VERSION "dbc-export 1 2026.26.6.5"

NS_ :

BS_:

BU_: ADSP APB APP APS APSB BB BMS CC CMP CMPD CP DAS DI DIF DIR DPB EPAS3P EPAS3S EPASTP EPASTS EPBL EPBR ESP EVSE FC GTW HCML HCMR HVP IBST ICR IDB LS OCS1P PARK PCS PCS2 PM PMF PMR PNCD PTC RADC RCM RCM2 RCM3 RCU SCCM SCM SCS SDCR TAS TCU TCU2 TPMS TRCM UI UIS UMC USM V2G VC VCBATT VCBATT0 VCBATT1 VCBATT2 VCCC VCFRONT VCFRONT1 VCFRONT2 VCLEFT VCRIGHT VCSEAT2L VCSEAT2R VCSEC VEH

BO_ 981 ESP_alertMatrix: 8 ESP
 SG_ ESP_matrixIndex M : 0|4@1+ (1,0) [0|15] "" Vector__XXX
 SG_ ESP_a001_ecuGenericFault m0 : 4|1@1+ (1,0) [0|1] "" Vector__XXX
 SG_ ESP_a002_valvesGenericFault m0 : 5|1@1+ (1,0) [0|1] "" Vector__XXX
 SG_ ESP_a003_outletValvesFault m0 : 6|1@1+ (1,0) [0|1] "" Vector__XXX
 SG_ ESP_a004_inletValvesFault m0 : 7|1@1+ (1,0) [0|1] "" Vector__XXX
 SG_ ESP_a005_HSVValvesFault m0 : 8|1@1+ (1,0) [0|1] "" Vector__XXX
 SG_ ESP_a006_USVValvesFault m0 : 9|1@1+ (1,0) [0|1] "" Vector__XXX
 SG_ ESP_a007_pumpMotorFault m0 : 10|1@1+ (1,0) [0|1] "" Vector__XXX
 SG_ ESP_a008_pumpMotor12VsupplyLow m0 : 11|1@1+ (1,0) [0|1] "" Vector__XXX
 SG_ ESP_a009_12VHardUndervoltage m0 : 12|1@1+ (1,0) [0|1] "" Vector__XXX
 SG_ ESP_a010_12VUndervoltage m0 : 13|1@1+ (1,0) [0|1] "" Vector__XXX
 SG_ ESP_a011_12VSystemUndervoltage m0 : 14|1@1+ (1,0) [0|1] "" Vector__XXX
 SG_ ESP_a012_netUndervoltage m0 : 15|1@1+ (1,0) [0|1] "" Vector__XXX
 SG_ ESP_a013_valveRelayUndervoltage m0 : 16|1@1+ (1,0) [0|1] "" Vector__XXX
 SG_ ESP_a014_WSSSupplyUndervoltage m0 : 17|1@1+ (1,0) [0|1] "" Vector__XXX
 SG_ ESP_a015_12VSupplyOvervoltage m0 : 18|1@1+ (1,0) [0|1] "" Vector__XXX
 SG_ ESP_a016_12VSystemOvervoltage m0 : 19|1@1+ (1,0) [0|1] "" Vector__XXX
 SG_ ESP_a017_netOvervoltage m0 : 20|1@1+ (1,0) [0|1] "" Vector__XXX
 SG_ ESP_a018_WSSSignFrontAxle m0 : 21|1@1+ (1,0) [0|1] "" Vector__XXX
 SG_ ESP_a019_WSSSignRearAxle m0 : 22|1@1+ (1,0) [0|1] "" Vector__XXX
 SG_ ESP_a020_WSSGenericTempFault m0 : 23|1@1+ (1,0) [0|1] "" Vector__XXX
 SG_ ESP_a021_WSSGeneralVDiffFault m0 : 24|1@1+ (1,0) [0|1] "" Vector__XXX
 SG_ ESP_a022_WSSDirectionFault m0 : 25|1@1+ (1,0) [0|1] "" Vector__XXX
 SG_ ESP_a023_WSSSeveralSuspected m0 : 26|1@1+ (1,0) [0|1] "" Vector__XXX
 SG_ ESP_a024_WSSReverseCurrent m0 : 27|1@1+ (1,0) [0|1] "" Vector__XXX
 SG_ ESP_a025_FrLWSSOpenOrShortToGnd m0 : 28|1@1+ (1,0) [0|1] "" Vector__XXX
 SG_ ESP_a026_FrLWSSShortTo12V m0 : 29|1@1+ (1,0) [0|1] "" Vector__XXX
 SG_ ESP_a027_FrLWSSLineInterruption m0 : 30|1@1+ (1,0) [0|1] "" Vector__XXX
 SG_ ESP_a028_FrLWSSMaxSpeedExceeded m0 : 31|1@1+ (1,0) [0|1] "" Vector__XXX
 SG_ ESP_a029_FrLWSSTooManyPulses m0 : 32|1@1+ (1,0) [0|1] "" Vector__XXX
 SG_ ESP_a030_FrLWSSLostSignal m0 : 33|1@1+ (1,0) [0|1] "" Vector__XXX
 SG_ ESP_a031_FrLWSSNoPulsesDetected m0 : 34|1@1+ (1,0) [0|1] "" Vector__XXX
 SG_ ESP_a032_FrLWSSWrongSensorType m0 : 35|1@1+ (1,0) [0|1] "" Vector__XXX
 SG_ ESP_a033_FrLWSSSignalNoise m0 : 36|1@1+ (1,0) [0|1] "" Vector__XXX
 SG_ ESP_a034_FrLWSSVDiffFault m0 : 37|1@1+ (1,0) [0|1] "" Vector__XXX
 SG_ ESP_a035_FrLWSSDirectionFault m0 : 38|1@1+ (1,0) [0|1] "" Vector__XXX
 SG_ ESP_a036_FrLWSSLargeAirGap m0 : 39|1@1+ (1,0) [0|1] "" Vector__XXX
 SG_ ESP_a037_FrLWSSSupplyShortToGnd m0 : 40|1@1+ (1,0) [0|1] "" Vector__XXX
 SG_ ESP_a038_FrLWSSGeneralFault m0 : 41|1@1+ (1,0) [0|1] "" Vector__XXX
 SG_ ESP_a039_FrRWSSOpenOrShortToGnd m0 : 42|1@1+ (1,0) [0|1] "" Vector__XXX
 SG_ ESP_a040_FrRWSSShortTo12V m0 : 43|1@1+ (1,0) [0|1] "" Vector__XXX
 SG_ ESP_a041_FrRWSSLineInterruption m0 : 44|1@1+ (1,0) [0|1] "" Vector__XXX
 SG_ ESP_a042_FrRWSSMaxSpeedExceeded m0 : 45|1@1+ (1,0) [0|1] "" Vector__XXX
 SG_ ESP_a043_FrRWSSTooManyPulses m0 : 46|1@1+ (1,0) [0|1] "" Vector__XXX
 SG_ ESP_a044_FrRWSSLostSignal m0 : 47|1@1+ (1,0) [0|1] "" Vector__XXX
 SG_ ESP_a045_FrRWSSNoPulsesDetected m0 : 48|1@1+ (1,0) [0|1] "" Vector__XXX
 SG_ ESP_a046_FrRWSSWrongSensorType m0 : 49|1@1+ (1,0) [0|1] "" Vector__XXX
 SG_ ESP_a047_FrRWSSSignalNoise m0 : 50|1@1+ (1,0) [0|1] "" Vector__XXX
 SG_ ESP_a048_FrRWSSVDiffFault m0 : 51|1@1+ (1,0) [0|1] "" Vector__XXX
 SG_ ESP_a049_FrRWSSDirectionFault m0 : 52|1@1+ (1,0) [0|1] "" Vector__XXX
 SG_ ESP_a050_FrRWSSLargeAirGap m0 : 53|1@1+ (1,0) [0|1] "" Vector__XXX
 SG_ ESP_a051_FrRWSSSupplyShortToGnd m0 : 54|1@1+ (1,0) [0|1] "" Vector__XXX
 SG_ ESP_a052_FrRWSSGeneralFault m0 : 55|1@1+ (1,0) [0|1] "" Vector__XXX
 SG_ ESP_a053_ReLWSSOpenOrShortToGnd m0 : 56|1@1+ (1,0) [0|1] "" Vector__XXX
 SG_ ESP_a054_ReLWSSShortTo12V m0 : 57|1@1+ (1,0) [0|1] "" Vector__XXX
 SG_ ESP_a055_ReLWSSLineInterruption m0 : 58|1@1+ (1,0) [0|1] "" Vector__XXX
 SG_ ESP_a056_ReLWSSMaxSpeedExceeded m0 : 59|1@1+ (1,0) [0|1] "" Vector__XXX
 SG_ ESP_a057_ReLWSSTooManyPulses m0 : 60|1@1+ (1,0) [0|1] "" Vector__XXX
 SG_ ESP_a058_ReLWSSLostSignal m0 : 61|1@1+ (1,0) [0|1] "" Vector__XXX
 SG_ ESP_a059_ReLWSSNoPulsesDetected m0 : 62|1@1+ (1,0) [0|1] "" Vector__XXX
 SG_ ESP_a060_ReLWSSWrongSensorType m0 : 63|1@1+ (1,0) [0|1] "" Vector__XXX
 SG_ ESP_a061_ReLWSSSignalNoise m1 : 4|1@1+ (1,0) [0|1] "" Vector__XXX
 SG_ ESP_a062_ReLWSSVDiffFault m1 : 5|1@1+ (1,0) [0|1] "" Vector__XXX
 SG_ ESP_a063_ReLWSSDirectionFault m1 : 6|1@1+ (1,0) [0|1] "" Vector__XXX
 SG_ ESP_a064_ReLWSSLargeAirGap m1 : 7|1@1+ (1,0) [0|1] "" Vector__XXX
 SG_ ESP_a065_ReLWSSSupplyShortToGnd m1 : 8|1@1+ (1,0) [0|1] "" Vector__XXX
 SG_ ESP_a066_ReLWSSGeneralFault m1 : 9|1@1+ (1,0) [0|1] "" Vector__XXX
 SG_ ESP_a067_ReRWSSOpenOrShortToGnd m1 : 10|1@1+ (1,0) [0|1] "" Vector__XXX
 SG_ ESP_a068_ReRWSSShortTo12V m1 : 11|1@1+ (1,0) [0|1] "" Vector__XXX
 SG_ ESP_a069_ReRWSSLineInterruption m1 : 12|1@1+ (1,0) [0|1] "" Vector__XXX
 SG_ ESP_a070_ReRWSSMaxSpeedExceeded m1 : 13|1@1+ (1,0) [0|1] "" Vector__XXX
 SG_ ESP_a071_ReRWSSTooManyPulses m1 : 14|1@1+ (1,0) [0|1] "" Vector__XXX
 SG_ ESP_a072_ReRWSSLostSignal m1 : 15|1@1+ (1,0) [0|1] "" Vector__XXX
 SG_ ESP_a073_ReRWSSNoPulsesDetected m1 : 16|1@1+ (1,0) [0|1] "" Vector__XXX
 SG_ ESP_a074_ReRWSSWrongSensorType m1 : 17|1@1+ (1,0) [0|1] "" Vector__XXX
 SG_ ESP_a075_ReRWSSSignalNoise m1 : 18|1@1+ (1,0) [0|1] "" Vector__XXX
 SG_ ESP_a076_ReRWSSVDiffFault m1 : 19|1@1+ (1,0) [0|1] "" Vector__XXX
 SG_ ESP_a077_ReRWSSDirectionFault m1 : 20|1@1+ (1,0) [0|1] "" Vector__XXX
 SG_ ESP_a078_ReRWSSLargeAirGap m1 : 21|1@1+ (1,0) [0|1] "" Vector__XXX
 SG_ ESP_a079_ReRWSSSupplyShortToGnd m1 : 22|1@1+ (1,0) [0|1] "" Vector__XXX
 SG_ ESP_a080_ReRWSSGeneralFault m1 : 23|1@1+ (1,0) [0|1] "" Vector__XXX
 SG_ ESP_a081_PressureSensorShort m1 : 24|1@1+ (1,0) [0|1] "" Vector__XXX
 SG_ ESP_a082_PMCSensorOffsetHigh m1 : 25|1@1+ (1,0) [0|1] "" Vector__XXX
 SG_ ESP_a083_PMCSensorFault m1 : 26|1@1+ (1,0) [0|1] "" Vector__XXX
 SG_ ESP_a084_BrakeFluidReservoirLow m1 : 27|1@1+ (1,0) [0|1] "" Vector__XXX
 SG_ ESP_a085_BrakeSwitchStuckHigh m1 : 28|1@1+ (1,0) [0|1] "" Vector__XXX
 SG_ ESP_a086_BrakeSwitchImplausible1 m1 : 29|1@1+ (1,0) [0|1] "" Vector__XXX
 SG_ ESP_a087_BrakeSwitchImplausible3 m1 : 30|1@1+ (1,0) [0|1] "" Vector__XXX
 SG_ ESP_a088_absContinuousControl m1 : 31|1@1+ (1,0) [0|1] "" Vector__XXX
 SG_ ESP_a089_absNoPressureIncrease m1 : 32|1@1+ (1,0) [0|1] "" Vector__XXX
 SG_ ESP_a090_vdcContinuousControl m1 : 33|1@1+ (1,0) [0|1] "" Vector__XXX
 SG_ ESP_a091_CANUndervoltage m1 : 34|1@1+ (1,0) [0|1] "" Vector__XXX
 SG_ ESP_a092_CANOvervoltage m1 : 35|1@1+ (1,0) [0|1] "" Vector__XXX
 SG_ ESP_a093_partyBusOff m1 : 36|1@1+ (1,0) [0|1] "" Vector__XXX
 SG_ ESP_a094_partyBusPassive m1 : 37|1@1+ (1,0) [0|1] "" Vector__XXX
 SG_ ESP_a095_chassisBusOff m1 : 38|1@1+ (1,0) [0|1] "" Vector__XXX
 SG_ ESP_a096_chassisBusPassive m1 : 39|1@1+ (1,0) [0|1] "" Vector__XXX
 SG_ ESP_a097_tcsRefSpeedNotInit m1 : 40|1@1+ (1,0) [0|1] "" Vector__XXX
 SG_ ESP_a098_vdcRefSpeedNotInit m1 : 41|1@1+ (1,0) [0|1] "" Vector__XXX
 SG_ ESP_a099_brakeTempModelOverheat m1 : 42|1@1+ (1,0) [0|1] "" Vector__XXX
 SG_ ESP_a100_brakeTempModelDisabled m1 : 43|1@1+ (1,0) [0|1] "" Vector__XXX
 SG_ ESP_a101_ebdFault m1 : 44|1@1+ (1,0) [0|1] "" Vector__XXX
 SG_ ESP_a102_absFault m1 : 45|1@1+ (1,0) [0|1] "" Vector__XXX
 SG_ ESP_a103_stabilityControlFault m1 : 46|1@1+ (1,0) [0|1] "" Vector__XXX
 SG_ ESP_a104_hbcEnabled m1 : 47|1@1+ (1,0) [0|1] "" Vector__XXX
 SG_ ESP_a105_ebrFault m1 : 48|1@1+ (1,0) [0|1] "" Vector__XXX
 SG_ ESP_a106_vdcActuatorFault m1 : 49|1@1+ (1,0) [0|1] "" Vector__XXX
 SG_ ESP_a107_reserved107 m1 : 50|1@1+ (1,0) [0|1] "" Vector__XXX
 SG_ ESP_a108_reserved108 m1 : 51|1@1+ (1,0) [0|1] "" Vector__XXX
 SG_ ESP_a109_reserved109 m1 : 52|1@1+ (1,0) [0|1] "" Vector__XXX
 SG_ ESP_a110_rollerBenchActive m1 : 53|1@1+ (1,0) [0|1] "" Vector__XXX
 SG_ ESP_a111_absActive m1 : 54|1@1+ (1,0) [0|1] "" Vector__XXX
 SG_ ESP_a112_espActive m1 : 55|1@1+ (1,0) [0|1] "" Vector__XXX
 SG_ ESP_a113_btcActive m1 : 56|1@1+ (1,0) [0|1] "" Vector__XXX
 SG_ ESP_a114_tvdcActive m1 : 57|1@1+ (1,0) [0|1] "" Vector__XXX
 SG_ ESP_a115_ebdActive m1 : 58|1@1+ (1,0) [0|1] "" Vector__XXX
 SG_ ESP_a116_tsmActive m1 : 59|1@1+ (1,0) [0|1] "" Vector__XXX
 SG_ ESP_a117_hbaActive m1 : 60|1@1+ (1,0) [0|1] "" Vector__XXX
 SG_ ESP_a118_hfcActive m1 : 61|1@1+ (1,0) [0|1] "" Vector__XXX
 SG_ ESP_a119_hbbActive m1 : 62|1@1+ (1,0) [0|1] "" Vector__XXX
 SG_ ESP_a120_rmiActive m1 : 63|1@1+ (1,0) [0|1] "" Vector__XXX
 SG_ ESP_a121_regenTcActive m2 : 4|1@1+ (1,0) [0|1] "" Vector__XXX
 SG_ ESP_a122_bdwActive m2 : 5|1@1+ (1,0) [0|1] "" Vector__XXX
 SG_ ESP_a123_ebrActive m2 : 6|1@1+ (1,0) [0|1] "" Vector__XXX
 SG_ ESP_a124_ebrSkidActive m2 : 7|1@1+ (1,0) [0|1] "" Vector__XXX
 SG_ ESP_a125_reserved125 m2 : 8|1@1+ (1,0) [0|1] "" Vector__XXX
 SG_ ESP_a126_reserved126 m2 : 9|1@1+ (1,0) [0|1] "" Vector__XXX
 SG_ ESP_a127_reserved127 m2 : 10|1@1+ (1,0) [0|1] "" Vector__XXX
 SG_ ESP_a128_reserved128 m2 : 11|1@1+ (1,0) [0|1] "" Vector__XXX
 SG_ ESP_a129_reserved129 m2 : 12|1@1+ (1,0) [0|1] "" Vector__XXX
 SG_ ESP_a130_EPAS3PsysStatusTimeout m2 : 13|1@1+ (1,0) [0|1] "" Vector__XXX
 SG_ ESP_a131_EPAS3PsysStatusDLC m2 : 14|1@1+ (1,0) [0|1] "" Vector__XXX
 SG_ ESP_a132_EPAS3PsysStatusChecksum m2 : 15|1@1+ (1,0) [0|1] "" Vector__XXX
 SG_ ESP_a133_EPAS3PsysStatusCounter m2 : 16|1@1+ (1,0) [0|1] "" Vector__XXX
 SG_ ESP_a134_steeringAngleInvalid m2 : 17|1@1+ (1,0) [0|1] "" Vector__XXX
 SG_ ESP_a135_steeringAngleNoCenter m2 : 18|1@1+ (1,0) [0|1] "" Vector__XXX
 SG_ ESP_a136_steeringAngleFrozen m2 : 19|1@1+ (1,0) [0|1] "" Vector__XXX
 SG_ ESP_a137_steeringOffsetTooLarge m2 : 20|1@1+ (1,0) [0|1] "" Vector__XXX
 SG_ ESP_a138_steeringAngleImplaus m2 : 21|1@1+ (1,0) [0|1] "" Vector__XXX
 SG_ ESP_a139_steeringAngleWrongSign m2 : 22|1@1+ (1,0) [0|1] "" Vector__XXX
 SG_ ESP_a140_RCMInertial1Timeout m2 : 23|1@1+ (1,0) [0|1] "" Vector__XXX
 SG_ ESP_a141_RCMInertial1DLC m2 : 24|1@1+ (1,0) [0|1] "" Vector__XXX
 SG_ ESP_a142_RCMInertial1Checksum m2 : 25|1@1+ (1,0) [0|1] "" Vector__XXX
 SG_ ESP_a143_RCMInertial1Counter m2 : 26|1@1+ (1,0) [0|1] "" Vector__XXX
 SG_ ESP_a144_yawMaxLatency m2 : 27|1@1+ (1,0) [0|1] "" Vector__XXX
 SG_ ESP_a145_yawInitFault m2 : 28|1@1+ (1,0) [0|1] "" Vector__XXX
 SG_ ESP_a146_yawInvalidValue m2 : 29|1@1+ (1,0) [0|1] "" Vector__XXX
 SG_ ESP_a147_yawSensorNotAvailable m2 : 30|1@1+ (1,0) [0|1] "" Vector__XXX
 SG_ ESP_a148_yawSignalFault m2 : 31|1@1+ (1,0) [0|1] "" Vector__XXX
 SG_ ESP_a149_yawInvalidSign m2 : 32|1@1+ (1,0) [0|1] "" Vector__XXX
 SG_ ESP_a150_yawImplausible m2 : 33|1@1+ (1,0) [0|1] "" Vector__XXX
 SG_ ESP_a151_RCMInertial2Timeout m2 : 34|1@1+ (1,0) [0|1] "" Vector__XXX
 SG_ ESP_a152_RCMInertial2DLC m2 : 35|1@1+ (1,0) [0|1] "" Vector__XXX
 SG_ ESP_a153_RCMInertial2Checksum m2 : 36|1@1+ (1,0) [0|1] "" Vector__XXX
 SG_ ESP_a154_RCMInertial2Counter m2 : 37|1@1+ (1,0) [0|1] "" Vector__XXX
 SG_ ESP_a155_ayMaxLatency m2 : 38|1@1+ (1,0) [0|1] "" Vector__XXX
 SG_ ESP_a156_ayInitFault m2 : 39|1@1+ (1,0) [0|1] "" Vector__XXX
 SG_ ESP_a157_ayInvalidValue m2 : 40|1@1+ (1,0) [0|1] "" Vector__XXX
 SG_ ESP_a158_aySensorNotAvailable m2 : 41|1@1+ (1,0) [0|1] "" Vector__XXX
 SG_ ESP_a159_aySignalFault m2 : 42|1@1+ (1,0) [0|1] "" Vector__XXX
 SG_ ESP_a160_ayRangeExceeded m2 : 43|1@1+ (1,0) [0|1] "" Vector__XXX
 SG_ ESP_a161_ayOffsetExceeded m2 : 44|1@1+ (1,0) [0|1] "" Vector__XXX
 SG_ ESP_a162_ayImplausible m2 : 45|1@1+ (1,0) [0|1] "" Vector__XXX
 SG_ ESP_a163_axMaxLatency m2 : 46|1@1+ (1,0) [0|1] "" Vector__XXX
 SG_ ESP_a164_axInitFault m2 : 47|1@1+ (1,0) [0|1] "" Vector__XXX
 SG_ ESP_a165_axInvalidValue m2 : 48|1@1+ (1,0) [0|1] "" Vector__XXX
 SG_ ESP_a166_axSensorNotAvailable m2 : 49|1@1+ (1,0) [0|1] "" Vector__XXX
 SG_ ESP_a167_axSignalFault m2 : 50|1@1+ (1,0) [0|1] "" Vector__XXX
 SG_ ESP_a168_axRangeExceeded m2 : 51|1@1+ (1,0) [0|1] "" Vector__XXX
 SG_ ESP_a169_axOffsetExceeded m2 : 52|1@1+ (1,0) [0|1] "" Vector__XXX
 SG_ ESP_a170_axSignalFrozen m2 : 53|1@1+ (1,0) [0|1] "" Vector__XXX
 SG_ ESP_a171_axImplausible m2 : 54|1@1+ (1,0) [0|1] "" Vector__XXX
 SG_ ESP_a172_IBSTparty1Timeout m2 : 55|1@1+ (1,0) [0|1] "" Vector__XXX
 SG_ ESP_a173_IBSTparty1DLC m2 : 56|1@1+ (1,0) [0|1] "" Vector__XXX
 SG_ ESP_a174_IBSTparty1Checksum m2 : 57|1@1+ (1,0) [0|1] "" Vector__XXX
 SG_ ESP_a175_IBSTparty1Counter m2 : 58|1@1+ (1,0) [0|1] "" Vector__XXX
 SG_ ESP_a176_IBSTEBRNotAvailable m2 : 59|1@1+ (1,0) [0|1] "" Vector__XXX
 SG_ ESP_a177_IBSTOutputRodDrvInvalid m2 : 60|1@1+ (1,0) [0|1] "" Vector__XXX
 SG_ ESP_a178_IBSTOutputRodActInvalid m2 : 61|1@1+ (1,0) [0|1] "" Vector__XXX
 SG_ ESP_a179_IBSTparty2Timeout m2 : 62|1@1+ (1,0) [0|1] "" Vector__XXX
 SG_ ESP_a180_IBSTparty2Checksum m2 : 63|1@1+ (1,0) [0|1] "" Vector__XXX
 SG_ ESP_a181_IBSTparty2DLC m3 : 4|1@1+ (1,0) [0|1] "" Vector__XXX
 SG_ ESP_a182_IBSTparty2Counter m3 : 5|1@1+ (1,0) [0|1] "" Vector__XXX
 SG_ ESP_a183_IBSTStatusOff m3 : 6|1@1+ (1,0) [0|1] "" Vector__XXX
 SG_ ESP_a184_IBSTpRunoutInvalid m3 : 7|1@1+ (1,0) [0|1] "" Vector__XXX
 SG_ ESP_a185_IBSTFeedforwardBackup m3 : 8|1@1+ (1,0) [0|1] "" Vector__XXX
 SG_ ESP_a186_IBSTBrakeAppliedInvalid m3 : 9|1@1+ (1,0) [0|1] "" Vector__XXX
 SG_ ESP_a187_DIbtcRequestTimeout m3 : 10|1@1+ (1,0) [0|1] "" Vector__XXX
 SG_ ESP_a188_DIbtcRequestDLC m3 : 11|1@1+ (1,0) [0|1] "" Vector__XXX
 SG_ ESP_a189_DIbtcRequestChecksum m3 : 12|1@1+ (1,0) [0|1] "" Vector__XXX
 SG_ ESP_a190_DIbtcRequestCounter m3 : 13|1@1+ (1,0) [0|1] "" Vector__XXX
 SG_ ESP_a191_DIchassisControlTimeout m3 : 14|1@1+ (1,0) [0|1] "" Vector__XXX
 SG_ ESP_a192_DIchassisControlDLC m3 : 15|1@1+ (1,0) [0|1] "" Vector__XXX
 SG_ ESP_a193_DIchassisControlChecksu m3 : 16|1@1+ (1,0) [0|1] "" Vector__XXX
 SG_ ESP_a194_DIchassisControlCounter m3 : 17|1@1+ (1,0) [0|1] "" Vector__XXX
 SG_ ESP_a195_ptcStateInvalid m3 : 18|1@1+ (1,0) [0|1] "" Vector__XXX
 SG_ ESP_a196_DIsystemStatusTimeout m3 : 19|1@1+ (1,0) [0|1] "" Vector__XXX
 SG_ ESP_a197_DIsystemStatusDLC m3 : 20|1@1+ (1,0) [0|1] "" Vector__XXX
 SG_ ESP_a198_DIsystemStatusChecksum m3 : 21|1@1+ (1,0) [0|1] "" Vector__XXX
 SG_ ESP_a199_DIsystemStatusCounter m3 : 22|1@1+ (1,0) [0|1] "" Vector__XXX
 SG_ ESP_a200_reverseGearStuckHigh m3 : 23|1@1+ (1,0) [0|1] "" Vector__XXX
 SG_ ESP_a201_reverseGearStuckLow m3 : 24|1@1+ (1,0) [0|1] "" Vector__XXX
 SG_ ESP_a202_accelPedalInvalid m3 : 25|1@1+ (1,0) [0|1] "" Vector__XXX
 SG_ ESP_a203_DItorqueTimeout m3 : 26|1@1+ (1,0) [0|1] "" Vector__XXX
 SG_ ESP_a204_DItorqueDLC m3 : 27|1@1+ (1,0) [0|1] "" Vector__XXX
 SG_ ESP_a205_DItorqueChecksum m3 : 28|1@1+ (1,0) [0|1] "" Vector__XXX
 SG_ ESP_a206_DItorqueCounter m3 : 29|1@1+ (1,0) [0|1] "" Vector__XXX
 SG_ ESP_a207_DITorqueCommandInvalid m3 : 30|1@1+ (1,0) [0|1] "" Vector__XXX
 SG_ ESP_a208_DIRPMInvalid m3 : 31|1@1+ (1,0) [0|1] "" Vector__XXX
 SG_ ESP_a209_DITorqueActualInvalid m3 : 32|1@1+ (1,0) [0|1] "" Vector__XXX
 SG_ ESP_a210_DIStorqueTimeout m3 : 33|1@1+ (1,0) [0|1] "" Vector__XXX
 SG_ ESP_a211_DIStorqueDLC m3 : 34|1@1+ (1,0) [0|1] "" Vector__XXX
 SG_ ESP_a212_DIStorqueChecksum m3 : 35|1@1+ (1,0) [0|1] "" Vector__XXX
 SG_ ESP_a213_DIStorqueCounter m3 : 36|1@1+ (1,0) [0|1] "" Vector__XXX
 SG_ ESP_a214_DISTorqueCommandInvalid m3 : 37|1@1+ (1,0) [0|1] "" Vector__XXX
 SG_ ESP_a215_DISRPMInvalid m3 : 38|1@1+ (1,0) [0|1] "" Vector__XXX
 SG_ ESP_a216_DISTorqueActualInvalid m3 : 39|1@1+ (1,0) [0|1] "" Vector__XXX
 SG_ ESP_a217_DIvdcLeftTimeout m3 : 40|1@1+ (1,0) [0|1] "" Vector__XXX
 SG_ ESP_a218_DIvdcLeftDLC m3 : 41|1@1+ (1,0) [0|1] "" Vector__XXX
 SG_ ESP_a219_DIvdcLeftChecksum m3 : 42|1@1+ (1,0) [0|1] "" Vector__XXX
 SG_ ESP_a220_DIvdcLeftCounter m3 : 43|1@1+ (1,0) [0|1] "" Vector__XXX
 SG_ ESP_a221_DIvdcRightTimeout m3 : 44|1@1+ (1,0) [0|1] "" Vector__XXX
 SG_ ESP_a222_DIvdcRightDLC m3 : 45|1@1+ (1,0) [0|1] "" Vector__XXX
 SG_ ESP_a223_DIvdcRightChecksum m3 : 46|1@1+ (1,0) [0|1] "" Vector__XXX
 SG_ ESP_a224_DIvdcRightCounter m3 : 47|1@1+ (1,0) [0|1] "" Vector__XXX
 SG_ ESP_a225_configMismatch m3 : 48|1@1+ (1,0) [0|1] "" Vector__XXX
 SG_ ESP_a226_bdwRequestInvalid m3 : 49|1@1+ (1,0) [0|1] "" Vector__XXX
 SG_ ESP_a227_bdwRequestActiveInvalid m3 : 50|1@1+ (1,0) [0|1] "" Vector__XXX
 SG_ ESP_a228_GTWvinTimeout m3 : 51|1@1+ (1,0) [0|1] "" Vector__XXX
 SG_ ESP_a229_GTWvinDLC m3 : 52|1@1+ (1,0) [0|1] "" Vector__XXX
 SG_ ESP_a230_vinNotLearned m3 : 53|1@1+ (1,0) [0|1] "" Vector__XXX
 SG_ ESP_a231_storedVINMismatch m3 : 54|1@1+ (1,0) [0|1] "" Vector__XXX
 SG_ ESP_a232_PMstate2Timeout m3 : 55|1@1+ (1,0) [0|1] "" Vector__XXX
 SG_ ESP_a233_PMstate2Checksum m3 : 56|1@1+ (1,0) [0|1] "" Vector__XXX
 SG_ ESP_a234_PMstate2DLC m3 : 57|1@1+ (1,0) [0|1] "" Vector__XXX
 SG_ ESP_a235_PMstate2Counter m3 : 58|1@1+ (1,0) [0|1] "" Vector__XXX
 SG_ ESP_a236_ebrCommandStateInvalid m3 : 59|1@1+ (1,0) [0|1] "" Vector__XXX
 SG_ ESP_a237_vdcCommandStateInvalid m3 : 60|1@1+ (1,0) [0|1] "" Vector__XXX
 SG_ ESP_a238_UIodoTimeout m3 : 61|1@1+ (1,0) [0|1] "" Vector__XXX
 SG_ ESP_a239_UIodoDLC m3 : 62|1@1+ (1,0) [0|1] "" Vector__XXX
 SG_ ESP_a240_LVPowerStateTimeout m3 : 63|1@1+ (1,0) [0|1] "" Vector__XXX
 SG_ ESP_a241_LVPowerStateChecksum m4 : 4|1@1+ (1,0) [0|1] "" Vector__XXX
 SG_ ESP_a242_LVPowerStateDLC m4 : 5|1@1+ (1,0) [0|1] "" Vector__XXX
 SG_ ESP_a243_LVPowerStateCounter m4 : 6|1@1+ (1,0) [0|1] "" Vector__XXX
 SG_ ESP_a244_LVOffStateInvalid m4 : 7|1@1+ (1,0) [0|1] "" Vector__XXX
 SG_ ESP_a245_LVGoingDownStateInvalid m4 : 8|1@1+ (1,0) [0|1] "" Vector__XXX
 SG_ ESP_a246_VCFRONTsensorTimeout m4 : 9|1@1+ (1,0) [0|1] "" Vector__XXX
 SG_ ESP_a247_VCFRONTsensorDLC m4 : 10|1@1+ (1,0) [0|1] "" Vector__XXX
 SG_ ESP_a248_vdcBrkeTrqTarFrLInvalid m4 : 11|1@1+ (1,0) [0|1] "" Vector__XXX
 SG_ ESP_a249_vdcBrkeTrqTarFrRInvalid m4 : 12|1@1+ (1,0) [0|1] "" Vector__XXX
 SG_ ESP_a250_vdcBrkeTrqTarReLInvalid m4 : 13|1@1+ (1,0) [0|1] "" Vector__XXX
 SG_ ESP_a251_vdcBrkeTrqTarReRInvalid m4 : 14|1@1+ (1,0) [0|1] "" Vector__XXX
 SG_ ESP_a252_vdcWhlSlipLimFrLInvalid m4 : 15|1@1+ (1,0) [0|1] "" Vector__XXX
 SG_ ESP_a253_vdcWhlSlipLimFrRInvalid m4 : 16|1@1+ (1,0) [0|1] "" Vector__XXX
 SG_ ESP_a254_vdcWhlSlipLimReLInvalid m4 : 17|1@1+ (1,0) [0|1] "" Vector__XXX
 SG_ ESP_a255_vdcWhlSlipLimReRInvalid m4 : 18|1@1+ (1,0) [0|1] "" Vector__XXX
 SG_ ESP_a256_epbmStatusTimeout m4 : 19|1@1+ (1,0) [0|1] "" Vector__XXX
 SG_ ESP_a257_epbmStatusChecksum m4 : 20|1@1+ (1,0) [0|1] "" Vector__XXX
 SG_ ESP_a258_epbmStatusDLC m4 : 21|1@1+ (1,0) [0|1] "" Vector__XXX
 SG_ ESP_a259_epbmStatusCounter m4 : 22|1@1+ (1,0) [0|1] "" Vector__XXX
 SG_ ESP_a260_epblStatusTimeout m4 : 23|1@1+ (1,0) [0|1] "" Vector__XXX
 SG_ ESP_a261_epblStatusChecksum m4 : 24|1@1+ (1,0) [0|1] "" Vector__XXX
 SG_ ESP_a262_epblStatusDLC m4 : 25|1@1+ (1,0) [0|1] "" Vector__XXX
 SG_ ESP_a263_epblStatusCounter m4 : 26|1@1+ (1,0) [0|1] "" Vector__XXX
 SG_ ESP_a264_pumpSpeedLimitInvalid m4 : 27|1@1+ (1,0) [0|1] "" Vector__XXX
 SG_ ESP_a265_DIRELtorqueTimeout m4 : 28|1@1+ (1,0) [0|1] "" Vector__XXX
 SG_ ESP_a266_DIRELtorqueDLC m4 : 29|1@1+ (1,0) [0|1] "" Vector__XXX
 SG_ ESP_a267_DIRELtorqueChecksum m4 : 30|1@1+ (1,0) [0|1] "" Vector__XXX
 SG_ ESP_a268_DIRELtorqueCounter m4 : 31|1@1+ (1,0) [0|1] "" Vector__XXX
 SG_ ESP_a269_DIRELTorqueCommandInval m4 : 32|1@1+ (1,0) [0|1] "" Vector__XXX
 SG_ ESP_a270_DIRELRPMInvalid m4 : 33|1@1+ (1,0) [0|1] "" Vector__XXX
 SG_ ESP_a271_DIRELTorqueActualInvali m4 : 34|1@1+ (1,0) [0|1] "" Vector__XXX
 SG_ ESP_a272_DIRERtorqueTimeout m4 : 35|1@1+ (1,0) [0|1] "" Vector__XXX
 SG_ ESP_a273_DIRERtorqueDLC m4 : 36|1@1+ (1,0) [0|1] "" Vector__XXX
 SG_ ESP_a274_DIRERtorqueChecksum m4 : 37|1@1+ (1,0) [0|1] "" Vector__XXX
 SG_ ESP_a275_DIRERtorqueCounter m4 : 38|1@1+ (1,0) [0|1] "" Vector__XXX
 SG_ ESP_a276_DIRERTorqueCommandInval m4 : 39|1@1+ (1,0) [0|1] "" Vector__XXX
 SG_ ESP_a277_DIRERRPMInvalid m4 : 40|1@1+ (1,0) [0|1] "" Vector__XXX
 SG_ ESP_a278_DIRERTorqueActualInvali m4 : 41|1@1+ (1,0) [0|1] "" Vector__XXX
 SG_ ESP_a279_lifetimeManagementOverr m4 : 42|1@1+ (1,0) [0|1] "" Vector__XXX
 SG_ ESP_a280_trackModeABSEnabled m4 : 43|1@1+ (1,0) [0|1] "" Vector__XXX
 SG_ ESP_a281_trackModeABSdisabled m4 : 44|1@1+ (1,0) [0|1] "" Vector__XXX
 SG_ ESP_a282_trackModeABSRequestInva m4 : 45|1@1+ (1,0) [0|1] "" Vector__XXX
 SG_ ESP_a283_secondaryCollisionMitig m4 : 46|1@1+ (1,0) [0|1] "" Vector__XXX
 SG_ ESP_a284_scmRequestInvalidChecks m4 : 47|1@1+ (1,0) [0|1] "" Vector__XXX
 SG_ ESP_a285_scmRequestDLC m4 : 48|1@1+ (1,0) [0|1] "" Vector__XXX
 SG_ ESP_a286_hydroplaneDetected m4 : 49|1@1+ (1,0) [0|1] "" Vector__XXX
 SG_ ESP_a287_failedBrakeCircuitDetec m4 : 50|1@1+ (1,0) [0|1] "" Vector__XXX
 SG_ ESP_a288_leftBusOff m4 : 51|1@1+ (1,0) [0|1] "" Vector__XXX
 SG_ ESP_a289_leftBusPassive m4 : 52|1@1+ (1,0) [0|1] "" Vector__XXX
 SG_ ESP_a290_brakeBusOff m4 : 53|1@1+ (1,0) [0|1] "" Vector__XXX
 SG_ ESP_a291_brakeBusPassive m4 : 54|1@1+ (1,0) [0|1] "" Vector__XXX
 SG_ ESP_a292_PEPSstatusTimeout m4 : 55|1@1+ (1,0) [0|1] "" Vector__XXX
 SG_ ESP_a293_PEPSstatusDLC m4 : 56|1@1+ (1,0) [0|1] "" Vector__XXX
 SG_ ESP_a294_PEPSstatusChecksum m4 : 57|1@1+ (1,0) [0|1] "" Vector__XXX
 SG_ ESP_a295_PEPSstatusCounter m4 : 58|1@1+ (1,0) [0|1] "" Vector__XXX
 SG_ ESP_a296_roadWheelAngleHealthDeg m4 : 59|1@1+ (1,0) [0|1] "" Vector__XXX
 SG_ ESP_a297_roadWheelAngleHealthFau m4 : 60|1@1+ (1,0) [0|1] "" Vector__XXX
 SG_ ESP_a298_RSArearSteerStatusTimeo m4 : 61|1@1+ (1,0) [0|1] "" Vector__XXX
 SG_ ESP_a299_RSArearSteerStatusDLC m4 : 62|1@1+ (1,0) [0|1] "" Vector__XXX
 SG_ ESP_a300_RSArearSteerStatusCheck m4 : 63|1@1+ (1,0) [0|1] "" Vector__XXX
 SG_ ESP_a301_PEPSstatusCounter m5 : 4|1@1+ (1,0) [0|1] "" Vector__XXX
 SG_ ESP_a302_rearRoadWheelAngleHealt m5 : 5|1@1+ (1,0) [0|1] "" Vector__XXX
 SG_ ESP_a303_rearRoadWheelAngleHealt m5 : 6|1@1+ (1,0) [0|1] "" Vector__XXX
 SG_ ESP_a304_rearVCLVPowerStateTimeo m5 : 7|1@1+ (1,0) [0|1] "" Vector__XXX
 SG_ ESP_a305_rearVCLVPowerStateDLC m5 : 8|1@1+ (1,0) [0|1] "" Vector__XXX
 SG_ ESP_a306_rearVCLVPowerStateCheck m5 : 9|1@1+ (1,0) [0|1] "" Vector__XXX
 SG_ ESP_a307_rearVCLVPowerStateCount m5 : 10|1@1+ (1,0) [0|1] "" Vector__XXX
 SG_ ESP_a308_evacFillNotComplete m5 : 11|1@1+ (1,0) [0|1] "" Vector__XXX
 SG_ ESP_a309_factoryModeActive m5 : 12|1@1+ (1,0) [0|1] "" Vector__XXX
 SG_ ESP_a310_brakeLatencyReductionAc m5 : 13|1@1+ (1,0) [0|1] "" Vector__XXX
 SG_ ESP_a311_aesActive m5 : 14|1@1+ (1,0) [0|1] "" Vector__XXX
 SG_ ESP_a312_undefinedAlertDetected m5 : 15|1@1+ (1,0) [0|1] "" Vector__XXX
 SG_ ESP_a313_cdpRequestStateInvalid m5 : 16|1@1+ (1,0) [0|1] "" Vector__XXX
 SG_ ESP_a314_aesFault m5 : 17|1@1+ (1,0) [0|1] "" Vector__XXX
 SG_ ESP_a315_EMCBackup11Timeout m5 : 18|1@1+ (1,0) [0|1] "" Vector__XXX
 SG_ ESP_a316_EMCBackup11DLC m5 : 19|1@1+ (1,0) [0|1] "" Vector__XXX
 SG_ ESP_a317_EMCBackup11Checksum m5 : 20|1@1+ (1,0) [0|1] "" Vector__XXX
 SG_ ESP_a318_EMCBackup11Counter m5 : 21|1@1+ (1,0) [0|1] "" Vector__XXX
 SG_ ESP_a319_AES_BackupActuatorActiv m5 : 22|1@1+ (1,0) [0|1] "" Vector__XXX
 SG_ ESP_a320_DPB_actuator1Counter m5 : 23|1@1+ (1,0) [0|1] "" Vector__XXX
 SG_ ESP_a321_DPB_actuator1Checksum m5 : 24|1@1+ (1,0) [0|1] "" Vector__XXX
 SG_ ESP_a322_DPB_actuator1DLC m5 : 25|1@1+ (1,0) [0|1] "" Vector__XXX
 SG_ ESP_a323_DPB_actuator1Timeout m5 : 26|1@1+ (1,0) [0|1] "" Vector__XXX
 SG_ ESP_a324_DPB_actuator2Counter m5 : 27|1@1+ (1,0) [0|1] "" Vector__XXX
 SG_ ESP_a325_DPB_actuator2Checksum m5 : 28|1@1+ (1,0) [0|1] "" Vector__XXX
 SG_ ESP_a326_DPB_actuator2DLC m5 : 29|1@1+ (1,0) [0|1] "" Vector__XXX
 SG_ ESP_a327_DPB_actuator2Timeout m5 : 30|1@1+ (1,0) [0|1] "" Vector__XXX
 SG_ ESP_a328_DPB_actuator3Counter m5 : 31|1@1+ (1,0) [0|1] "" Vector__XXX
 SG_ ESP_a329_DPB_actuator3Checksum m5 : 32|1@1+ (1,0) [0|1] "" Vector__XXX
 SG_ ESP_a330_DPB_actuator3DLC m5 : 33|1@1+ (1,0) [0|1] "" Vector__XXX
 SG_ ESP_a331_DPB_actuator3Timeout m5 : 34|1@1+ (1,0) [0|1] "" Vector__XXX
 SG_ ESP_a332_PressureSensorValHigh m5 : 35|1@1+ (1,0) [0|1] "" Vector__XXX
 SG_ ESP_a333_ActCircuitNoPressure m5 : 36|1@1+ (1,0) [0|1] "" Vector__XXX
 SG_ ESP_a334_BrakePedalAppliedInvali m5 : 37|1@1+ (1,0) [0|1] "" Vector__XXX
 SG_ ESP_a335_LdmFxTarBrakeActInvalid m5 : 38|1@1+ (1,0) [0|1] "" Vector__XXX
 SG_ ESP_a336_FxTargetDriverInvalid m5 : 39|1@1+ (1,0) [0|1] "" Vector__XXX
 SG_ ESP_a337_pReductionPotentialInva m5 : 40|1@1+ (1,0) [0|1] "" Vector__XXX
 SG_ ESP_a338_pRunoutInvalid m5 : 41|1@1+ (1,0) [0|1] "" Vector__XXX
 SG_ ESP_a339_sInputRodInvalid m5 : 42|1@1+ (1,0) [0|1] "" Vector__XXX
 SG_ ESP_a340_RollerBenchMisuse m5 : 43|1@1+ (1,0) [0|1] "" Vector__XXX
 SG_ ESP_a341_EnhancedPressureBuildAc m5 : 44|1@1+ (1,0) [0|1] "" Vector__XXX
 SG_ ESP_a342_EnhancedPressureBuildNo m5 : 45|1@1+ (1,0) [0|1] "" Vector__XXX
 SG_ ESP_a343_EnhancedPressureBuildLt m5 : 46|1@1+ (1,0) [0|1] "" Vector__XXX
 SG_ ESP_a344_DIbrakeCommandCounter m5 : 47|1@1+ (1,0) [0|1] "" Vector__XXX
 SG_ ESP_a345_DIbrakeCommandChecksum m5 : 48|1@1+ (1,0) [0|1] "" Vector__XXX
 SG_ ESP_a346_DIbrakeCommandDLC m5 : 49|1@1+ (1,0) [0|1] "" Vector__XXX
 SG_ ESP_a347_DIbrakeCommandTimeout m5 : 50|1@1+ (1,0) [0|1] "" Vector__XXX
 SG_ ESP_a348_brakeCmdStateInvalid m5 : 51|1@1+ (1,0) [0|1] "" Vector__XXX
 SG_ ESP_a349_ForceLampToRed m5 : 52|1@1+ (1,0) [0|1] "" Vector__XXX
 SG_ ESP_a350_ActuatorOff m5 : 53|1@1+ (1,0) [0|1] "" Vector__XXX
 SG_ ESP_a351_ActuatorYellowLampReque m5 : 54|1@1+ (1,0) [0|1] "" Vector__XXX
 SG_ ESP_a352_ActuatorLDMFailure m5 : 55|1@1+ (1,0) [0|1] "" Vector__XXX
 SG_ ESP_a353_PressureSensorImplausHi m5 : 56|1@1+ (1,0) [0|1] "" Vector__XXX
 SG_ ESP_a354_HBCRequestInvalid m5 : 57|1@1+ (1,0) [0|1] "" Vector__XXX
 SG_ ESP_a355_RecuStatusActInvalid m5 : 58|1@1+ (1,0) [0|1] "" Vector__XXX
 SG_ ESP_a356_DIFAxleTorqueInvalid m5 : 59|1@1+ (1,0) [0|1] "" Vector__XXX
 SG_ ESP_a357_DIRAxleTorqueInvalid m5 : 60|1@1+ (1,0) [0|1] "" Vector__XXX
 SG_ ESP_a358_externalActuatorFallbac m5 : 61|1@1+ (1,0) [0|1] "" Vector__XXX
 SG_ ESP_a359_externalActuatorNoExtRe m5 : 62|1@1+ (1,0) [0|1] "" Vector__XXX
 SG_ ESP_a360_BBbrakeActuationTimeout m5 : 63|1@1+ (1,0) [0|1] "" Vector__XXX
 SG_ ESP_a361_BBbrakeActuationDLC m6 : 4|1@1+ (1,0) [0|1] "" Vector__XXX
 SG_ ESP_a362_BBbrakeActuationChecksu m6 : 5|1@1+ (1,0) [0|1] "" Vector__XXX
 SG_ ESP_a363_BBbrakeActuationCounter m6 : 6|1@1+ (1,0) [0|1] "" Vector__XXX
 SG_ ESP_a364_DIgearInvalid m6 : 7|1@1+ (1,0) [0|1] "" Vector__XXX
 SG_ ESP_a365_TCSInputQualityTooLow m6 : 8|1@1+ (1,0) [0|1] "" Vector__XXX
 SG_ ESP_a366_ActuatorBlendingModeReq m6 : 9|1@1+ (1,0) [0|1] "" Vector__XXX
 SG_ ESP_a367_CBDS_fillBufferThreshol m6 : 10|1@1+ (1,0) [0|1] "" Vector__XXX
 SG_ ESP_a368_CBDS_fmeInternalEvent m6 : 11|1@1+ (1,0) [0|1] "" Vector__XXX
 SG_ ESP_a369_LargeLeakageDetectedByD m6 : 12|1@1+ (1,0) [0|1] "" Vector__XXX
 SG_ ESP_a370_DPB_actuator4Timeout m6 : 13|1@1+ (1,0) [0|1] "" Vector__XXX
 SG_ ESP_a371_DPB_actuator4DLC m6 : 14|1@1+ (1,0) [0|1] "" Vector__XXX
 SG_ ESP_a372_DPB_actuator4Checksum m6 : 15|1@1+ (1,0) [0|1] "" Vector__XXX
 SG_ ESP_a373_DPB_actuator4Counter m6 : 16|1@1+ (1,0) [0|1] "" Vector__XXX
 SG_ ESP_a374_StatInvalid_DI_FullSNA m6 : 17|1@1+ (1,0) [0|1] "" Vector__XXX
 SG_ ESP_a375_PM_locStateCounter m6 : 18|1@1+ (1,0) [0|1] "" Vector__XXX
 SG_ ESP_a376_PM_locStateChecksum m6 : 19|1@1+ (1,0) [0|1] "" Vector__XXX
 SG_ ESP_a377_PM_locStateDLC m6 : 20|1@1+ (1,0) [0|1] "" Vector__XXX
 SG_ ESP_a378_PM_locStateTimeout m6 : 21|1@1+ (1,0) [0|1] "" Vector__XXX
 SG_ ESP_a379_DASredundantBrakingCont m6 : 22|1@1+ (1,0) [0|1] "" Vector__XXX
 SG_ ESP_a380_DASredundantBrakingCont m6 : 23|1@1+ (1,0) [0|1] "" Vector__XXX
 SG_ ESP_a381_DASredundantBrakingCont m6 : 24|1@1+ (1,0) [0|1] "" Vector__XXX
 SG_ ESP_a382_DASredundantBrakingCont m6 : 25|1@1+ (1,0) [0|1] "" Vector__XXX
 SG_ ESP_a383_DASredundantBrakingCont m6 : 26|1@1+ (1,0) [0|1] "" Vector__XXX
 SG_ ESP_a384_DASredundantBrakingCont m6 : 27|1@1+ (1,0) [0|1] "" Vector__XXX
 SG_ ESP_a385_DASredundantBrakingCont m6 : 28|1@1+ (1,0) [0|1] "" Vector__XXX
 SG_ ESP_a386_DASredundantBrakingCont m6 : 29|1@1+ (1,0) [0|1] "" Vector__XXX
 SG_ ESP_a387_DIlocStatus2Checksum m6 : 30|1@1+ (1,0) [0|1] "" Vector__XXX
 SG_ ESP_a388_DIlocStatus2Counter m6 : 31|1@1+ (1,0) [0|1] "" Vector__XXX
 SG_ ESP_a389_DIlocStatus2DLC m6 : 32|1@1+ (1,0) [0|1] "" Vector__XXX
 SG_ ESP_a390_DIlocStatus2Timeout m6 : 33|1@1+ (1,0) [0|1] "" Vector__XXX
 SG_ ESP_a391_standaloneEBRActive m6 : 34|1@1+ (1,0) [0|1] "" Vector__XXX
 SG_ ESP_a392_driverlessArmingUnavail m6 : 35|1@1+ (1,0) [0|1] "" Vector__XXX
 SG_ ESP_a393_EMCBackup21Checksum m6 : 36|1@1+ (1,0) [0|1] "" Vector__XXX
 SG_ ESP_a394_EMCBackup21Counter m6 : 37|1@1+ (1,0) [0|1] "" Vector__XXX
 SG_ ESP_a395_EMCBackup21DLC m6 : 38|1@1+ (1,0) [0|1] "" Vector__XXX
 SG_ ESP_a396_EMCBackup21Timeout m6 : 39|1@1+ (1,0) [0|1] "" Vector__XXX
 SG_ ESP_a397_epbrStatusTimeout m6 : 40|1@1+ (1,0) [0|1] "" Vector__XXX
 SG_ ESP_a398_epbrStatusChecksum m6 : 41|1@1+ (1,0) [0|1] "" Vector__XXX
 SG_ ESP_a399_epbrStatusDLC m6 : 42|1@1+ (1,0) [0|1] "" Vector__XXX
 SG_ ESP_a400_epbrStatusCounter m6 : 43|1@1+ (1,0) [0|1] "" Vector__XXX
 SG_ ESP_a401_bsmCircuitFailure m6 : 44|1@1+ (1,0) [0|1] "" Vector__XXX
 SG_ ESP_a402_bsmPtsPlausToPsTooHigh m6 : 45|1@1+ (1,0) [0|1] "" Vector__XXX
 SG_ ESP_a403_batMotorVoltage m6 : 46|1@1+ (1,0) [0|1] "" Vector__XXX
 SG_ ESP_a404_batPressureCircuit1 m6 : 47|1@1+ (1,0) [0|1] "" Vector__XXX
 SG_ ESP_a405_batPressureCircuit2 m6 : 48|1@1+ (1,0) [0|1] "" Vector__XXX
 SG_ ESP_a406_DIespActuatorTestTimeou m6 : 49|1@1+ (1,0) [0|1] "" Vector__XXX
 SG_ ESP_a407_DIespActuatorTestChecks m6 : 50|1@1+ (1,0) [0|1] "" Vector__XXX
 SG_ ESP_a408_DIespActuatorTestDLC m6 : 51|1@1+ (1,0) [0|1] "" Vector__XXX
 SG_ ESP_a409_DIespActuatorTestCounte m6 : 52|1@1+ (1,0) [0|1] "" Vector__XXX

BO_ 808 ESP_info: 8 ESP
 SG_ ESP_infoIndex M : 0|8@1+ (1,0) [0|255] "" Vector__XXX
 SG_ ESP_infoBuildType m10 : 8|8@1+ (1,0) [0|255] "" Vector__XXX
 SG_ ESP_vehFlashMode m10 : 24|1@1+ (1,0) [0|1] "" Vector__XXX
 SG_ ESP_infoComponentID m10 : 48|16@1+ (1,0) [0|65535] "" Vector__XXX
 SG_ ESP_infoPcbaID m11 : 16|8@1+ (1,0) [0|255] "" Vector__XXX
 SG_ ESP_infoAssemblyID m11 : 24|8@1+ (1,0) [0|255] "" Vector__XXX
 SG_ ESP_infoUsageID m11 : 32|16@1+ (1,0) [0|65535] "" Vector__XXX
 SG_ ESP_infoSubUsageID m11 : 48|16@1+ (1,0) [0|65535] "" Vector__XXX
 SG_ ESP_infoApplicationCRC m13 : 39|32@0+ (1,0) [0|4294967295] "" Vector__XXX
 SG_ ESP_infoVehicleVariant m16 : 16|8@1+ (1,0) [0|255] "" Vector__XXX
 SG_ ESP_infoSubcomponent1 m16 : 32|32@1+ (1,0) [0|4294967295] "" Vector__XXX
 SG_ ESP_infoBootUdsProtoVersion m20 : 8|8@1+ (1,0) [0|255] "" Vector__XXX
 SG_ ESP_infoBootloaderCRC m20 : 32|32@1+ (1,0) [0|4294967295] "" Vector__XXX
 SG_ ESP_infoVariantCRC m22 : 39|32@0+ (1,0) [0|4294967295] "" Vector__XXX

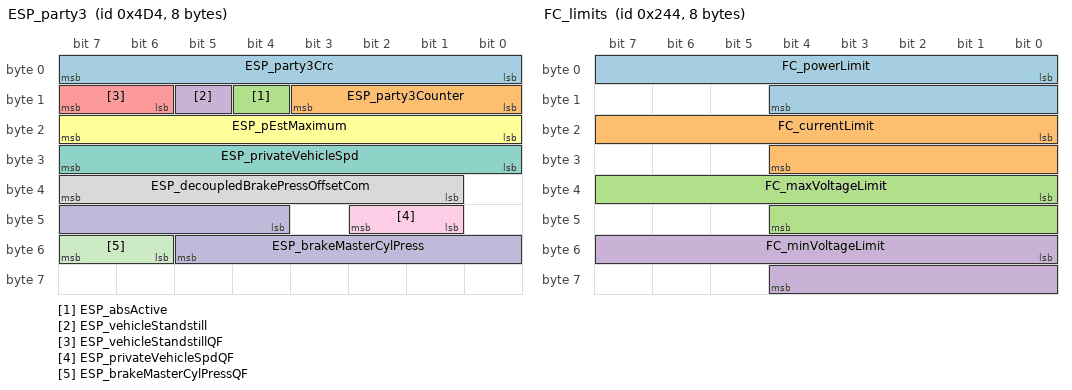
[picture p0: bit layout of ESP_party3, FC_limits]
BO_ 1236 ESP_party3: 8 ESP
 SG_ ESP_party3Crc : 0|8@1+ (1,0) [0|255] "" Vector__XXX
 SG_ ESP_party3Counter : 8|4@1+ (1,0) [0|15] "" Vector__XXX
 SG_ ESP_absActive : 12|1@1+ (1,0) [0|1] "" Vector__XXX
 SG_ ESP_vehicleStandstill : 13|1@1+ (1,0) [0|1] "" Vector__XXX
 SG_ ESP_vehicleStandstillQF : 14|2@1+ (1,0) [0|3] "" Vector__XXX
 SG_ ESP_pEstMaximum : 16|8@1+ (1,0) [0|255] "bar" Vector__XXX
 SG_ ESP_privateVehicleSpd : 24|8@1+ (0.4,0) [0|102] "m/s" Vector__XXX
 SG_ ESP_decoupledBrakePressOffsetCom : 33|7@1+ (0.25,-16) [-16|15.5] "bar" Vector__XXX
 SG_ ESP_privateVehicleSpdQF : 41|2@1+ (1,0) [0|3] "" Vector__XXX
 SG_ ESP_brakeMasterCylPress : 44|10@1+ (0.3,-30) [-30|276.6] "bar" Vector__XXX
 SG_ ESP_brakeMasterCylPressQF : 54|2@1+ (1,0) [0|3] "" Vector__XXX

BO_ 325 ESP_status: 8 ESP
 SG_ ESP_statusChecksum : 0|8@1+ (1,0) [0|255] "" Vector__XXX
 SG_ ESP_statusCounter : 8|4@1+ (1,0) [0|15] "" Vector__XXX
 SG_ ESP_espModeActive : 12|2@1+ (1,0) [0|3] "" Vector__XXX
 SG_ ESP_stabilityControlSts2 : 14|2@1+ (1,0) [0|3] "" Vector__XXX
 SG_ ESP_ebdFaultLamp : 16|1@1+ (1,0) [0|1] "" Vector__XXX
 SG_ ESP_absFaultLamp : 17|1@1+ (1,0) [0|1] "" Vector__XXX
 SG_ ESP_espFaultLamp : 18|1@1+ (1,0) [0|1] "" Vector__XXX
 SG_ ESP_hydraulicBoostEnabled : 19|1@1+ (1,0) [0|1] "" Vector__XXX
 SG_ ESP_espLampFlash : 20|1@1+ (1,0) [0|1] "" Vector__XXX
 SG_ ESP_brakeLamp : 21|1@1+ (1,0) [0|1] "" Vector__XXX
 SG_ ESP_absBrakeEvent2 : 22|2@1+ (1,0) [0|3] "" Vector__XXX
 SG_ ESP_longitudinalAccelQF : 24|1@1+ (1,0) [0|1] "" Vector__XXX
 SG_ ESP_lateralAccelQF : 25|1@1+ (1,0) [0|1] "" Vector__XXX
 SG_ ESP_yawRateQF : 26|1@1+ (1,0) [0|1] "" Vector__XXX
 SG_ ESP_steeringAngleQF : 27|1@1+ (1,0) [0|1] "" Vector__XXX
 SG_ ESP_brakeDiscWipingActive : 28|1@1+ (1,0) [0|1] "" Vector__XXX
 SG_ ESP_driverBrakeApply : 29|2@1+ (1,0) [0|3] "" Vector__XXX
 SG_ ESP_brakeApply : 31|1@1+ (1,0) [0|1] "" Vector__XXX
 SG_ ESP_aesPrimaryActuatorStatus : 32|2@1+ (1,0) [0|3] "" Vector__XXX
 SG_ ESP_cdpStatus : 34|2@1+ (1,0) [0|3] "" Vector__XXX
 SG_ ESP_ptcTargetState : 36|2@1+ (1,0) [0|3] "" Vector__XXX
 SG_ ESP_btcTargetState : 38|2@1+ (1,0) [0|3] "" Vector__XXX
 SG_ ESP_decoupledBrakePressEst : 40|8@1+ (1,-30) [-30|225] "bar" Vector__XXX
 SG_ ESP_ebrStandstillSkid : 48|1@1+ (1,0) [0|1] "" Vector__XXX
 SG_ ESP_ebrStatus : 49|2@1+ (1,0) [0|3] "" Vector__XXX
 SG_ ESP_brakeTorqueTarget : 51|13@1+ (3,0) [0|24573] "Nm" Vector__XXX

BO_ 1662 EVSE_isoTpToVeh: 8 EVSE
 SG_ EVSE_isoTpToVehData : 0|64@1+ (1,0) [0|1.84467440737e+19] "" Vector__XXX

BO_ 1322 FC_alertLog: 8 FC
 SG_ FC_alertID M : 0|15@1+ (1,0) [0|32767] "" Vector__XXX
 SG_ FC_alertType : 15|1@1+ (1,0) [0|1] "" Vector__XXX
 SG_ FC_a130_CA_flybackSwOvType m130 : 16|1@1+ (1,0) [0|1] "" Vector__XXX
 SG_ FC_a146_CA_flybackOnTime m146 : 16|16@1+ (0.0007629511,0) [0|50.0000003385] "" Vector__XXX
 SG_ FC_a146_CA_flybackV m146 : 32|16@1+ (0.0128332730383,0) [0|841.028548565] "" Vector__XXX
 SG_ FC_a146_CA_flybackTargetV m146 : 48|16@1+ (0.0128332730383,0) [0|841.028548565] "" Vector__XXX
 SG_ FC_a159_CA_wdtTaskList1 m159 : 16|16@1+ (1,0) [0|65535] "" Vector__XXX
 SG_ FC_a159_CA_wdtTaskList2 m159 : 32|16@1+ (1,0) [0|65535] "" Vector__XXX

BO_ 895 FC_alertMatrix3: 8 FC
 SG_ FC_a129_CA_flyback_HW_OC : 0|1@1+ (1,0) [0|1] "" Vector__XXX
 SG_ FC_a130_CA_flyback_SW_OV : 1|1@1+ (1,0) [0|1] "" Vector__XXX
 SG_ FC_a131_CA_flyback_HW_OV : 2|1@1+ (1,0) [0|1] "" Vector__XXX
 SG_ FC_a132_CA_bmsMia : 3|1@1+ (1,0) [0|1] "" Vector__XXX
 SG_ FC_a133_CA_evseMia : 4|1@1+ (1,0) [0|1] "" Vector__XXX
 SG_ FC_a134_CA_vehTxBufOvf : 5|1@1+ (1,0) [0|1] "" Vector__XXX
 SG_ FC_a135_CA_vehRxBufOvf : 6|1@1+ (1,0) [0|1] "" Vector__XXX
 SG_ FC_a136_CA_evseTxBufOvf : 7|1@1+ (1,0) [0|1] "" Vector__XXX
 SG_ FC_a137_CA_evseRxBufOvf : 8|1@1+ (1,0) [0|1] "" Vector__XXX
 SG_ FC_a138_CA_hwProxTrip : 9|1@1+ (1,0) [0|1] "" Vector__XXX
 SG_ FC_a139_CA_ss2NotLow : 10|1@1+ (1,0) [0|1] "" Vector__XXX
 SG_ FC_a140_CA_bmsIncompatible : 11|1@1+ (1,0) [0|1] "" Vector__XXX
 SG_ FC_a141_CA_vehConn_OT : 12|1@1+ (1,0) [0|1] "" Vector__XXX
 SG_ FC_a142_CA_evseConn_OT : 13|1@1+ (1,0) [0|1] "" Vector__XXX
 SG_ FC_a143_CA_pcb_OT : 14|1@1+ (1,0) [0|1] "" Vector__XXX
 SG_ FC_a144_CA_flybackUnstable : 15|1@1+ (1,0) [0|1] "" Vector__XXX
 SG_ FC_a145_CA_flybackDataStale : 16|1@1+ (1,0) [0|1] "" Vector__XXX
 SG_ FC_a146_CA_flybackBusLoadHi : 17|1@1+ (1,0) [0|1] "" Vector__XXX
 SG_ FC_a147_CA_vehConn_UT : 18|1@1+ (1,0) [0|1] "" Vector__XXX
 SG_ FC_a148_CA_evseConn_UT : 19|1@1+ (1,0) [0|1] "" Vector__XXX
 SG_ FC_a149_CA_pcb_UT : 20|1@1+ (1,0) [0|1] "" Vector__XXX
 SG_ FC_a150_CA_vehToEvseDeltaHi : 21|1@1+ (1,0) [0|1] "" Vector__XXX
 SG_ FC_a151_CA_vehToEvseDeltaLo : 22|1@1+ (1,0) [0|1] "" Vector__XXX
 SG_ FC_a152_CA_vehToPcbDeltaHi : 23|1@1+ (1,0) [0|1] "" Vector__XXX
 SG_ FC_a153_CA_evseToPcbDeltaHi : 24|1@1+ (1,0) [0|1] "" Vector__XXX
 SG_ FC_a154_CA_vehToPcbDeltaLo : 25|1@1+ (1,0) [0|1] "" Vector__XXX
 SG_ FC_a155_CA_evseToPcbDeltaLo : 26|1@1+ (1,0) [0|1] "" Vector__XXX
 SG_ FC_a156_CA_flybackRunTimeout : 27|1@1+ (1,0) [0|1] "" Vector__XXX
 SG_ FC_a157_CA_unused : 28|1@1+ (1,0) [0|1] "" Vector__XXX
 SG_ FC_a158_CA_evseOverCurrent : 29|1@1+ (1,0) [0|1] "" Vector__XXX
 SG_ FC_a159_CA_wdtExpired : 30|1@1+ (1,0) [0|1] "" Vector__XXX
 SG_ FC_a160_CA_ss2Deasserted : 31|1@1+ (1,0) [0|1] "" Vector__XXX
 SG_ FC_a161_CA_vehTempHiFoldBk : 32|1@1+ (1,0) [0|1] "" Vector__XXX
 SG_ FC_a162_CA_evseTempHiFoldBk : 33|1@1+ (1,0) [0|1] "" Vector__XXX
 SG_ FC_a163_CA_pcbTempHiFoldBk : 34|1@1+ (1,0) [0|1] "" Vector__XXX
 SG_ FC_a164_CA_proxDisconnected : 35|1@1+ (1,0) [0|1] "" Vector__XXX
 SG_ FC_a165_CA_evseConnUnlocked : 36|1@1+ (1,0) [0|1] "" Vector__XXX
 SG_ FC_a166_CA_vehConnUnlocked : 37|1@1+ (1,0) [0|1] "" Vector__XXX
 SG_ FC_a167_CA_isoVoltageLow : 38|1@1+ (1,0) [0|1] "" Vector__XXX
 SG_ FC_a168_CA_proxTimeout : 39|1@1+ (1,0) [0|1] "" Vector__XXX
 SG_ FC_a169_CA_pilotAcceptTimeout : 40|1@1+ (1,0) [0|1] "" Vector__XXX
 SG_ FC_a170_CA_vehDataTimeout : 41|1@1+ (1,0) [0|1] "" Vector__XXX
 SG_ FC_a171_CA_vehConLockTimeout : 42|1@1+ (1,0) [0|1] "" Vector__XXX
 SG_ FC_a172_CA_ss2LowTimeout : 43|1@1+ (1,0) [0|1] "" Vector__XXX
 SG_ FC_a173_CA_evseDataTimeout : 44|1@1+ (1,0) [0|1] "" Vector__XXX
 SG_ FC_a174_CA_vehReadyTimeout : 45|1@1+ (1,0) [0|1] "" Vector__XXX
 SG_ FC_a175_CA_evseIsoTestTimeout : 46|1@1+ (1,0) [0|1] "" Vector__XXX
 SG_ FC_a176_CA_chargingBusTimeout : 47|1@1+ (1,0) [0|1] "" Vector__XXX
 SG_ FC_a177_CA_bmsCtrCloseTimeout : 48|1@1+ (1,0) [0|1] "" Vector__XXX
 SG_ FC_a178_CA_evseStartTimeout : 49|1@1+ (1,0) [0|1] "" Vector__XXX
 SG_ FC_a179_CA_startupProblem : 50|1@1+ (1,0) [0|1] "" Vector__XXX
 SG_ FC_a180_CA_chargingProblem : 51|1@1+ (1,0) [0|1] "" Vector__XXX
 SG_ FC_a181_CA_vRegBrownout : 52|1@1+ (1,0) [0|1] "" Vector__XXX
 SG_ FC_a182_CA_evseChrMalfunc : 53|1@1+ (1,0) [0|1] "" Vector__XXX
 SG_ FC_a183_CA_evseBatIncompat : 54|1@1+ (1,0) [0|1] "" Vector__XXX
 SG_ FC_a184_CA_evseBatMalfunc : 55|1@1+ (1,0) [0|1] "" Vector__XXX
 SG_ FC_a185_CA_vehReadyDeasserted : 56|1@1+ (1,0) [0|1] "" Vector__XXX
 SG_ FC_a186_CA_fcContOpenTimeout : 57|1@1+ (1,0) [0|1] "" Vector__XXX
 SG_ FC_a187_CA_evseConLockTimeout : 58|1@1+ (1,0) [0|1] "" Vector__XXX

BO_ 927 FC_alertMatrix4: 8 FC
 SG_ FC_a193_FCAlertPlaceholder : 0|1@1+ (1,0) [0|1] "" Vector__XXX

BO_ 958 FC_alertMatrix5: 8 FC
 SG_ FC_a257_GB_bmsMia : 0|1@1+ (1,0) [0|1] "" Vector__XXX
 SG_ FC_a258_GB_evseMia : 1|1@1+ (1,0) [0|1] "" Vector__XXX
 SG_ FC_a259_GB_vehTxBufOvf : 2|1@1+ (1,0) [0|1] "" Vector__XXX
 SG_ FC_a260_GB_vehRxBufOvf : 3|1@1+ (1,0) [0|1] "" Vector__XXX
 SG_ FC_a261_GB_evseTxBufOvf : 4|1@1+ (1,0) [0|1] "" Vector__XXX
 SG_ FC_a262_GB_evseRxBufOvf : 5|1@1+ (1,0) [0|1] "" Vector__XXX
 SG_ FC_a263_GB_hwProxTrip : 6|1@1+ (1,0) [0|1] "" Vector__XXX
 SG_ FC_a264_GB_timeoutCHM : 7|1@1+ (1,0) [0|1] "" Vector__XXX
 SG_ FC_a265_GB_bmsIncompatible : 8|1@1+ (1,0) [0|1] "" Vector__XXX
 SG_ FC_a266_GB_negPin_OT : 9|1@1+ (1,0) [0|1] "" Vector__XXX
 SG_ FC_a267_GB_posPin_OT : 10|1@1+ (1,0) [0|1] "" Vector__XXX
 SG_ FC_a268_GB_pcb_OT : 11|1@1+ (1,0) [0|1] "" Vector__XXX
 SG_ FC_a269_GB_timeoutCRM : 12|1@1+ (1,0) [0|1] "" Vector__XXX
 SG_ FC_a270_GB_timeoutCML : 13|1@1+ (1,0) [0|1] "" Vector__XXX
 SG_ FC_a271_GB_timeoutCRO : 14|1@1+ (1,0) [0|1] "" Vector__XXX
 SG_ FC_a272_GB_negToPosDeltaHi : 15|1@1+ (1,0) [0|1] "" Vector__XXX
 SG_ FC_a273_GB_negToPosDeltaLo : 16|1@1+ (1,0) [0|1] "" Vector__XXX
 SG_ FC_a274_GB_negToPcbDeltaHi : 17|1@1+ (1,0) [0|1] "" Vector__XXX
 SG_ FC_a275_GB_posToPcbDeltaHi : 18|1@1+ (1,0) [0|1] "" Vector__XXX
 SG_ FC_a276_GB_negToPcbDeltaLo : 19|1@1+ (1,0) [0|1] "" Vector__XXX
 SG_ FC_a277_GB_posToPcbDeltaLo : 20|1@1+ (1,0) [0|1] "" Vector__XXX
 SG_ FC_a278_GB_timeoutCCS : 21|1@1+ (1,0) [0|1] "" Vector__XXX
 SG_ FC_a279_GB_evseOverCurrent : 22|1@1+ (1,0) [0|1] "" Vector__XXX
 SG_ FC_a280_GB_retryLimitExceeded : 23|1@1+ (1,0) [0|1] "" Vector__XXX
 SG_ FC_a281_GB_evseOutOfService : 24|1@1+ (1,0) [0|1] "" Vector__XXX
 SG_ FC_a282_GB_negTempHiFoldBk : 25|1@1+ (1,0) [0|1] "" Vector__XXX
 SG_ FC_a283_GB_posTempHiFoldBk : 26|1@1+ (1,0) [0|1] "" Vector__XXX
 SG_ FC_a284_GB_pcbTempHiFoldBk : 27|1@1+ (1,0) [0|1] "" Vector__XXX
 SG_ FC_a285_GB_proxDisconnected : 28|1@1+ (1,0) [0|1] "" Vector__XXX
 SG_ FC_a286_GB_evseConnUnlocked : 29|1@1+ (1,0) [0|1] "" Vector__XXX
 SG_ FC_a287_GB_vehConnUnlocked : 30|1@1+ (1,0) [0|1] "" Vector__XXX
 SG_ FC_a288_GB_evseAbnormalStopReq : 31|1@1+ (1,0) [0|1] "" Vector__XXX
 SG_ FC_a289_GB_proxTimeout : 32|1@1+ (1,0) [0|1] "" Vector__XXX
 SG_ FC_a290_GB_pilotAcceptTimeout : 33|1@1+ (1,0) [0|1] "" Vector__XXX
 SG_ FC_a291_GB_vehDataTimeout : 34|1@1+ (1,0) [0|1] "" Vector__XXX
 SG_ FC_a292_GB_vehConLockTimeout : 35|1@1+ (1,0) [0|1] "" Vector__XXX
 SG_ FC_a293_GB_proxRationality : 36|1@1+ (1,0) [0|1] "" Vector__XXX
 SG_ FC_a294_GB_unused : 37|1@1+ (1,0) [0|1] "" Vector__XXX
 SG_ FC_a295_GB_pilotRationality : 38|1@1+ (1,0) [0|1] "" Vector__XXX
 SG_ FC_a296_GB_invalidPilotTransitio : 39|1@1+ (1,0) [0|1] "" Vector__XXX
 SG_ FC_a297_GB_unused : 40|1@1+ (1,0) [0|1] "" Vector__XXX
 SG_ FC_a298_GB_bmsCtrCloseTimeout : 41|1@1+ (1,0) [0|1] "" Vector__XXX
 SG_ FC_a299_GB_evseReadyTimeout : 42|1@1+ (1,0) [0|1] "" Vector__XXX
 SG_ FC_a300_GB_unused : 43|1@1+ (1,0) [0|1] "" Vector__XXX
 SG_ FC_a301_GB_unused : 44|1@1+ (1,0) [0|1] "" Vector__XXX
 SG_ FC_a302_GB_unused : 45|1@1+ (1,0) [0|1] "" Vector__XXX
 SG_ FC_a303_GB_negRecogTimeout : 46|1@1+ (1,0) [0|1] "" Vector__XXX
 SG_ FC_a304_GB_unused : 47|1@1+ (1,0) [0|1] "" Vector__XXX
 SG_ FC_a305_GB_posRecogTimeout : 48|1@1+ (1,0) [0|1] "" Vector__XXX
 SG_ FC_a306_GB_vehReadyDeasserted : 49|1@1+ (1,0) [0|1] "" Vector__XXX
 SG_ FC_a307_GB_fcContOpenTimeout : 50|1@1+ (1,0) [0|1] "" Vector__XXX
 SG_ FC_a308_GB_evseConLockTimeout : 51|1@1+ (1,0) [0|1] "" Vector__XXX
 SG_ FC_a309_GB_unused : 52|1@1+ (1,0) [0|1] "" Vector__XXX
 SG_ FC_a310_GB_unused : 53|1@1+ (1,0) [0|1] "" Vector__XXX
 SG_ FC_a311_GB_battParamsTimeout : 54|1@1+ (1,0) [0|1] "" Vector__XXX
 SG_ FC_a312_GB_evseLimitsTimeout : 55|1@1+ (1,0) [0|1] "" Vector__XXX
 SG_ FC_a313_GB_inputVoltageRailOv : 56|1@1+ (1,0) [0|1] "" Vector__XXX

BO_ 990 FC_alertMatrix6: 8 FC
 SG_ FC_a321_FCAlertPlaceholder : 0|1@1+ (1,0) [0|1] "" Vector__XXX

BO_ 1117 FC_evseBilling: 8 FC
 SG_ FC_evseBillingDataSelect M : 0|1@1+ (1,0) [0|1] "" Vector__XXX
 SG_ FC_evseBillingEnergy m0 : 4|20@1+ (0.001,0) [0|1048.575] "kWh" Vector__XXX
 SG_ FC_evseMeterPower m0 : 24|20@1+ (0.001,0) [0|1048.575] "kW" Vector__XXX
 SG_ FC_evseMeterCurrent m0 : 44|10@1+ (1,0) [0|1023] "A" Vector__XXX
 SG_ FC_evseMeterVoltage m0 : 54|10@1+ (1,0) [0|1023] "V" Vector__XXX
 SG_ FC_evseMeterFwGitHash m1 : 4|56@1+ (1,0) [0|7.20575940379e+16] "" Vector__XXX

BO_ 1334 FC_evseBilling2: 8 FC
 SG_ FC_evseBilling2DataSelect M : 0|4@1+ (1,0) [0|15] "" Vector__XXX
 SG_ FC_evsePpuEnabled m0 : 4|1@1+ (1,0) [0|1] "" Vector__XXX
 SG_ FC_evseBillingEnergyHighRes m0 : 8|24@1+ (0.0001,0) [0|1677.7214] "kWh" Vector__XXX

BO_ 1303 FC_identifier: 8 FC
 SG_ FC_id : 0|32@1+ (1,0) [0|4294967295] "" Vector__XXX
 SG_ FC_sessionId : 32|32@1+ (1,0) [0|4294967295] "" Vector__XXX

BO_ 1310 FC_info: 8 FC
 SG_ FC_infoIndex M : 0|8@1+ (1,0) [0|255] "" Vector__XXX
 SG_ FC_infoBuildType m10 : 8|8@1+ (1,0) [0|255] "" Vector__XXX
 SG_ FC_infoBuildConfigID m10 : 16|16@1+ (1,0) [0|65535] "" Vector__XXX
 SG_ FC_infoHardwareID m10 : 32|16@1+ (1,0) [0|65535] "" Vector__XXX
 SG_ FC_infoComponentID m10 : 48|16@1+ (1,0) [0|65535] "" Vector__XXX
 SG_ FC_infoPcbaID m11 : 16|8@1+ (1,0) [0|255] "" Vector__XXX
 SG_ FC_infoAssemblyID m11 : 24|8@1+ (1,0) [0|255] "" Vector__XXX
 SG_ FC_infoUsageID m11 : 32|16@1+ (1,0) [0|65535] "" Vector__XXX
 SG_ FC_infoSubUsageID m11 : 48|16@1+ (1,0) [0|65535] "" Vector__XXX
 SG_ FC_infoApplicationCRC m13 : 32|32@1+ (1,0) [0|4294967295] "" Vector__XXX
 SG_ FC_infoAppGitHashBytes m17 : 8|56@1+ (1,0) [0|7.20575940379e+16] "" Vector__XXX
 SG_ FC_infoBootGitHashBytes m18 : 8|56@1+ (1,0) [0|7.20575940379e+16] "" Vector__XXX
 SG_ FC_infoPlatformType m19 : 8|8@1+ (1,0) [0|255] "" Vector__XXX
 SG_ FC_infoMajorVersion m19 : 16|8@1+ (1,0) [0|255] "" Vector__XXX
 SG_ FC_infoBranchOrigin m19 : 24|8@1+ (1,0) [0|255] "" Vector__XXX
 SG_ FC_infoMaturity m19 : 32|8@1+ (1,0) [0|255] "" Vector__XXX
 SG_ FC_infoHardwareRevision m19 : 40|8@1+ (1,0) [0|255] "" Vector__XXX
 SG_ FC_partNumChar01 m25 : 8|8@1+ (1,0) [0|255] "" Vector__XXX
 SG_ FC_partNumChar02 m25 : 16|8@1+ (1,0) [0|255] "" Vector__XXX
 SG_ FC_partNumChar03 m25 : 24|8@1+ (1,0) [0|255] "" Vector__XXX
 SG_ FC_partNumChar04 m25 : 32|8@1+ (1,0) [0|255] "" Vector__XXX
 SG_ FC_partNumChar05 m25 : 40|8@1+ (1,0) [0|255] "" Vector__XXX
 SG_ FC_partNumChar06 m25 : 48|8@1+ (1,0) [0|255] "" Vector__XXX
 SG_ FC_partNumChar07 m25 : 56|8@1+ (1,0) [0|255] "" Vector__XXX
 SG_ FC_partNumChar08 m26 : 8|8@1+ (1,0) [0|255] "" Vector__XXX
 SG_ FC_partNumChar09 m26 : 16|8@1+ (1,0) [0|255] "" Vector__XXX
 SG_ FC_partNumChar10 m26 : 24|8@1+ (1,0) [0|255] "" Vector__XXX
 SG_ FC_partNumChar11 m26 : 32|8@1+ (1,0) [0|255] "" Vector__XXX
 SG_ FC_partNumChar12 m26 : 40|8@1+ (1,0) [0|255] "" Vector__XXX
 SG_ FC_partNumChar13 m26 : 48|8@1+ (1,0) [0|255] "" Vector__XXX
 SG_ FC_partNumChar14 m26 : 56|8@1+ (1,0) [0|255] "" Vector__XXX
 SG_ FC_partNumChar15 m27 : 8|8@1+ (1,0) [0|255] "" Vector__XXX
 SG_ FC_partNumChar16 m27 : 16|8@1+ (1,0) [0|255] "" Vector__XXX
 SG_ FC_partNumChar17 m27 : 24|8@1+ (1,0) [0|255] "" Vector__XXX
 SG_ FC_partNumChar18 m27 : 32|8@1+ (1,0) [0|255] "" Vector__XXX
 SG_ FC_partNumChar19 m27 : 40|8@1+ (1,0) [0|255] "" Vector__XXX
 SG_ FC_partNumChar20 m27 : 48|8@1+ (1,0) [0|255] "" Vector__XXX

BO_ 580 FC_limits: 8 FC
 SG_ FC_powerLimit : 0|13@1+ (0.06225586,0) [0|509.93774414] "kW" Vector__XXX
 SG_ FC_currentLimit : 16|13@1+ (0.07324219,0) [0|599.92675781] "A" Vector__XXX
 SG_ FC_maxVoltageLimit : 32|13@1+ (0.07324219,0) [0|599.92675822] "V" Vector__XXX
 SG_ FC_minVoltageLimit : 48|13@1+ (0.07324219,0) [0|599.92675781] "V" Vector__XXX

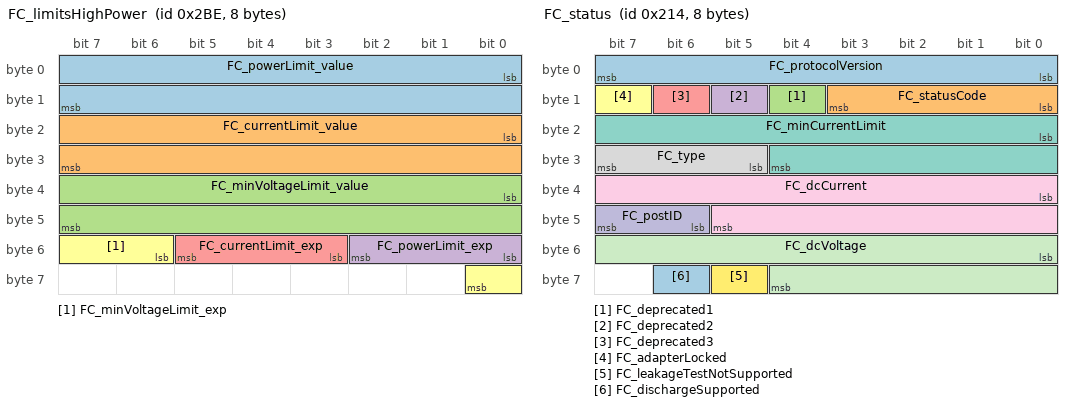
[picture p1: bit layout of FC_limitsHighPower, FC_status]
BO_ 702 FC_limitsHighPower: 8 FC
 SG_ FC_powerLimit_value : 0|16@1- (1,0) [-32767|32767] "*10^exp kW" Vector__XXX
 SG_ FC_currentLimit_value : 16|16@1- (1,0) [-32767|32767] "*10^exp A" Vector__XXX
 SG_ FC_minVoltageLimit_value : 32|16@1- (1,0) [-32767|32767] "*10^exp V" Vector__XXX
 SG_ FC_powerLimit_exp : 48|3@1- (1,0) [-4|3] "" Vector__XXX
 SG_ FC_currentLimit_exp : 51|3@1- (1,0) [-4|3] "" Vector__XXX
 SG_ FC_minVoltageLimit_exp : 54|3@1- (1,0) [-4|3] "" Vector__XXX

BO_ 1345 FC_maxLimits: 8 FC
 SG_ FC_maxPowerLimit : 0|13@1+ (0.06225586,0) [0|509.93774414] "kW" Vector__XXX
 SG_ FC_maxCurrentLimit : 16|13@1+ (0.07324219,0) [0|599.92675781] "A" Vector__XXX

BO_ 1300 FC_serial: 8 FC
 SG_ FC_serialDataSelect M : 0|7@1+ (1,0) [0|127] "" Vector__XXX
 SG_ FC_serialChar01 m0 : 8|8@1+ (1,0) [0|255] "" Vector__XXX
 SG_ FC_serialChar02 m0 : 16|8@1+ (1,0) [0|255] "" Vector__XXX
 SG_ FC_serialChar03 m0 : 24|8@1+ (1,0) [0|255] "" Vector__XXX
 SG_ FC_serialChar04 m0 : 32|8@1+ (1,0) [0|255] "" Vector__XXX
 SG_ FC_serialChar05 m0 : 40|8@1+ (1,0) [0|255] "" Vector__XXX
 SG_ FC_serialChar06 m0 : 48|8@1+ (1,0) [0|255] "" Vector__XXX
 SG_ FC_serialChar07 m0 : 56|8@1+ (1,0) [0|255] "" Vector__XXX
 SG_ FC_serialChar08 m1 : 8|8@1+ (1,0) [0|255] "" Vector__XXX
 SG_ FC_serialChar09 m1 : 16|8@1+ (1,0) [0|255] "" Vector__XXX
 SG_ FC_serialChar10 m1 : 24|8@1+ (1,0) [0|255] "" Vector__XXX
 SG_ FC_serialChar11 m1 : 32|8@1+ (1,0) [0|255] "" Vector__XXX
 SG_ FC_serialChar12 m1 : 40|8@1+ (1,0) [0|255] "" Vector__XXX
 SG_ FC_serialChar13 m1 : 48|8@1+ (1,0) [0|255] "" Vector__XXX
 SG_ FC_serialChar14 m1 : 56|8@1+ (1,0) [0|255] "" Vector__XXX
 SG_ FC_serialChar15 m2 : 8|8@1+ (1,0) [0|255] "" Vector__XXX
 SG_ FC_serialChar16 m2 : 16|8@1+ (1,0) [0|255] "" Vector__XXX
 SG_ FC_serialChar17 m2 : 24|8@1+ (1,0) [0|255] "" Vector__XXX

BO_ 532 FC_status: 8 FC
 SG_ FC_protocolVersion : 0|8@1+ (1,0) [0|255] "" Vector__XXX
 SG_ FC_statusCode : 8|4@1+ (1,0) [0|15] "" Vector__XXX
 SG_ FC_deprecated1 : 12|1@1+ (1,0) [0|1] "" Vector__XXX
 SG_ FC_deprecated2 : 13|1@1+ (1,0) [0|1] "" Vector__XXX
 SG_ FC_deprecated3 : 14|1@1+ (1,0) [0|1] "" Vector__XXX
 SG_ FC_adapterLocked : 15|1@1+ (1,0) [0|1] "" Vector__XXX
 SG_ FC_minCurrentLimit : 16|13@1+ (0.1,0) [0|600] "A" Vector__XXX
 SG_ FC_type : 29|3@1+ (1,0) [0|7] "" Vector__XXX
 SG_ FC_dcCurrent : 32|14@1- (0.07324219,0) [-600|599.92675781] "A" Vector__XXX
 SG_ FC_postID : 46|2@1+ (1,0) [0|3] "" Vector__XXX
 SG_ FC_dcVoltage : 48|13@1+ (0.07324219,0) [0|599.92675822] "V" Vector__XXX
 SG_ FC_leakageTestNotSupported : 61|1@1+ (1,0) [0|1] "" Vector__XXX
 SG_ FC_dischargeSupported : 62|1@1+ (1,0) [0|1] "" Vector__XXX

BO_ 533 FC_status2: 8 FC
 SG_ FC_externalIsolationResistance : 0|8@1+ (40,0) [0|10200] "kOhm" Vector__XXX

BO_ 535 FC_status3: 8 FC
 SG_ FC_status3DataSelect M : 0|7@1+ (1,0) [0|127] "" Vector__XXX
 SG_ FC_status3DummySig : 7|1@1+ (1,0) [0|1] "" Vector__XXX
 SG_ FC_class m0 : 8|8@1+ (1,0) [0|255] "" Vector__XXX
 SG_ FC_brand m0 : 16|4@1+ (1,0) [0|1] "" Vector__XXX
 SG_ FC_coolingType m0 : 20|4@1+ (1,0) [0|15] "" Vector__XXX
 SG_ FC_uiStopType m0 : 24|4@1+ (1,0) [0|15] "" Vector__XXX
 SG_ FC_emergencyShutdownSupported m0 : 28|1@1+ (1,0) [0|1] "" Vector__XXX
 SG_ FC_generation m0 : 32|8@1+ (1,0) [0|255] "" Vector__XXX

BO_ 888 GTW_ECall: 8 GTW
 SG_ GTW_GTW_SOS_ECALL_RQST : 0|1@1+ (1,0) [0|1] "" Vector__XXX
 SG_ GTW_LTE_ECALL_LOCK : 1|1@1+ (1,0) [0|1] "" Vector__XXX

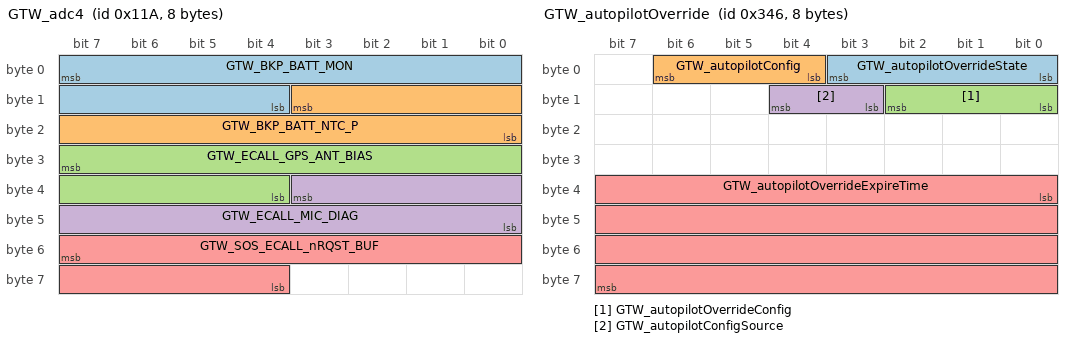
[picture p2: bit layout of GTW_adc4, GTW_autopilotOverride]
BO_ 282 GTW_adc4: 8 GTW
 SG_ GTW_BKP_BATT_MON : 7|12@0+ (1,0) [0|4094] "mV" Vector__XXX
 SG_ GTW_BKP_BATT_NTC_P : 11|12@0+ (1,0) [0|4094] "mV" Vector__XXX
 SG_ GTW_ECALL_GPS_ANT_BIAS : 31|12@0+ (1,0) [0|4094] "mV" Vector__XXX
 SG_ GTW_ECALL_MIC_DIAG : 35|12@0+ (1,0) [0|4094] "mV" Vector__XXX
 SG_ GTW_SOS_ECALL_nRQST_BUF : 55|12@0+ (1,0) [0|4094] "mV" Vector__XXX

BO_ 1384 GTW_alertLog: 8 GTW
 SG_ GTW_alertID M : 0|9@1+ (1,0) [0|511] "" Vector__XXX
 SG_ GTW_alertState : 15|1@1+ (1,0) [0|1] "" Vector__XXX
 SG_ GTW_a014_crcVersion m14 : 16|32@1+ (1,0) [0|4294967295] "" Vector__XXX
 SG_ GTW_a015_crcVersion m15 : 16|32@1+ (1,0) [0|4294967295] "" Vector__XXX
 SG_ GTW_a016_crcVersion m16 : 16|32@1+ (1,0) [0|4294967295] "" Vector__XXX
 SG_ GTW_a017_crcVersion m17 : 16|32@1+ (1,0) [0|4294967295] "" Vector__XXX
 SG_ GTW_a018_crcVersion m18 : 16|32@1+ (1,0) [0|4294967295] "" Vector__XXX
 SG_ GTW_a019_crcVersion m19 : 16|32@1+ (1,0) [0|4294967295] "" Vector__XXX
 SG_ GTW_a020_crcVersion m20 : 16|32@1+ (1,0) [0|4294967295] "" Vector__XXX
 SG_ GTW_a021_crcVersion m21 : 16|32@1+ (1,0) [0|4294967295] "" Vector__XXX
 SG_ GTW_a022_crcVersion m22 : 16|32@1+ (1,0) [0|4294967295] "" Vector__XXX
 SG_ GTW_a023_crcVersion m23 : 16|32@1+ (1,0) [0|4294967295] "" Vector__XXX
 SG_ GTW_a024_crcVersion m24 : 16|32@1+ (1,0) [0|4294967295] "" Vector__XXX
 SG_ GTW_a025_crcVersion m25 : 16|32@1+ (1,0) [0|4294967295] "" Vector__XXX
 SG_ GTW_a026_crcVersion m26 : 16|32@1+ (1,0) [0|4294967295] "" Vector__XXX
 SG_ GTW_a027_crcVersion m27 : 16|32@1+ (1,0) [0|4294967295] "" Vector__XXX
 SG_ GTW_a028_crcVersion m28 : 16|32@1+ (1,0) [0|4294967295] "" Vector__XXX
 SG_ GTW_a029_crcVersion m29 : 16|32@1+ (1,0) [0|4294967295] "" Vector__XXX
 SG_ GTW_a030_crcVersion m30 : 16|32@1+ (1,0) [0|4294967295] "" Vector__XXX
 SG_ GTW_a031_crcVersion m31 : 16|32@1+ (1,0) [0|4294967295] "" Vector__XXX
 SG_ GTW_a032_crcVersion m32 : 16|32@1+ (1,0) [0|4294967295] "" Vector__XXX
 SG_ GTW_a033_crcVersion m33 : 16|32@1+ (1,0) [0|4294967295] "" Vector__XXX
 SG_ GTW_a034_crcVersion m34 : 16|32@1+ (1,0) [0|4294967295] "" Vector__XXX
 SG_ GTW_a035_crcVersion m35 : 16|32@1+ (1,0) [0|4294967295] "" Vector__XXX
 SG_ GTW_a036_crcVersion m36 : 16|32@1+ (1,0) [0|4294967295] "" Vector__XXX
 SG_ GTW_a037_crcVersion m37 : 16|32@1+ (1,0) [0|4294967295] "" Vector__XXX
 SG_ GTW_a038_crcVersion m38 : 16|32@1+ (1,0) [0|4294967295] "" Vector__XXX
 SG_ GTW_a039_crcVersion m39 : 16|32@1+ (1,0) [0|4294967295] "" Vector__XXX
 SG_ GTW_a040_crcVersion m40 : 16|32@1+ (1,0) [0|4294967295] "" Vector__XXX
 SG_ GTW_a041_crcVersion m41 : 16|32@1+ (1,0) [0|4294967295] "" Vector__XXX
 SG_ GTW_a042_crcVersion m42 : 16|32@1+ (1,0) [0|4294967295] "" Vector__XXX
 SG_ GTW_a043_crcVersion m43 : 16|32@1+ (1,0) [0|4294967295] "" Vector__XXX
 SG_ GTW_a045_crcVersion m45 : 16|32@1+ (1,0) [0|4294967295] "" Vector__XXX
 SG_ GTW_a046_crcVersion m46 : 16|32@1+ (1,0) [0|4294967295] "" Vector__XXX
 SG_ GTW_a047_crcVersion m47 : 16|32@1+ (1,0) [0|4294967295] "" Vector__XXX
 SG_ GTW_a048_crcVersion m48 : 16|32@1+ (1,0) [0|4294967295] "" Vector__XXX
 SG_ GTW_a049_headerError m49 : 16|2@1+ (1,0) [0|3] "" Vector__XXX
 SG_ GTW_a054_crcVersion m54 : 16|32@1+ (1,0) [0|4294967295] "" Vector__XXX
 SG_ GTW_a055_crcVersion m55 : 16|32@1+ (1,0) [0|4294967295] "" Vector__XXX
 SG_ GTW_a062_bmpWatchdogReason m62 : 16|3@1+ (1,0) [0|7] "" Vector__XXX
 SG_ GTW_a063_VEH_faultConfinement m63 : 16|2@1+ (1,0) [0|3] "" Vector__XXX
 SG_ GTW_a064_CH_faultConfinement m64 : 16|2@1+ (1,0) [0|3] "" Vector__XXX
 SG_ GTW_a065_PARTY_faultConfinement m65 : 16|2@1+ (1,0) [0|3] "" Vector__XXX
 SG_ GTW_a066_type m66 : 16|5@1+ (1,0) [0|31] "" Vector__XXX
 SG_ GTW_a066_exceptionCfgId m66 : 21|8@1+ (1,0) [0|255] "" Vector__XXX
 SG_ GTW_a066_uptime m66 : 29|32@1+ (1,0) [0|4294967295] "" Vector__XXX
 SG_ GTW_a066_core m66 : 61|3@1+ (1,0) [0|7] "" Vector__XXX
 SG_ GTW_a068_codeKeyMissing m68 : 16|1@1+ (1,0) [0|1] "" Vector__XXX
 SG_ GTW_a068_cmdKeyMissing m68 : 17|1@1+ (1,0) [0|1] "" Vector__XXX
 SG_ GTW_a069_sdIntStatusErrs m69 : 16|1@1+ (1,0) [0|1] "" Vector__XXX
 SG_ GTW_a069_sdTimeout m69 : 17|1@1+ (1,0) [0|1] "" Vector__XXX
 SG_ GTW_a069_sdCmdErr m69 : 18|1@1+ (1,0) [0|1] "" Vector__XXX
 SG_ GTW_a069_sdWriteErr m69 : 19|1@1+ (1,0) [0|1] "" Vector__XXX
 SG_ GTW_a069_sdReadErr m69 : 20|1@1+ (1,0) [0|1] "" Vector__XXX
 SG_ GTW_a069_autoCmd12Err m69 : 21|1@1+ (1,0) [0|1] "" Vector__XXX
 SG_ GTW_a072_updtFailureMask m72 : 16|32@1+ (1,0) [0|4294967295] "" Vector__XXX
 SG_ GTW_a073_SOCResetRequestor m73 : 16|3@1+ (1,0) [0|7] "" Vector__XXX
 SG_ GTW_a077_bmpPmicErrorType m77 : 16|3@1+ (1,0) [0|7] "" Vector__XXX
 SG_ GTW_a097_crcVersion m97 : 16|32@1+ (1,0) [0|4294967295] "" Vector__XXX
 SG_ GTW_a098_crcVersion m98 : 16|32@1+ (1,0) [0|4294967295] "" Vector__XXX
 SG_ GTW_a099_crcVersion m99 : 16|32@1+ (1,0) [0|4294967295] "" Vector__XXX
 SG_ GTW_a100_crcVersion m100 : 16|32@1+ (1,0) [0|4294967295] "" Vector__XXX
 SG_ GTW_a101_switchStuck m101 : 16|1@1+ (1,0) [0|1] "" Vector__XXX
 SG_ GTW_a101_ETH_SW_nINT m101 : 17|1@1+ (1,0) [0|1] "" Vector__XXX
 SG_ GTW_a106_crcVersion m106 : 16|32@1+ (1,0) [0|4294967295] "" Vector__XXX
 SG_ GTW_a107_crcVersion m107 : 16|32@1+ (1,0) [0|4294967295] "" Vector__XXX
 SG_ GTW_a108_crcVersion m108 : 16|32@1+ (1,0) [0|4294967295] "" Vector__XXX
 SG_ GTW_a117_MC_RGM_DES m117 : 16|32@1+ (1,0) [0|4294967295] "" Vector__XXX
 SG_ GTW_a118_MC_RGM_FES m118 : 16|32@1+ (1,0) [0|4294967295] "" Vector__XXX
 SG_ GTW_a122_BDY_faultConfinement m122 : 16|2@1+ (1,0) [0|3] "" Vector__XXX
 SG_ GTW_a129_crcVersion m129 : 16|32@1+ (1,0) [0|4294967295] "" Vector__XXX
 SG_ GTW_a138_sdLifetimeUsed m138 : 16|8@1+ (1,0) [0|255] "" Vector__XXX
 SG_ GTW_a139_crcVersion m139 : 16|32@1+ (1,0) [0|4294967295] "" Vector__XXX
 SG_ GTW_a150_crcVersion m150 : 16|32@1+ (1,0) [0|4294967295] "" Vector__XXX
 SG_ GTW_a151_crcVersion m151 : 16|32@1+ (1,0) [0|4294967295] "" Vector__XXX
 SG_ GTW_a155_crcVersion m155 : 16|32@1+ (1,0) [0|4294967295] "" Vector__XXX
 SG_ GTW_a164_crcVersion m164 : 16|32@1+ (1,0) [0|4294967295] "" Vector__XXX
 SG_ GTW_a165_crcVersion m165 : 16|32@1+ (1,0) [0|4294967295] "" Vector__XXX
 SG_ GTW_a169_TPMS_pressureFL m169 : 16|8@1+ (1,0) [0|255] "" Vector__XXX
 SG_ GTW_a170_TPMS_pressureFR m170 : 16|8@1+ (1,0) [0|255] "" Vector__XXX
 SG_ GTW_a171_TPMS_pressureRL m171 : 16|8@1+ (1,0) [0|255] "" Vector__XXX
 SG_ GTW_a172_TPMS_pressureRR m172 : 16|8@1+ (1,0) [0|255] "" Vector__XXX
 SG_ GTW_a173_TPMS_pressureFL m173 : 16|8@1+ (1,0) [0|255] "" Vector__XXX
 SG_ GTW_a174_TPMS_pressureFR m174 : 16|8@1+ (1,0) [0|255] "" Vector__XXX
 SG_ GTW_a175_TPMS_pressureRL m175 : 16|8@1+ (1,0) [0|255] "" Vector__XXX
 SG_ GTW_a176_TPMS_pressureRR m176 : 16|8@1+ (1,0) [0|255] "" Vector__XXX
 SG_ GTW_a219_crcVersion m219 : 16|32@1+ (1,0) [0|4294967295] "" Vector__XXX
 SG_ GTW_a223_crcVersion m223 : 16|32@1+ (1,0) [0|4294967295] "" Vector__XXX
 SG_ GTW_a226_crcVersion m226 : 16|32@1+ (1,0) [0|4294967295] "" Vector__XXX
 SG_ GTW_a227_crcVersion m227 : 16|32@1+ (1,0) [0|4294967295] "" Vector__XXX
 SG_ GTW_a228_crcVersion m228 : 16|32@1+ (1,0) [0|4294967295] "" Vector__XXX
 SG_ GTW_a244_crcVersion m244 : 16|32@1+ (1,0) [0|4294967295] "" Vector__XXX
 SG_ GTW_a245_page0ControlValue m245 : 16|16@1+ (1,0) [0|65535] "" Vector__XXX
 SG_ GTW_a245_page1ControlValue m245 : 32|16@1+ (1,0) [0|65535] "" Vector__XXX
 SG_ GTW_a261_failureReason m261 : 16|3@1+ (1,0) [0|7] "" Vector__XXX
 SG_ GTW_a261_failureData1 m261 : 24|16@1+ (1,0) [0|65535] "" Vector__XXX
 SG_ GTW_a261_failureData2 m261 : 40|16@1+ (1,0) [0|65535] "" Vector__XXX
 SG_ GTW_a273_crcVersion m273 : 16|32@1+ (1,0) [0|4294967295] "" Vector__XXX
 SG_ GTW_a274_crcVersion m274 : 16|32@1+ (1,0) [0|4294967295] "" Vector__XXX
 SG_ GTW_a277_mitigationFailureReason m277 : 16|3@1+ (1,0) [0|7] "" Vector__XXX
 SG_ GTW_a279_repeatCount m279 : 16|8@1+ (1,0) [0|255] "" Vector__XXX
 SG_ GTW_a279_failureReason m279 : 24|3@1+ (1,0) [0|7] "" Vector__XXX
 SG_ GTW_a279_failureData1 m279 : 32|16@1+ (1,0) [0|65535] "" Vector__XXX
 SG_ GTW_a279_failureData2 m279 : 48|16@1+ (1,0) [0|65535] "" Vector__XXX
 SG_ GTW_a309_crcVersion m309 : 16|32@1+ (1,0) [0|4294967295] "" Vector__XXX
 SG_ GTW_a317_status m317 : 16|3@1+ (1,0) [0|7] "" Vector__XXX
 SG_ GTW_a317_errorCode m317 : 19|5@1+ (1,0) [0|31] "" Vector__XXX
 SG_ GTW_a329_crcVersion m329 : 16|32@1+ (1,0) [0|4294967295] "" Vector__XXX
 SG_ GTW_a330_crcVersion m330 : 16|32@1+ (1,0) [0|4294967295] "" Vector__XXX
 SG_ GTW_a331_crcVersion m331 : 16|32@1+ (1,0) [0|4294967295] "" Vector__XXX
 SG_ GTW_a342_crcVersion m342 : 16|32@1+ (1,0) [0|4294967295] "" Vector__XXX
 SG_ GTW_a348_crcVersion m348 : 16|32@1+ (1,0) [0|4294967295] "" Vector__XXX
 SG_ GTW_a349_crcVersion m349 : 16|32@1+ (1,0) [0|4294967295] "" Vector__XXX
 SG_ GTW_a354_crcVersion m354 : 16|32@1+ (1,0) [0|4294967295] "" Vector__XXX
 SG_ GTW_a355_crcVersion m355 : 16|32@1+ (1,0) [0|4294967295] "" Vector__XXX
 SG_ GTW_a358_crcVersion m358 : 16|32@1+ (1,0) [0|4294967295] "" Vector__XXX
 SG_ GTW_a359_crcVersion m359 : 16|32@1+ (1,0) [0|4294967295] "" Vector__XXX
 SG_ GTW_a360_crcVersion m360 : 16|32@1+ (1,0) [0|4294967295] "" Vector__XXX
 SG_ GTW_a361_crcVersion m361 : 16|32@1+ (1,0) [0|4294967295] "" Vector__XXX
 SG_ GTW_a362_crcVersion m362 : 16|32@1+ (1,0) [0|4294967295] "" Vector__XXX
 SG_ GTW_a363_crcVersion m363 : 16|32@1+ (1,0) [0|4294967295] "" Vector__XXX
 SG_ GTW_a364_crcVersion m364 : 16|32@1+ (1,0) [0|4294967295] "" Vector__XXX
 SG_ GTW_a380_crcVersion m380 : 16|32@1+ (1,0) [0|4294967295] "" Vector__XXX
 SG_ GTW_a381_crcVersion m381 : 16|32@1+ (1,0) [0|4294967295] "" Vector__XXX
 SG_ GTW_a382_crcVersion m382 : 16|32@1+ (1,0) [0|4294967295] "" Vector__XXX
 SG_ GTW_a383_crcVersion m383 : 16|32@1+ (1,0) [0|4294967295] "" Vector__XXX
 SG_ GTW_a384_crcVersion m384 : 16|32@1+ (1,0) [0|4294967295] "" Vector__XXX
 SG_ GTW_a385_crcVersion m385 : 16|32@1+ (1,0) [0|4294967295] "" Vector__XXX
 SG_ GTW_a386_crcVersion m386 : 16|32@1+ (1,0) [0|4294967295] "" Vector__XXX
 SG_ GTW_a394_crcVersion m394 : 16|32@1+ (1,0) [0|4294967295] "" Vector__XXX
 SG_ GTW_a401_crcVersion m401 : 16|32@1+ (1,0) [0|4294967295] "" Vector__XXX
 SG_ GTW_a402_crcVersion m402 : 16|32@1+ (1,0) [0|4294967295] "" Vector__XXX
 SG_ GTW_a409_RES_CAUSE m409 : 16|32@1+ (1,0) [0|4294967295] "" Vector__XXX
 SG_ GTW_a410_RES_CAUSE2 m410 : 16|32@1+ (1,0) [0|4294967295] "" Vector__XXX
 SG_ GTW_a418_crcVersion m418 : 16|32@1+ (1,0) [0|4294967295] "" Vector__XXX
 SG_ GTW_a427_crcVersion m427 : 16|32@1+ (1,0) [0|4294967295] "" Vector__XXX
 SG_ GTW_a428_crcVersion m428 : 16|32@1+ (1,0) [0|4294967295] "" Vector__XXX
 SG_ GTW_a429_crcVersion m429 : 16|32@1+ (1,0) [0|4294967295] "" Vector__XXX
 SG_ GTW_a439_crcVersion m439 : 16|32@1+ (1,0) [0|4294967295] "" Vector__XXX

BO_ 62 GTW_alertMatrix: 8 GTW
 SG_ GTW_matrixIndex M : 0|4@1+ (1,0) [0|15] "" Vector__XXX
 SG_ GTW_w001_canEthTxQueue m0 : 4|1@1+ (1,0) [0|1] "" Vector__XXX
 SG_ GTW_w002_taskError m0 : 5|1@1+ (1,0) [0|1] "" Vector__XXX
 SG_ GTW_w003_logWriteRecord m0 : 6|1@1+ (1,0) [0|1] "" Vector__XXX
 SG_ GTW_w004_mallocHook m0 : 7|1@1+ (1,0) [0|1] "" Vector__XXX
 SG_ GTW_w005_stackOverflowHook m0 : 8|1@1+ (1,0) [0|1] "" Vector__XXX
 SG_ GTW_w006_ifTxOutputFull m0 : 9|1@1+ (1,0) [0|1] "" Vector__XXX
 SG_ GTW_w007_ifRxBufError m0 : 10|1@1+ (1,0) [0|1] "" Vector__XXX
 SG_ GTW_w008_ifPbufAllocError m0 : 11|1@1+ (1,0) [0|1] "" Vector__XXX
 SG_ GTW_w009_lateTask m0 : 12|1@1+ (1,0) [0|1] "" Vector__XXX
 SG_ GTW_w010_wdTaskCount m0 : 13|1@1+ (1,0) [0|1] "" Vector__XXX
 SG_ GTW_w011_cancoreWatchdog m0 : 14|1@1+ (1,0) [0|1] "" Vector__XXX
 SG_ GTW_w012_maincoreWatchdog m0 : 15|1@1+ (1,0) [0|1] "" Vector__XXX
 SG_ GTW_w014_APSversionMismatch m0 : 17|1@1+ (1,0) [0|1] "" Vector__XXX
 SG_ GTW_w015_DIFversionMismatch m0 : 18|1@1+ (1,0) [0|1] "" Vector__XXX
 SG_ GTW_w016_BLEEPCENTERversionMisma m0 : 19|1@1+ (1,0) [0|1] "" Vector__XXX
 SG_ GTW_w017_BMSversionMismatch m0 : 20|1@1+ (1,0) [0|1] "" Vector__XXX
 SG_ GTW_w018_CMPversionMismatch m0 : 21|1@1+ (1,0) [0|1] "" Vector__XXX
 SG_ GTW_w019_CPversionMismatch m0 : 22|1@1+ (1,0) [0|1] "" Vector__XXX
 SG_ GTW_w020_DIRversionMismatch m0 : 23|1@1+ (1,0) [0|1] "" Vector__XXX
 SG_ GTW_w021_EPAS3PversionMismatch m0 : 24|1@1+ (1,0) [0|1] "" Vector__XXX
 SG_ GTW_w022_EPBLversionMismatch m0 : 25|1@1+ (1,0) [0|1] "" Vector__XXX
 SG_ GTW_w023_EPBRversionMismatch m0 : 26|1@1+ (1,0) [0|1] "" Vector__XXX
 SG_ GTW_w024_ESPversionMismatch m0 : 27|1@1+ (1,0) [0|1] "" Vector__XXX
 SG_ GTW_w025_ESPCALversionMismatch m0 : 28|1@1+ (1,0) [0|1] "" Vector__XXX
 SG_ GTW_w026_GTWversionMismatch m0 : 29|1@1+ (1,0) [0|1] "" Vector__XXX
 SG_ GTW_w027_HVPversionMismatch m0 : 30|1@1+ (1,0) [0|1] "" Vector__XXX
 SG_ GTW_w028_IBSTversionMismatch m0 : 31|1@1+ (1,0) [0|1] "" Vector__XXX
 SG_ GTW_w029_IBSTCALversionMismatch m0 : 32|1@1+ (1,0) [0|1] "" Vector__XXX
 SG_ GTW_w030_OCS1PversionMismatch m0 : 33|1@1+ (1,0) [0|1] "" Vector__XXX
 SG_ GTW_w031_PARKversionMismatch m0 : 34|1@1+ (1,0) [0|1] "" Vector__XXX
 SG_ GTW_w032_PCSversionMismatch m0 : 35|1@1+ (1,0) [0|1] "" Vector__XXX
 SG_ GTW_w033_PCSCPU2versionMismatch m0 : 36|1@1+ (1,0) [0|1] "" Vector__XXX
 SG_ GTW_w034_PMRversionMismatch m0 : 37|1@1+ (1,0) [0|1] "" Vector__XXX
 SG_ GTW_w035_PMFversionMismatch m0 : 38|1@1+ (1,0) [0|1] "" Vector__XXX
 SG_ GTW_w036_PTCversionMismatch m0 : 39|1@1+ (1,0) [0|1] "" Vector__XXX
 SG_ GTW_w037_RADCversionMismatch m0 : 40|1@1+ (1,0) [0|1] "" Vector__XXX
 SG_ GTW_w038_RCMversionMismatch m0 : 41|1@1+ (1,0) [0|1] "" Vector__XXX
 SG_ GTW_w039_RCMCALversionMismatch m0 : 42|1@1+ (1,0) [0|1] "" Vector__XXX
 SG_ GTW_w040_SCCMversionMismatch m0 : 43|1@1+ (1,0) [0|1] "" Vector__XXX
 SG_ GTW_w041_VCSECversionMismatch m0 : 44|1@1+ (1,0) [0|1] "" Vector__XXX
 SG_ GTW_w042_TASversionMismatch m0 : 45|1@1+ (1,0) [0|1] "" Vector__XXX
 SG_ GTW_w043_THSversionMismatch m0 : 46|1@1+ (1,0) [0|1] "" Vector__XXX
 SG_ GTW_w045_VCFRONTversionMismatch m0 : 48|1@1+ (1,0) [0|1] "" Vector__XXX
 SG_ GTW_w046_VCLEFTversionMismatch m0 : 49|1@1+ (1,0) [0|1] "" Vector__XXX
 SG_ GTW_w047_VCRIGHTversionMismatch m0 : 50|1@1+ (1,0) [0|1] "" Vector__XXX
 SG_ GTW_w048_EPAS3SversionMismatch m0 : 51|1@1+ (1,0) [0|1] "" Vector__XXX
 SG_ GTW_w049_corruptedManifest m0 : 52|1@1+ (1,0) [0|1] "" Vector__XXX
 SG_ GTW_w050_sdCardInitFailure m0 : 53|1@1+ (1,0) [0|1] "" Vector__XXX
 SG_ GTW_w051_sdCardFileSystemFailure m0 : 54|1@1+ (1,0) [0|1] "" Vector__XXX
 SG_ GTW_w052_ifTxSpans m0 : 55|1@1+ (1,0) [0|1] "" Vector__XXX
 SG_ GTW_w053_busSleepFailure m0 : 56|1@1+ (1,0) [0|1] "" Vector__XXX
 SG_ GTW_w054_OPCRversionMismatch m0 : 57|1@1+ (1,0) [0|1] "" Vector__XXX
 SG_ GTW_w055_OPCFversionMismatch m0 : 58|1@1+ (1,0) [0|1] "" Vector__XXX
 SG_ GTW_w057_i2cFailure m0 : 60|1@1+ (1,0) [0|1] "" Vector__XXX
 SG_ GTW_w058_rtcAlarmFailure m0 : 61|1@1+ (1,0) [0|1] "" Vector__XXX
 SG_ GTW_w059_inFactoryMode m0 : 62|1@1+ (1,0) [0|1] "" Vector__XXX
 SG_ GTW_w060_unFused m0 : 63|1@1+ (1,0) [0|1] "" Vector__XXX
 SG_ GTW_w061_bmpSleepFailure m1 : 4|1@1+ (1,0) [0|1] "" Vector__XXX
 SG_ GTW_w062_bmpWatchdog m1 : 5|1@1+ (1,0) [0|1] "" Vector__XXX
 SG_ GTW_w063_VEH_canFault m1 : 6|1@1+ (1,0) [0|1] "" Vector__XXX
 SG_ GTW_w064_CH_canFault m1 : 7|1@1+ (1,0) [0|1] "" Vector__XXX
 SG_ GTW_w065_PARTY_canFault m1 : 8|1@1+ (1,0) [0|1] "" Vector__XXX
 SG_ GTW_w066_exception m1 : 9|1@1+ (1,0) [0|1] "" Vector__XXX
 SG_ GTW_w067_tcpDebug m1 : 10|1@1+ (1,0) [0|1] "" Vector__XXX
 SG_ GTW_w068_prodKeyMissing m1 : 11|1@1+ (1,0) [0|1] "" Vector__XXX
 SG_ GTW_w069_diskioErr m1 : 12|1@1+ (1,0) [0|1] "" Vector__XXX
 SG_ GTW_w070_hrlDump m1 : 13|1@1+ (1,0) [0|1] "" Vector__XXX
 SG_ GTW_w071_hrlTrigger m1 : 14|1@1+ (1,0) [0|1] "" Vector__XXX
 SG_ GTW_w072_updateFailure m1 : 15|1@1+ (1,0) [0|1] "" Vector__XXX
 SG_ GTW_w073_steeringWheelReset m1 : 16|1@1+ (1,0) [0|1] "" Vector__XXX
 SG_ GTW_w074_epas3pMIA m1 : 17|1@1+ (1,0) [0|1] "" Vector__XXX
 SG_ GTW_w075_epas3sMIA m1 : 18|1@1+ (1,0) [0|1] "" Vector__XXX
 SG_ GTW_w076_ethInterfaceReset m1 : 19|1@1+ (1,0) [0|1] "" Vector__XXX
 SG_ GTW_w077_bmpPmicError m1 : 20|1@1+ (1,0) [0|1] "" Vector__XXX
 SG_ GTW_w078_VEHbusOverloaded m1 : 21|1@1+ (1,0) [0|1] "" Vector__XXX
 SG_ GTW_w079_PARTYbusOverloaded m1 : 22|1@1+ (1,0) [0|1] "" Vector__XXX
 SG_ GTW_w080_CHbusOverloaded m1 : 23|1@1+ (1,0) [0|1] "" Vector__XXX
 SG_ GTW_w081_udsMessageRejected m1 : 24|1@1+ (1,0) [0|1] "" Vector__XXX
 SG_ GTW_w082_sdCardBSCorrupted m1 : 25|1@1+ (1,0) [0|1] "" Vector__XXX
 SG_ GTW_w083_udsMsgDroppedByTcpStack m1 : 26|1@1+ (1,0) [0|1] "" Vector__XXX
 SG_ GTW_w084_canFrameDropped m1 : 27|1@1+ (1,0) [0|1] "" Vector__XXX
 SG_ GTW_w085_fuseStateUnknown m1 : 28|1@1+ (1,0) [0|1] "" Vector__XXX
 SG_ GTW_w086_ocu m1 : 29|1@1+ (1,0) [0|1] "" Vector__XXX
 SG_ GTW_w087_ocuInProgress m1 : 30|1@1+ (1,0) [0|1] "" Vector__XXX
 SG_ GTW_w088_sdCardInvReqParallel m1 : 31|1@1+ (1,0) [0|1] "" Vector__XXX
 SG_ GTW_w089_sdCardWatchdog m1 : 32|1@1+ (1,0) [0|1] "" Vector__XXX
 SG_ GTW_w090_ocuFailed m1 : 33|1@1+ (1,0) [0|1] "" Vector__XXX
 SG_ GTW_w091_lowStack m1 : 34|1@1+ (1,0) [0|1] "" Vector__XXX
 SG_ GTW_w092_sdCardInvReqZero m1 : 35|1@1+ (1,0) [0|1] "" Vector__XXX
 SG_ GTW_w093_sdCardInvReqOverflowBas m1 : 36|1@1+ (1,0) [0|1] "" Vector__XXX
 SG_ GTW_w094_sdCardInvReqOverflowCou m1 : 37|1@1+ (1,0) [0|1] "" Vector__XXX
 SG_ GTW_w095_sdCardFull m1 : 38|1@1+ (1,0) [0|1] "" Vector__XXX
 SG_ GTW_w096_sdCardFatCorrupted m1 : 39|1@1+ (1,0) [0|1] "" Vector__XXX
 SG_ GTW_w097_HCMLversionMismatch m1 : 40|1@1+ (1,0) [0|1] "" Vector__XXX
 SG_ GTW_w098_HCMRversionMismatch m1 : 41|1@1+ (1,0) [0|1] "" Vector__XXX
 SG_ GTW_w099_SWCversionMismatch m1 : 42|1@1+ (1,0) [0|1] "" Vector__XXX
 SG_ GTW_w100_CBCversionMismatch m1 : 43|1@1+ (1,0) [0|1] "" Vector__XXX
 SG_ GTW_w101_switchWatchdog m1 : 44|1@1+ (1,0) [0|1] "" Vector__XXX
 SG_ GTW_w103_sdCardFormatted m1 : 46|1@1+ (1,0) [0|1] "" Vector__XXX
 SG_ GTW_w104_sdCardDriverArgCorrupte m1 : 47|1@1+ (1,0) [0|1] "" Vector__XXX
 SG_ GTW_w105_eBuckConfigured m1 : 48|1@1+ (1,0) [0|1] "" Vector__XXX
 SG_ GTW_w106_BLEEPLEFTversionMismatc m1 : 49|1@1+ (1,0) [0|1] "" Vector__XXX
 SG_ GTW_w107_BLEEPRIGHTversionMismat m1 : 50|1@1+ (1,0) [0|1] "" Vector__XXX
 SG_ GTW_w108_BLEEPREARversionMismatc m1 : 51|1@1+ (1,0) [0|1] "" Vector__XXX
 SG_ GTW_w109_failedToStartUpdater m1 : 52|1@1+ (1,0) [0|1] "" Vector__XXX
 SG_ GTW_w110_readMdioFailed m1 : 53|1@1+ (1,0) [0|1] "" Vector__XXX
 SG_ GTW_w111_writeMdioFailed m1 : 54|1@1+ (1,0) [0|1] "" Vector__XXX
 SG_ GTW_w112_z4bDisabled m1 : 55|1@1+ (1,0) [0|1] "" Vector__XXX
 SG_ GTW_w113_unrecognizedCanMessage m1 : 56|1@1+ (1,0) [0|1] "" Vector__XXX
 SG_ GTW_w114_updtRetried m1 : 57|1@1+ (1,0) [0|1] "" Vector__XXX
 SG_ GTW_w115_hrlEventFileAvail m1 : 58|1@1+ (1,0) [0|1] "" Vector__XXX
 SG_ GTW_w116_switchInitFailed m1 : 59|1@1+ (1,0) [0|1] "" Vector__XXX
 SG_ GTW_w117_unexpectedDestructiveRe m1 : 60|1@1+ (1,0) [0|1] "" Vector__XXX
 SG_ GTW_w118_unexpectedFunctionalRes m1 : 61|1@1+ (1,0) [0|1] "" Vector__XXX
 SG_ GTW_w120_switchUnlocked m1 : 63|1@1+ (1,0) [0|1] "" Vector__XXX
 SG_ GTW_w122_BDY_canFault m2 : 5|1@1+ (1,0) [0|1] "" Vector__XXX
 SG_ GTW_w123_BDYbusOverloaded m2 : 6|1@1+ (1,0) [0|1] "" Vector__XXX
 SG_ GTW_w125_switchReplayUnlocked m2 : 8|1@1+ (1,0) [0|1] "" Vector__XXX
 SG_ GTW_w127_noFilePointersAvailable m2 : 10|1@1+ (1,0) [0|1] "" Vector__XXX
 SG_ GTW_w129_ICRversionMismatch m2 : 12|1@1+ (1,0) [0|1] "" Vector__XXX
 SG_ GTW_w133_adspFaultDetected m2 : 16|1@1+ (1,0) [0|1] "" Vector__XXX
 SG_ GTW_w134_disableFeatureFailed m2 : 17|1@1+ (1,0) [0|1] "" Vector__XXX
 SG_ GTW_w135_canLogQueueFull m2 : 18|1@1+ (1,0) [0|1] "" Vector__XXX
 SG_ GTW_w136_hrlGameModeFileAvail m2 : 19|1@1+ (1,0) [0|1] "" Vector__XXX
 SG_ GTW_w137_lowHeap m2 : 20|1@1+ (1,0) [0|1] "" Vector__XXX
 SG_ GTW_w138_sdCardEndOfLife m2 : 21|1@1+ (1,0) [0|1] "" Vector__XXX
 SG_ GTW_w139_CMPDversionMismatch m2 : 22|1@1+ (1,0) [0|1] "" Vector__XXX
 SG_ GTW_w140_cancoreHeartbeat m2 : 23|1@1+ (1,0) [0|1] "" Vector__XXX
 SG_ GTW_w141_teleCANETHis m2 : 24|1@1+ (1,0) [0|1] "" Vector__XXX
 SG_ GTW_w143_possibleCanWakeIssue m2 : 26|1@1+ (1,0) [0|1] "" Vector__XXX
 SG_ GTW_w144_hrlStateMachine m2 : 27|1@1+ (1,0) [0|1] "" Vector__XXX
 SG_ GTW_w145_carConfigsNotWritten m2 : 28|1@1+ (1,0) [0|1] "" Vector__XXX
 SG_ GTW_w146_performancePackageMisma m2 : 29|1@1+ (1,0) [0|1] "" Vector__XXX
 SG_ GTW_w147_updateAbortFor12v m2 : 30|1@1+ (1,0) [0|1] "" Vector__XXX
 SG_ GTW_w149_rtcTimeSetInPast m2 : 32|1@1+ (1,0) [0|1] "" Vector__XXX
 SG_ GTW_w150_HCM3LversionMismatch m2 : 33|1@1+ (1,0) [0|1] "" Vector__XXX
 SG_ GTW_w151_HCM3RversionMismatch m2 : 34|1@1+ (1,0) [0|1] "" Vector__XXX
 SG_ GTW_w153_externalRtcAlarmFailure m2 : 36|1@1+ (1,0) [0|1] "" Vector__XXX
 SG_ GTW_w155_PMversionMismatch m2 : 38|1@1+ (1,0) [0|1] "" Vector__XXX
 SG_ GTW_w164_VCBATTversionMismatch m2 : 47|1@1+ (1,0) [0|1] "" Vector__XXX
 SG_ GTW_w165_USMversionMismatch m2 : 48|1@1+ (1,0) [0|1] "" Vector__XXX
 SG_ GTW_w166_nErrCanFaultVeh m2 : 49|1@1+ (1,0) [0|1] "" Vector__XXX
 SG_ GTW_w167_nErrCanFaultCh m2 : 50|1@1+ (1,0) [0|1] "" Vector__XXX
 SG_ GTW_w168_nErrCanFaultParty m2 : 51|1@1+ (1,0) [0|1] "" Vector__XXX
 SG_ GTW_w169_TPMSsoftWarnFrontLeft m2 : 52|1@1+ (1,0) [0|1] "" Vector__XXX
 SG_ GTW_w170_TPMSsoftWarnFrontRight m2 : 53|1@1+ (1,0) [0|1] "" Vector__XXX
 SG_ GTW_w171_TPMSsoftWarnRearLeft m2 : 54|1@1+ (1,0) [0|1] "" Vector__XXX
 SG_ GTW_w172_TPMSsoftWarnRearRight m2 : 55|1@1+ (1,0) [0|1] "" Vector__XXX
 SG_ GTW_w173_TPMShardWarnFrontLeft m2 : 56|1@1+ (1,0) [0|1] "" Vector__XXX
 SG_ GTW_w174_TPMShardWarnFrontRight m2 : 57|1@1+ (1,0) [0|1] "" Vector__XXX
 SG_ GTW_w175_TPMShardWarnRearLeft m2 : 58|1@1+ (1,0) [0|1] "" Vector__XXX
 SG_ GTW_w176_TPMShardWarnRearRight m2 : 59|1@1+ (1,0) [0|1] "" Vector__XXX
 SG_ GTW_w186_swrPrecaution m3 : 9|1@1+ (1,0) [0|1] "" Vector__XXX
 SG_ GTW_w218_switchOTPIncorrect m3 : 41|1@1+ (1,0) [0|1] "" Vector__XXX
 SG_ GTW_w219_CMPSversionMismatch m3 : 42|1@1+ (1,0) [0|1] "" Vector__XXX
 SG_ GTW_w223_LVBMSversionMismatch m3 : 46|1@1+ (1,0) [0|1] "" Vector__XXX
 SG_ GTW_w224_sdCardUpgradeNeeded m3 : 47|1@1+ (1,0) [0|1] "" Vector__XXX
 SG_ GTW_w225_resetOnSleepWake m3 : 48|1@1+ (1,0) [0|1] "" Vector__XXX
 SG_ GTW_w226_DISPversionMismatch m3 : 49|1@1+ (1,0) [0|1] "" Vector__XXX
 SG_ GTW_w227_DISPTOUCHversionMismatc m3 : 50|1@1+ (1,0) [0|1] "" Vector__XXX
 SG_ GTW_w228_DISPOSDversionMismatch m3 : 51|1@1+ (1,0) [0|1] "" Vector__XXX
 SG_ GTW_w229_displaySoftsetConnectio m3 : 52|1@1+ (1,0) [0|1] "" Vector__XXX
 SG_ GTW_w230_touchInterruptStorm m3 : 53|1@1+ (1,0) [0|1] "" Vector__XXX
 SG_ GTW_w244_SDCRversionMismatch m4 : 7|1@1+ (1,0) [0|1] "" Vector__XXX
 SG_ GTW_w245_apsNotDisabled m4 : 8|1@1+ (1,0) [0|1] "" Vector__XXX
 SG_ GTW_w246_touchcoreHeartbeat m4 : 9|1@1+ (1,0) [0|1] "" Vector__XXX
 SG_ GTW_w255_rtc32KHzWatchdog m4 : 18|1@1+ (1,0) [0|1] "" Vector__XXX
 SG_ GTW_w260_unknownPN m4 : 23|1@1+ (1,0) [0|1] "" Vector__XXX
 SG_ GTW_w261_adspWatchdog m4 : 24|1@1+ (1,0) [0|1] "" Vector__XXX
 SG_ GTW_w262_canLogBlockDropped m4 : 25|1@1+ (1,0) [0|1] "" Vector__XXX
 SG_ GTW_w263_hrlUdpFileAvail m4 : 26|1@1+ (1,0) [0|1] "" Vector__XXX
 SG_ GTW_w264_hrlPseudoFileAvail m4 : 27|1@1+ (1,0) [0|1] "" Vector__XXX
 SG_ GTW_w265_optionFlagsError m4 : 28|1@1+ (1,0) [0|1] "" Vector__XXX
 SG_ GTW_w266_dpp1MIA m4 : 29|1@1+ (1,0) [0|1] "" Vector__XXX
 SG_ GTW_w267_dpp2MIA m4 : 30|1@1+ (1,0) [0|1] "" Vector__XXX
 SG_ GTW_w268_stoMIA m4 : 31|1@1+ (1,0) [0|1] "" Vector__XXX
 SG_ GTW_w273_BLEEPREARLEFTversionMis m4 : 36|1@1+ (1,0) [0|1] "" Vector__XXX
 SG_ GTW_w274_BLEEPREARRIGHTversionMi m4 : 37|1@1+ (1,0) [0|1] "" Vector__XXX
 SG_ GTW_w275_VDDCORE_DrMOS_Fault m4 : 38|1@1+ (1,0) [0|1] "" Vector__XXX
 SG_ GTW_w276_VDDSOC_DrMOS_Fault m4 : 39|1@1+ (1,0) [0|1] "" Vector__XXX
 SG_ GTW_w277_NonRevCDrMOSMitigationF m4 : 40|1@1+ (1,0) [0|1] "" Vector__XXX
 SG_ GTW_w278_ethSwitchCongested m4 : 41|1@1+ (1,0) [0|1] "" Vector__XXX
 SG_ GTW_w279_adspRepeatedWatchdog m4 : 42|1@1+ (1,0) [0|1] "" Vector__XXX
 SG_ GTW_w280_hrlFrameDropped m4 : 43|1@1+ (1,0) [0|1] "" Vector__XXX
 SG_ GTW_w281_likelyMissedPoke m4 : 44|1@1+ (1,0) [0|1] "" Vector__XXX
 SG_ GTW_w282_tcuPhyConfigurationFail m4 : 45|1@1+ (1,0) [0|1] "" Vector__XXX
 SG_ GTW_w309_VCUSBversionMismatch m5 : 12|1@1+ (1,0) [0|1] "" Vector__XXX
 SG_ GTW_w311_canLogQueueFullBeforeFs m5 : 14|1@1+ (1,0) [0|1] "" Vector__XXX
 SG_ GTW_w312_hrlFileIncomplete m5 : 15|1@1+ (1,0) [0|1] "" Vector__XXX
 SG_ GTW_w313_OSDActive m5 : 16|1@1+ (1,0) [0|1] "" Vector__XXX
 SG_ GTW_w314_canLogBlockWriteErr m5 : 17|1@1+ (1,0) [0|1] "" Vector__XXX
 SG_ GTW_w316_sdCardChkdskRepair m5 : 19|1@1+ (1,0) [0|1] "" Vector__XXX
 SG_ GTW_w317_sdCardChkdskRepairFaile m5 : 20|1@1+ (1,0) [0|1] "" Vector__XXX
 SG_ GTW_w322_gestureUnrecognizedFrom m5 : 25|1@1+ (1,0) [0|1] "" Vector__XXX
 SG_ GTW_w323_gestureStartOutOfStrip m5 : 26|1@1+ (1,0) [0|1] "" Vector__XXX
 SG_ GTW_w328_smartShiftDisabled m5 : 31|1@1+ (1,0) [0|1] "" Vector__XXX
 SG_ GTW_w329_FOHMversionMismatch m5 : 32|1@1+ (1,0) [0|1] "" Vector__XXX
 SG_ GTW_w330_SWSLversionMismatch m5 : 33|1@1+ (1,0) [0|1] "" Vector__XXX
 SG_ GTW_w331_SWSRversionMismatch m5 : 34|1@1+ (1,0) [0|1] "" Vector__XXX
 SG_ GTW_w332_unknownDisplayPN m5 : 35|1@1+ (1,0) [0|1] "" Vector__XXX
 SG_ GTW_w334_hrlFolderSpaceLow m5 : 37|1@1+ (1,0) [0|1] "" Vector__XXX
 SG_ GTW_w336_possibleCanTxIssue m5 : 39|1@1+ (1,0) [0|1] "" Vector__XXX
 SG_ GTW_w342_VCBLDCPPversionMismatch m5 : 45|1@1+ (1,0) [0|1] "" Vector__XXX
 SG_ GTW_w348_VCBLDCFversionMismatch m5 : 51|1@1+ (1,0) [0|1] "" Vector__XXX
 SG_ GTW_w349_VCBLDCPBversionMismatch m5 : 52|1@1+ (1,0) [0|1] "" Vector__XXX
 SG_ GTW_w350_mOSDCrcCheck m5 : 53|1@1+ (1,0) [0|1] "" Vector__XXX
 SG_ GTW_w351_sOSDCrcCheck m5 : 54|1@1+ (1,0) [0|1] "" Vector__XXX
 SG_ GTW_w352_mASILStatusCheck m5 : 55|1@1+ (1,0) [0|1] "" Vector__XXX
 SG_ GTW_w353_sASILStatusCheck m5 : 56|1@1+ (1,0) [0|1] "" Vector__XXX
 SG_ GTW_w354_EPASTPversionMismatch m5 : 57|1@1+ (1,0) [0|1] "" Vector__XXX
 SG_ GTW_w355_EPASTSversionMismatch m5 : 58|1@1+ (1,0) [0|1] "" Vector__XXX
 SG_ GTW_w356_touchGPIOStatusCheck m5 : 59|1@1+ (1,0) [0|1] "" Vector__XXX
 SG_ GTW_w358_RGBIPFLversionMismatch m5 : 61|1@1+ (1,0) [0|1] "" Vector__XXX
 SG_ GTW_w359_RGBIPFRversionMismatch m5 : 62|1@1+ (1,0) [0|1] "" Vector__XXX
 SG_ GTW_w360_RGBDOORFLversionMismatc m5 : 63|1@1+ (1,0) [0|1] "" Vector__XXX
 SG_ GTW_w361_RGBDOORRLversionMismatc m6 : 4|1@1+ (1,0) [0|1] "" Vector__XXX
 SG_ GTW_w362_RGBDOORFRversionMismatc m6 : 5|1@1+ (1,0) [0|1] "" Vector__XXX
 SG_ GTW_w363_RGBDOORRRversionMismatc m6 : 6|1@1+ (1,0) [0|1] "" Vector__XXX
 SG_ GTW_w364_BLEEPCRADLEversionMisma m6 : 7|1@1+ (1,0) [0|1] "" Vector__XXX
 SG_ GTW_w366_uiGearRequestMismatch m6 : 9|1@1+ (1,0) [0|1] "" Vector__XXX
 SG_ GTW_w376_blFailedToExecBootImg m6 : 19|1@1+ (1,0) [0|1] "" Vector__XXX
 SG_ GTW_w380_DPBversionMismatch m6 : 23|1@1+ (1,0) [0|1] "" Vector__XXX
 SG_ GTW_w381_DPBCALversionMismatch m6 : 24|1@1+ (1,0) [0|1] "" Vector__XXX
 SG_ GTW_w382_IDBversionMismatch m6 : 25|1@1+ (1,0) [0|1] "" Vector__XXX
 SG_ GTW_w383_IDB1versionMismatch m6 : 26|1@1+ (1,0) [0|1] "" Vector__XXX
 SG_ GTW_w384_IDBCALversionMismatch m6 : 27|1@1+ (1,0) [0|1] "" Vector__XXX
 SG_ GTW_w385_RCUversionMismatch m6 : 28|1@1+ (1,0) [0|1] "" Vector__XXX
 SG_ GTW_w386_RCUCALversionMismatch m6 : 29|1@1+ (1,0) [0|1] "" Vector__XXX
 SG_ GTW_w387_externalRtcReadFailure m6 : 30|1@1+ (1,0) [0|1] "" Vector__XXX
 SG_ GTW_w388_adspWatchdogSkipped m6 : 31|1@1+ (1,0) [0|1] "" Vector__XXX
 SG_ GTW_w389_rcmEventDetected m6 : 32|1@1+ (1,0) [0|1] "" Vector__XXX
 SG_ GTW_w390_displayFwQueryFailed m6 : 33|1@1+ (1,0) [0|1] "" Vector__XXX
 SG_ GTW_w391_adspMacAddrCheckFailed m6 : 34|1@1+ (1,0) [0|1] "" Vector__XXX
 SG_ GTW_w393_osdSramCrcMismatch m6 : 36|1@1+ (1,0) [0|1] "" Vector__XXX
 SG_ GTW_w394_WIPERversionMismatch m6 : 37|1@1+ (1,0) [0|1] "" Vector__XXX
 SG_ GTW_w395_lwipIcmpError m6 : 38|1@1+ (1,0) [0|1] "" Vector__XXX
 SG_ GTW_w396_alreadyInReverse m6 : 39|1@1+ (1,0) [0|1] "" Vector__XXX
 SG_ GTW_w397_alreadyInDrive m6 : 40|1@1+ (1,0) [0|1] "" Vector__XXX
 SG_ GTW_w398_awakeForExtendedTime m6 : 41|1@1+ (1,0) [0|1] "" Vector__XXX
 SG_ GTW_w399_ethIfRxTcpipQueueDrop m6 : 42|1@1+ (1,0) [0|1] "" Vector__XXX
 SG_ GTW_w400_ethlSwitchOTPIncorrect m6 : 43|1@1+ (1,0) [0|1] "" Vector__XXX
 SG_ GTW_w401_VCSEAT2LversionMismatch m6 : 44|1@1+ (1,0) [0|1] "" Vector__XXX
 SG_ GTW_w402_VCSEAT2RversionMismatch m6 : 45|1@1+ (1,0) [0|1] "" Vector__XXX
 SG_ GTW_w409_unexpectedResetCause m6 : 52|1@1+ (1,0) [0|1] "" Vector__XXX
 SG_ GTW_w410_unexpectedResetCause2 m6 : 53|1@1+ (1,0) [0|1] "" Vector__XXX
 SG_ GTW_w411_tASILStatusCheck m6 : 54|1@1+ (1,0) [0|1] "" Vector__XXX
 SG_ GTW_w414_socHeldInReset m6 : 57|1@1+ (1,0) [0|1] "" Vector__XXX
 SG_ GTW_w418_TRCMversionMismatch m6 : 61|1@1+ (1,0) [0|1] "" Vector__XXX
 SG_ GTW_w420_unexpectedCanMessageLen m6 : 63|1@1+ (1,0) [0|1] "" Vector__XXX
 SG_ GTW_w421_ModemEthLinkDown m7 : 4|1@1+ (1,0) [0|1] "" Vector__XXX
 SG_ GTW_w422_ethSwitchSevereCongesti m7 : 5|1@1+ (1,0) [0|1] "" Vector__XXX
 SG_ GTW_w427_DISPBRIDGEversionMismat m7 : 10|1@1+ (1,0) [0|1] "" Vector__XXX
 SG_ GTW_w428_LUMBAR32LversionMismatc m7 : 11|1@1+ (1,0) [0|1] "" Vector__XXX
 SG_ GTW_w429_LUMBAR32RversionMismatc m7 : 12|1@1+ (1,0) [0|1] "" Vector__XXX
 SG_ GTW_w436_possibleCanRxIssue m7 : 19|1@1+ (1,0) [0|1] "" Vector__XXX
 SG_ GTW_w437_softFlowControlNotRunni m7 : 20|1@1+ (1,0) [0|1] "" Vector__XXX
 SG_ GTW_w438_wakeSourceUnknown m7 : 21|1@1+ (1,0) [0|1] "" Vector__XXX
 SG_ GTW_w439_VCCCversionMismatch m7 : 22|1@1+ (1,0) [0|1] "" Vector__XXX
 SG_ GTW_w450_unexpectedAutopilotCont m7 : 33|1@1+ (1,0) [0|1] "" Vector__XXX
 SG_ GTW_w451_diagCanBufferExhausted m7 : 34|1@1+ (1,0) [0|1] "" Vector__XXX
 SG_ GTW_w452_diagCanStaleSocket m7 : 35|1@1+ (1,0) [0|1] "" Vector__XXX
 SG_ GTW_w453_diagCanFdSetDesync m7 : 36|1@1+ (1,0) [0|1] "" Vector__XXX
 SG_ GTW_w454_diagCanFrameOverread m7 : 37|1@1+ (1,0) [0|1] "" Vector__XXX
 SG_ GTW_w455_hrlDumpPageOwnershipErr m7 : 38|1@1+ (1,0) [0|1] "" Vector__XXX
 SG_ GTW_w456_hrlStateMachinePageOwne m7 : 39|1@1+ (1,0) [0|1] "" Vector__XXX
 SG_ GTW_w463_displayEdidReadFailed m7 : 46|1@1+ (1,0) [0|1] "" Vector__XXX
 SG_ GTW_w469_backlightFsmUnhealthy m7 : 52|1@1+ (1,0) [0|1] "" Vector__XXX

BO_ 838 GTW_autopilotOverride: 8 GTW
 SG_ GTW_autopilotOverrideState : 0|4@1+ (1,0) [0|15] "" Vector__XXX
 SG_ GTW_autopilotConfig : 4|3@1+ (1,0) [0|7] "" Vector__XXX
 SG_ GTW_autopilotOverrideConfig : 8|3@1+ (1,0) [0|7] "" Vector__XXX
 SG_ GTW_autopilotConfigSource : 11|2@1+ (1,0) [0|3] "" Vector__XXX
 SG_ GTW_autopilotOverrideExpireTime : 32|32@1+ (1,0) [0|4294967295] "" Vector__XXX

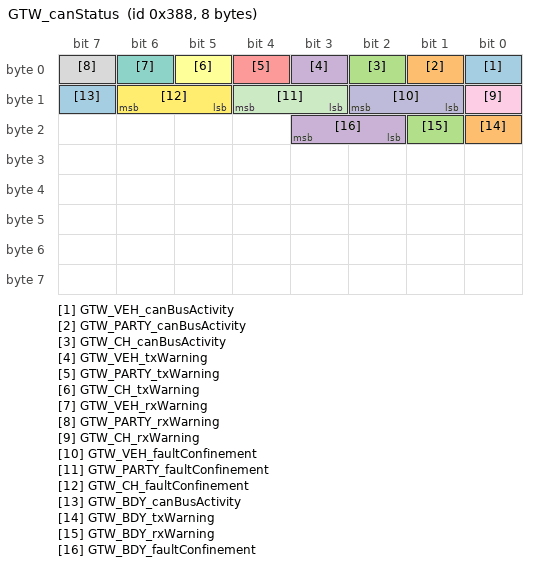
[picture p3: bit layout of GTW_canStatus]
BO_ 904 GTW_canStatus: 8 GTW
 SG_ GTW_VEH_canBusActivity : 0|1@1+ (1,0) [0|1] "" Vector__XXX
 SG_ GTW_PARTY_canBusActivity : 1|1@1+ (1,0) [0|1] "" Vector__XXX
 SG_ GTW_CH_canBusActivity : 2|1@1+ (1,0) [0|1] "" Vector__XXX
 SG_ GTW_VEH_txWarning : 3|1@1+ (1,0) [0|1] "" Vector__XXX
 SG_ GTW_PARTY_txWarning : 4|1@1+ (1,0) [0|1] "" Vector__XXX
 SG_ GTW_CH_txWarning : 5|1@1+ (1,0) [0|1] "" Vector__XXX
 SG_ GTW_VEH_rxWarning : 6|1@1+ (1,0) [0|1] "" Vector__XXX
 SG_ GTW_PARTY_rxWarning : 7|1@1+ (1,0) [0|1] "" Vector__XXX
 SG_ GTW_CH_rxWarning : 8|1@1+ (1,0) [0|1] "" Vector__XXX
 SG_ GTW_VEH_faultConfinement : 9|2@1+ (1,0) [0|3] "" Vector__XXX
 SG_ GTW_PARTY_faultConfinement : 11|2@1+ (1,0) [0|3] "" Vector__XXX
 SG_ GTW_CH_faultConfinement : 13|2@1+ (1,0) [0|3] "" Vector__XXX
 SG_ GTW_BDY_canBusActivity : 15|1@1+ (1,0) [0|1] "" Vector__XXX
 SG_ GTW_BDY_txWarning : 16|1@1+ (1,0) [0|1] "" Vector__XXX
 SG_ GTW_BDY_rxWarning : 17|1@1+ (1,0) [0|1] "" Vector__XXX
 SG_ GTW_BDY_faultConfinement : 18|2@1+ (1,0) [0|3] "" Vector__XXX

CM_ BO_ 981 "Electronic stability control message: alert matrix";
CM_ SG_ 981 ESP_matrixIndex "Electronic stability control: matrix index";
CM_ SG_ 981 ESP_a001_ecuGenericFault "Electronic stability control: a001 ecu generic fault";
CM_ SG_ 981 ESP_a002_valvesGenericFault "Electronic stability control: a002 valves generic fault";
CM_ SG_ 981 ESP_a003_outletValvesFault "Electronic stability control: a003 outlet valves fault";
CM_ SG_ 981 ESP_a004_inletValvesFault "Electronic stability control: a004 inlet valves fault";
CM_ SG_ 981 ESP_a005_HSVValvesFault "Electronic stability control: a005 HSV valves fault";
CM_ SG_ 981 ESP_a006_USVValvesFault "Electronic stability control: a006 USV valves fault";
CM_ SG_ 981 ESP_a007_pumpMotorFault "Electronic stability control: a007 pump motor fault";
CM_ SG_ 981 ESP_a008_pumpMotor12VsupplyLow "Electronic stability control: a008 pump motor12 vsupply low";
CM_ SG_ 981 ESP_a009_12VHardUndervoltage "Electronic stability control: a009 12 v hard undervoltage";
CM_ SG_ 981 ESP_a010_12VUndervoltage "Electronic stability control: a010 12 v undervoltage";
CM_ SG_ 981 ESP_a011_12VSystemUndervoltage "Electronic stability control: a011 12 v system undervoltage";
CM_ SG_ 981 ESP_a012_netUndervoltage "Electronic stability control: a012 net undervoltage";
CM_ SG_ 981 ESP_a013_valveRelayUndervoltage "Electronic stability control: a013 valve relay undervoltage";
CM_ SG_ 981 ESP_a014_WSSSupplyUndervoltage "Electronic stability control: a014 WSS supply undervoltage";
CM_ SG_ 981 ESP_a015_12VSupplyOvervoltage "Electronic stability control: a015 12 v supply overvoltage";
CM_ SG_ 981 ESP_a016_12VSystemOvervoltage "Electronic stability control: a016 12 v system overvoltage";
CM_ SG_ 981 ESP_a017_netOvervoltage "Electronic stability control: a017 net overvoltage";
CM_ SG_ 981 ESP_a018_WSSSignFrontAxle "Electronic stability control: a018 WSS sign front axle";
CM_ SG_ 981 ESP_a019_WSSSignRearAxle "Electronic stability control: a019 WSS sign rear axle";
CM_ SG_ 981 ESP_a020_WSSGenericTempFault "Electronic stability control: a020 WSS generic temp fault";
CM_ SG_ 981 ESP_a021_WSSGeneralVDiffFault "Electronic stability control: a021 WSS general v diff fault";
CM_ SG_ 981 ESP_a022_WSSDirectionFault "Electronic stability control: a022 WSS direction fault";
CM_ SG_ 981 ESP_a023_WSSSeveralSuspected "Electronic stability control: a023 WSS several suspected";
CM_ SG_ 981 ESP_a024_WSSReverseCurrent "Electronic stability control: a024 WSS reverse current";
CM_ SG_ 981 ESP_a025_FrLWSSOpenOrShortToGnd "Electronic stability control: a025 fr LWSS open or short to gnd";
CM_ SG_ 981 ESP_a026_FrLWSSShortTo12V "Electronic stability control: a026 fr LWSS short to12 v";
CM_ SG_ 981 ESP_a027_FrLWSSLineInterruption "Electronic stability control: a027 fr LWSS line interruption";
CM_ SG_ 981 ESP_a028_FrLWSSMaxSpeedExceeded "Electronic stability control: a028 fr LWSS max speed exceeded";
CM_ SG_ 981 ESP_a029_FrLWSSTooManyPulses "Electronic stability control: a029 fr LWSS too many pulses";
CM_ SG_ 981 ESP_a030_FrLWSSLostSignal "Electronic stability control: a030 fr LWSS lost signal";
CM_ SG_ 981 ESP_a031_FrLWSSNoPulsesDetected "Electronic stability control: a031 fr LWSS no pulses detected";
CM_ SG_ 981 ESP_a032_FrLWSSWrongSensorType "Electronic stability control: a032 fr LWSS wrong sensor type";
CM_ SG_ 981 ESP_a033_FrLWSSSignalNoise "Electronic stability control: a033 fr LWSS signal noise";
CM_ SG_ 981 ESP_a034_FrLWSSVDiffFault "Electronic stability control: a034 fr LWSSV diff fault";
CM_ SG_ 981 ESP_a035_FrLWSSDirectionFault "Electronic stability control: a035 fr LWSS direction fault";
CM_ SG_ 981 ESP_a036_FrLWSSLargeAirGap "Electronic stability control: a036 fr LWSS large air gap";
CM_ SG_ 981 ESP_a037_FrLWSSSupplyShortToGnd "Electronic stability control: a037 fr LWSS supply short to gnd";
CM_ SG_ 981 ESP_a038_FrLWSSGeneralFault "Electronic stability control: a038 fr LWSS general fault";
CM_ SG_ 981 ESP_a039_FrRWSSOpenOrShortToGnd "Electronic stability control: a039 fr RWSS open or short to gnd";
CM_ SG_ 981 ESP_a040_FrRWSSShortTo12V "Electronic stability control: a040 fr RWSS short to12 v";
CM_ SG_ 981 ESP_a041_FrRWSSLineInterruption "Electronic stability control: a041 fr RWSS line interruption";
CM_ SG_ 981 ESP_a042_FrRWSSMaxSpeedExceeded "Electronic stability control: a042 fr RWSS max speed exceeded";
CM_ SG_ 981 ESP_a043_FrRWSSTooManyPulses "Electronic stability control: a043 fr RWSS too many pulses";
CM_ SG_ 981 ESP_a044_FrRWSSLostSignal "Electronic stability control: a044 fr RWSS lost signal";
CM_ SG_ 981 ESP_a045_FrRWSSNoPulsesDetected "Electronic stability control: a045 fr RWSS no pulses detected";
CM_ SG_ 981 ESP_a046_FrRWSSWrongSensorType "Electronic stability control: a046 fr RWSS wrong sensor type";
CM_ SG_ 981 ESP_a047_FrRWSSSignalNoise "Electronic stability control: a047 fr RWSS signal noise";
CM_ SG_ 981 ESP_a048_FrRWSSVDiffFault "Electronic stability control: a048 fr RWSSV diff fault";
CM_ SG_ 981 ESP_a049_FrRWSSDirectionFault "Electronic stability control: a049 fr RWSS direction fault";
CM_ SG_ 981 ESP_a050_FrRWSSLargeAirGap "Electronic stability control: a050 fr RWSS large air gap";
CM_ SG_ 981 ESP_a051_FrRWSSSupplyShortToGnd "Electronic stability control: a051 fr RWSS supply short to gnd";
CM_ SG_ 981 ESP_a052_FrRWSSGeneralFault "Electronic stability control: a052 fr RWSS general fault";
CM_ SG_ 981 ESP_a053_ReLWSSOpenOrShortToGnd "Electronic stability control: a053 re LWSS open or short to gnd";
CM_ SG_ 981 ESP_a054_ReLWSSShortTo12V "Electronic stability control: a054 re LWSS short to12 v";
CM_ SG_ 981 ESP_a055_ReLWSSLineInterruption "Electronic stability control: a055 re LWSS line interruption";
CM_ SG_ 981 ESP_a056_ReLWSSMaxSpeedExceeded "Electronic stability control: a056 re LWSS max speed exceeded";
CM_ SG_ 981 ESP_a057_ReLWSSTooManyPulses "Electronic stability control: a057 re LWSS too many pulses";
CM_ SG_ 981 ESP_a058_ReLWSSLostSignal "Electronic stability control: a058 re LWSS lost signal";
CM_ SG_ 981 ESP_a059_ReLWSSNoPulsesDetected "Electronic stability control: a059 re LWSS no pulses detected";
CM_ SG_ 981 ESP_a060_ReLWSSWrongSensorType "Electronic stability control: a060 re LWSS wrong sensor type";
CM_ SG_ 981 ESP_a061_ReLWSSSignalNoise "Electronic stability control: a061 re LWSS signal noise";
CM_ SG_ 981 ESP_a062_ReLWSSVDiffFault "Electronic stability control: a062 re LWSSV diff fault";
CM_ SG_ 981 ESP_a063_ReLWSSDirectionFault "Electronic stability control: a063 re LWSS direction fault";
CM_ SG_ 981 ESP_a064_ReLWSSLargeAirGap "Electronic stability control: a064 re LWSS large air gap";
CM_ SG_ 981 ESP_a065_ReLWSSSupplyShortToGnd "Electronic stability control: a065 re LWSS supply short to gnd";
CM_ SG_ 981 ESP_a066_ReLWSSGeneralFault "Electronic stability control: a066 re LWSS general fault";
CM_ SG_ 981 ESP_a067_ReRWSSOpenOrShortToGnd "Electronic stability control: a067 re RWSS open or short to gnd";
CM_ SG_ 981 ESP_a068_ReRWSSShortTo12V "Electronic stability control: a068 re RWSS short to12 v";
CM_ SG_ 981 ESP_a069_ReRWSSLineInterruption "Electronic stability control: a069 re RWSS line interruption";
CM_ SG_ 981 ESP_a070_ReRWSSMaxSpeedExceeded "Electronic stability control: a070 re RWSS max speed exceeded";
CM_ SG_ 981 ESP_a071_ReRWSSTooManyPulses "Electronic stability control: a071 re RWSS too many pulses";
CM_ SG_ 981 ESP_a072_ReRWSSLostSignal "Electronic stability control: a072 re RWSS lost signal";
CM_ SG_ 981 ESP_a073_ReRWSSNoPulsesDetected "Electronic stability control: a073 re RWSS no pulses detected";
CM_ SG_ 981 ESP_a074_ReRWSSWrongSensorType "Electronic stability control: a074 re RWSS wrong sensor type";
CM_ SG_ 981 ESP_a075_ReRWSSSignalNoise "Electronic stability control: a075 re RWSS signal noise";
CM_ SG_ 981 ESP_a076_ReRWSSVDiffFault "Electronic stability control: a076 re RWSSV diff fault";
CM_ SG_ 981 ESP_a077_ReRWSSDirectionFault "Electronic stability control: a077 re RWSS direction fault";
CM_ SG_ 981 ESP_a078_ReRWSSLargeAirGap "Electronic stability control: a078 re RWSS large air gap";
CM_ SG_ 981 ESP_a079_ReRWSSSupplyShortToGnd "Electronic stability control: a079 re RWSS supply short to gnd";
CM_ SG_ 981 ESP_a080_ReRWSSGeneralFault "Electronic stability control: a080 re RWSS general fault";
CM_ SG_ 981 ESP_a081_PressureSensorShort "Electronic stability control: a081 pressure sensor short";
CM_ SG_ 981 ESP_a082_PMCSensorOffsetHigh "Electronic stability control: a082 PMC sensor offset high";
CM_ SG_ 981 ESP_a083_PMCSensorFault "Electronic stability control: a083 PMC sensor fault";
CM_ SG_ 981 ESP_a084_BrakeFluidReservoirLow "Electronic stability control: a084 brake fluid reservoir low";
CM_ SG_ 981 ESP_a085_BrakeSwitchStuckHigh "Electronic stability control: a085 brake switch stuck high";
CM_ SG_ 981 ESP_a086_BrakeSwitchImplausible1 "Electronic stability control: a086 brake switch implausible1";
CM_ SG_ 981 ESP_a087_BrakeSwitchImplausible3 "Electronic stability control: a087 brake switch implausible3";
CM_ SG_ 981 ESP_a088_absContinuousControl "Electronic stability control: a088 abs continuous control";
CM_ SG_ 981 ESP_a089_absNoPressureIncrease "Electronic stability control: a089 abs no pressure increase";
CM_ SG_ 981 ESP_a090_vdcContinuousControl "Electronic stability control: a090 vdc continuous control";
CM_ SG_ 981 ESP_a091_CANUndervoltage "Electronic stability control: a091 CAN undervoltage";
CM_ SG_ 981 ESP_a092_CANOvervoltage "Electronic stability control: a092 CAN overvoltage";
CM_ SG_ 981 ESP_a093_partyBusOff "Electronic stability control: a093 party bus off";
CM_ SG_ 981 ESP_a094_partyBusPassive "Electronic stability control: a094 party bus passive";
CM_ SG_ 981 ESP_a095_chassisBusOff "Electronic stability control: a095 chassis bus off";
CM_ SG_ 981 ESP_a096_chassisBusPassive "Electronic stability control: a096 chassis bus passive";
CM_ SG_ 981 ESP_a097_tcsRefSpeedNotInit "Electronic stability control: a097 tcs ref speed not init";
CM_ SG_ 981 ESP_a098_vdcRefSpeedNotInit "Electronic stability control: a098 vdc ref speed not init";
CM_ SG_ 981 ESP_a099_brakeTempModelOverheat "Electronic stability control: a099 brake temp model overheat";
CM_ SG_ 981 ESP_a100_brakeTempModelDisabled "Electronic stability control: a100 brake temp model disabled";
CM_ SG_ 981 ESP_a101_ebdFault "Electronic stability control: a101 ebd fault";
CM_ SG_ 981 ESP_a102_absFault "Electronic stability control: a102 abs fault";
CM_ SG_ 981 ESP_a103_stabilityControlFault "Electronic stability control: a103 stability control fault";
CM_ SG_ 981 ESP_a104_hbcEnabled "Electronic stability control: a104 hbc enabled";
CM_ SG_ 981 ESP_a105_ebrFault "Electronic stability control: a105 ebr fault";
CM_ SG_ 981 ESP_a106_vdcActuatorFault "Electronic stability control: a106 vdc actuator fault";
CM_ SG_ 981 ESP_a107_reserved107 "Electronic stability control: a107 reserved107";
CM_ SG_ 981 ESP_a108_reserved108 "Electronic stability control: a108 reserved108";
CM_ SG_ 981 ESP_a109_reserved109 "Electronic stability control: a109 reserved109";
CM_ SG_ 981 ESP_a110_rollerBenchActive "Electronic stability control: a110 roller bench active";
CM_ SG_ 981 ESP_a111_absActive "Electronic stability control: a111 abs active";
CM_ SG_ 981 ESP_a112_espActive "Electronic stability control: a112 esp active";
CM_ SG_ 981 ESP_a113_btcActive "Electronic stability control: a113 btc active";
CM_ SG_ 981 ESP_a114_tvdcActive "Electronic stability control: a114 tvdc active";
CM_ SG_ 981 ESP_a115_ebdActive "Electronic stability control: a115 ebd active";
CM_ SG_ 981 ESP_a116_tsmActive "Electronic stability control: a116 tsm active";
CM_ SG_ 981 ESP_a117_hbaActive "Electronic stability control: a117 hba active";
CM_ SG_ 981 ESP_a118_hfcActive "Electronic stability control: a118 hfc active";
CM_ SG_ 981 ESP_a119_hbbActive "Electronic stability control: a119 hbb active";
CM_ SG_ 981 ESP_a120_rmiActive "Electronic stability control: a120 rmi active";
CM_ SG_ 981 ESP_a121_regenTcActive "Electronic stability control: a121 regen tc active";
CM_ SG_ 981 ESP_a122_bdwActive "Electronic stability control: a122 bdw active";
CM_ SG_ 981 ESP_a123_ebrActive "Electronic stability control: a123 ebr active";
CM_ SG_ 981 ESP_a124_ebrSkidActive "Electronic stability control: a124 ebr skid active";
CM_ SG_ 981 ESP_a125_reserved125 "Electronic stability control: a125 reserved125";
CM_ SG_ 981 ESP_a126_reserved126 "Electronic stability control: a126 reserved126";
CM_ SG_ 981 ESP_a127_reserved127 "Electronic stability control: a127 reserved127";
CM_ SG_ 981 ESP_a128_reserved128 "Electronic stability control: a128 reserved128";
CM_ SG_ 981 ESP_a129_reserved129 "Electronic stability control: a129 reserved129";
CM_ SG_ 981 ESP_a130_EPAS3PsysStatusTimeout "Electronic stability control: a130 EPAS3 psys status timeout";
CM_ SG_ 981 ESP_a131_EPAS3PsysStatusDLC "Electronic stability control: a131 EPAS3 psys status DLC";
CM_ SG_ 981 ESP_a132_EPAS3PsysStatusChecksum "Electronic stability control: a132 EPAS3 psys status checksum";
CM_ SG_ 981 ESP_a133_EPAS3PsysStatusCounter "Electronic stability control: a133 EPAS3 psys status counter";
CM_ SG_ 981 ESP_a134_steeringAngleInvalid "Electronic stability control: a134 steering angle invalid";
CM_ SG_ 981 ESP_a135_steeringAngleNoCenter "Electronic stability control: a135 steering angle no center";
CM_ SG_ 981 ESP_a136_steeringAngleFrozen "Electronic stability control: a136 steering angle frozen";
CM_ SG_ 981 ESP_a137_steeringOffsetTooLarge "Electronic stability control: a137 steering offset too large";
CM_ SG_ 981 ESP_a138_steeringAngleImplaus "Electronic stability control: a138 steering angle implaus";
CM_ SG_ 981 ESP_a139_steeringAngleWrongSign "Electronic stability control: a139 steering angle wrong sign";
CM_ SG_ 981 ESP_a140_RCMInertial1Timeout "Electronic stability control: a140 RCM inertial1 timeout";
CM_ SG_ 981 ESP_a141_RCMInertial1DLC "Electronic stability control: a141 RCM inertial1 DLC";
CM_ SG_ 981 ESP_a142_RCMInertial1Checksum "Electronic stability control: a142 RCM inertial1 checksum";
CM_ SG_ 981 ESP_a143_RCMInertial1Counter "Electronic stability control: a143 RCM inertial1 counter";
CM_ SG_ 981 ESP_a144_yawMaxLatency "Electronic stability control: a144 yaw max latency";
CM_ SG_ 981 ESP_a145_yawInitFault "Electronic stability control: a145 yaw init fault";
CM_ SG_ 981 ESP_a146_yawInvalidValue "Electronic stability control: a146 yaw invalid value";
CM_ SG_ 981 ESP_a147_yawSensorNotAvailable "Electronic stability control: a147 yaw sensor not available";
CM_ SG_ 981 ESP_a148_yawSignalFault "Electronic stability control: a148 yaw signal fault";
CM_ SG_ 981 ESP_a149_yawInvalidSign "Electronic stability control: a149 yaw invalid sign";
CM_ SG_ 981 ESP_a150_yawImplausible "Electronic stability control: a150 yaw implausible";
CM_ SG_ 981 ESP_a151_RCMInertial2Timeout "Electronic stability control: a151 RCM inertial2 timeout";
CM_ SG_ 981 ESP_a152_RCMInertial2DLC "Electronic stability control: a152 RCM inertial2 DLC";
CM_ SG_ 981 ESP_a153_RCMInertial2Checksum "Electronic stability control: a153 RCM inertial2 checksum";
CM_ SG_ 981 ESP_a154_RCMInertial2Counter "Electronic stability control: a154 RCM inertial2 counter";
CM_ SG_ 981 ESP_a155_ayMaxLatency "Electronic stability control: a155 ay max latency";
CM_ SG_ 981 ESP_a156_ayInitFault "Electronic stability control: a156 ay init fault";
CM_ SG_ 981 ESP_a157_ayInvalidValue "Electronic stability control: a157 ay invalid value";
CM_ SG_ 981 ESP_a158_aySensorNotAvailable "Electronic stability control: a158 ay sensor not available";
CM_ SG_ 981 ESP_a159_aySignalFault "Electronic stability control: a159 ay signal fault";
CM_ SG_ 981 ESP_a160_ayRangeExceeded "Electronic stability control: a160 ay range exceeded";
CM_ SG_ 981 ESP_a161_ayOffsetExceeded "Electronic stability control: a161 ay offset exceeded";
CM_ SG_ 981 ESP_a162_ayImplausible "Electronic stability control: a162 ay implausible";
CM_ SG_ 981 ESP_a163_axMaxLatency "Electronic stability control: a163 ax max latency";
CM_ SG_ 981 ESP_a164_axInitFault "Electronic stability control: a164 ax init fault";
CM_ SG_ 981 ESP_a165_axInvalidValue "Electronic stability control: a165 ax invalid value";
CM_ SG_ 981 ESP_a166_axSensorNotAvailable "Electronic stability control: a166 ax sensor not available";
CM_ SG_ 981 ESP_a167_axSignalFault "Electronic stability control: a167 ax signal fault";
CM_ SG_ 981 ESP_a168_axRangeExceeded "Electronic stability control: a168 ax range exceeded";
CM_ SG_ 981 ESP_a169_axOffsetExceeded "Electronic stability control: a169 ax offset exceeded";
CM_ SG_ 981 ESP_a170_axSignalFrozen "Electronic stability control: a170 ax signal frozen";
CM_ SG_ 981 ESP_a171_axImplausible "Electronic stability control: a171 ax implausible";
CM_ SG_ 981 ESP_a172_IBSTparty1Timeout "Electronic stability control: a172 IBS tparty1 timeout";
CM_ SG_ 981 ESP_a173_IBSTparty1DLC "Electronic stability control: a173 IBS tparty1 DLC";
CM_ SG_ 981 ESP_a174_IBSTparty1Checksum "Electronic stability control: a174 IBS tparty1 checksum";
CM_ SG_ 981 ESP_a175_IBSTparty1Counter "Electronic stability control: a175 IBS tparty1 counter";
CM_ SG_ 981 ESP_a176_IBSTEBRNotAvailable "Electronic stability control: a176 IBSTEBR not available";
CM_ SG_ 981 ESP_a177_IBSTOutputRodDrvInvalid "Electronic stability control: a177 IBST output rod drv invalid";
CM_ SG_ 981 ESP_a178_IBSTOutputRodActInvalid "Electronic stability control: a178 IBST output rod act invalid";
CM_ SG_ 981 ESP_a179_IBSTparty2Timeout "Electronic stability control: a179 IBS tparty2 timeout";
CM_ SG_ 981 ESP_a180_IBSTparty2Checksum "Electronic stability control: a180 IBS tparty2 checksum";
CM_ SG_ 981 ESP_a181_IBSTparty2DLC "Electronic stability control: a181 IBS tparty2 DLC";
CM_ SG_ 981 ESP_a182_IBSTparty2Counter "Electronic stability control: a182 IBS tparty2 counter";
CM_ SG_ 981 ESP_a183_IBSTStatusOff "Electronic stability control: a183 IBST status off";
CM_ SG_ 981 ESP_a184_IBSTpRunoutInvalid "Electronic stability control: a184 IBS tp runout invalid";
CM_ SG_ 981 ESP_a185_IBSTFeedforwardBackup "Electronic stability control: a185 IBST feedforward backup";
CM_ SG_ 981 ESP_a186_IBSTBrakeAppliedInvalid "Electronic stability control: a186 IBST brake applied invalid";
CM_ SG_ 981 ESP_a187_DIbtcRequestTimeout "Electronic stability control: a187 d ibtc request timeout";
CM_ SG_ 981 ESP_a188_DIbtcRequestDLC "Electronic stability control: a188 d ibtc request DLC";
CM_ SG_ 981 ESP_a189_DIbtcRequestChecksum "Electronic stability control: a189 d ibtc request checksum";
CM_ SG_ 981 ESP_a190_DIbtcRequestCounter "Electronic stability control: a190 d ibtc request counter";
CM_ SG_ 981 ESP_a191_DIchassisControlTimeout "Electronic stability control: a191 d ichassis control timeout";
CM_ SG_ 981 ESP_a192_DIchassisControlDLC "Electronic stability control: a192 d ichassis control DLC";
CM_ SG_ 981 ESP_a193_DIchassisControlChecksu "Electronic stability control: a193 d ichassis control checksum";
CM_ SG_ 981 ESP_a194_DIchassisControlCounter "Electronic stability control: a194 d ichassis control counter";
CM_ SG_ 981 ESP_a195_ptcStateInvalid "Electronic stability control: a195 ptc state invalid";
CM_ SG_ 981 ESP_a196_DIsystemStatusTimeout "Electronic stability control: a196 d isystem status timeout";
CM_ SG_ 981 ESP_a197_DIsystemStatusDLC "Electronic stability control: a197 d isystem status DLC";
CM_ SG_ 981 ESP_a198_DIsystemStatusChecksum "Electronic stability control: a198 d isystem status checksum";
CM_ SG_ 981 ESP_a199_DIsystemStatusCounter "Electronic stability control: a199 d isystem status counter";
CM_ SG_ 981 ESP_a200_reverseGearStuckHigh "Electronic stability control: a200 reverse gear stuck high";
CM_ SG_ 981 ESP_a201_reverseGearStuckLow "Electronic stability control: a201 reverse gear stuck low";
CM_ SG_ 981 ESP_a202_accelPedalInvalid "Electronic stability control: a202 accel pedal invalid";
CM_ SG_ 981 ESP_a203_DItorqueTimeout "Electronic stability control: a203 d itorque timeout";
CM_ SG_ 981 ESP_a204_DItorqueDLC "Electronic stability control: a204 d itorque DLC";
CM_ SG_ 981 ESP_a205_DItorqueChecksum "Electronic stability control: a205 d itorque checksum";
CM_ SG_ 981 ESP_a206_DItorqueCounter "Electronic stability control: a206 d itorque counter";
CM_ SG_ 981 ESP_a207_DITorqueCommandInvalid "Electronic stability control: a207 DI torque command invalid";
CM_ SG_ 981 ESP_a208_DIRPMInvalid "Electronic stability control: a208 DIRPM invalid";
CM_ SG_ 981 ESP_a209_DITorqueActualInvalid "Electronic stability control: a209 DI torque actual invalid";
CM_ SG_ 981 ESP_a210_DIStorqueTimeout "Electronic stability control: a210 DI storque timeout";
CM_ SG_ 981 ESP_a211_DIStorqueDLC "Electronic stability control: a211 DI storque DLC";
CM_ SG_ 981 ESP_a212_DIStorqueChecksum "Electronic stability control: a212 DI storque checksum";
CM_ SG_ 981 ESP_a213_DIStorqueCounter "Electronic stability control: a213 DI storque counter";
CM_ SG_ 981 ESP_a214_DISTorqueCommandInvalid "Electronic stability control: a214 DIS torque command invalid";
CM_ SG_ 981 ESP_a215_DISRPMInvalid "Electronic stability control: a215 DISRPM invalid";
CM_ SG_ 981 ESP_a216_DISTorqueActualInvalid "Electronic stability control: a216 DIS torque actual invalid";
CM_ SG_ 981 ESP_a217_DIvdcLeftTimeout "Electronic stability control: a217 d ivdc left timeout";
CM_ SG_ 981 ESP_a218_DIvdcLeftDLC "Electronic stability control: a218 d ivdc left DLC";
CM_ SG_ 981 ESP_a219_DIvdcLeftChecksum "Electronic stability control: a219 d ivdc left checksum";
CM_ SG_ 981 ESP_a220_DIvdcLeftCounter "Electronic stability control: a220 d ivdc left counter";
CM_ SG_ 981 ESP_a221_DIvdcRightTimeout "Electronic stability control: a221 d ivdc right timeout";
CM_ SG_ 981 ESP_a222_DIvdcRightDLC "Electronic stability control: a222 d ivdc right DLC";
CM_ SG_ 981 ESP_a223_DIvdcRightChecksum "Electronic stability control: a223 d ivdc right checksum";
CM_ SG_ 981 ESP_a224_DIvdcRightCounter "Electronic stability control: a224 d ivdc right counter";
CM_ SG_ 981 ESP_a225_configMismatch "Electronic stability control: a225 config mismatch";
CM_ SG_ 981 ESP_a226_bdwRequestInvalid "Electronic stability control: a226 bdw request invalid";
CM_ SG_ 981 ESP_a227_bdwRequestActiveInvalid "Electronic stability control: a227 bdw request active invalid";
CM_ SG_ 981 ESP_a228_GTWvinTimeout "Electronic stability control: a228 GT wvin timeout";
CM_ SG_ 981 ESP_a229_GTWvinDLC "Electronic stability control: a229 GT wvin DLC";
CM_ SG_ 981 ESP_a230_vinNotLearned "Electronic stability control: a230 vin not learned";
CM_ SG_ 981 ESP_a231_storedVINMismatch "Electronic stability control: a231 stored VIN mismatch";
CM_ SG_ 981 ESP_a232_PMstate2Timeout "Electronic stability control: a232 p mstate2 timeout";
CM_ SG_ 981 ESP_a233_PMstate2Checksum "Electronic stability control: a233 p mstate2 checksum";
CM_ SG_ 981 ESP_a234_PMstate2DLC "Electronic stability control: a234 p mstate2 DLC";
CM_ SG_ 981 ESP_a235_PMstate2Counter "Electronic stability control: a235 p mstate2 counter";
CM_ SG_ 981 ESP_a236_ebrCommandStateInvalid "Electronic stability control: a236 ebr command state invalid";
CM_ SG_ 981 ESP_a237_vdcCommandStateInvalid "Electronic stability control: a237 vdc command state invalid";
CM_ SG_ 981 ESP_a238_UIodoTimeout "Electronic stability control: a238 u iodo timeout";
CM_ SG_ 981 ESP_a239_UIodoDLC "Electronic stability control: a239 u iodo DLC";
CM_ SG_ 981 ESP_a240_LVPowerStateTimeout "Electronic stability control: a240 LV power state timeout";
CM_ SG_ 981 ESP_a241_LVPowerStateChecksum "Electronic stability control: a241 LV power state checksum";
CM_ SG_ 981 ESP_a242_LVPowerStateDLC "Electronic stability control: a242 LV power state DLC";
CM_ SG_ 981 ESP_a243_LVPowerStateCounter "Electronic stability control: a243 LV power state counter";
CM_ SG_ 981 ESP_a244_LVOffStateInvalid "Electronic stability control: a244 LV off state invalid";
CM_ SG_ 981 ESP_a245_LVGoingDownStateInvalid "Electronic stability control: a245 LV going down state invalid";
CM_ SG_ 981 ESP_a246_VCFRONTsensorTimeout "Electronic stability control: a246 VCFRON tsensor timeout";
CM_ SG_ 981 ESP_a247_VCFRONTsensorDLC "Electronic stability control: a247 VCFRON tsensor DLC";
CM_ SG_ 981 ESP_a248_vdcBrkeTrqTarFrLInvalid "Electronic stability control: a248 vdc brke trq tar fr l invalid";
CM_ SG_ 981 ESP_a249_vdcBrkeTrqTarFrRInvalid "Electronic stability control: a249 vdc brke trq tar fr r invalid";
CM_ SG_ 981 ESP_a250_vdcBrkeTrqTarReLInvalid "Electronic stability control: a250 vdc brke trq tar re l invalid";
CM_ SG_ 981 ESP_a251_vdcBrkeTrqTarReRInvalid "Electronic stability control: a251 vdc brke trq tar re r invalid";
CM_ SG_ 981 ESP_a252_vdcWhlSlipLimFrLInvalid "Electronic stability control: a252 vdc whl slip lim fr l invalid";
CM_ SG_ 981 ESP_a253_vdcWhlSlipLimFrRInvalid "Electronic stability control: a253 vdc whl slip lim fr r invalid";
CM_ SG_ 981 ESP_a254_vdcWhlSlipLimReLInvalid "Electronic stability control: a254 vdc whl slip lim re l invalid";
CM_ SG_ 981 ESP_a255_vdcWhlSlipLimReRInvalid "Electronic stability control: a255 vdc whl slip lim re r invalid";
CM_ SG_ 981 ESP_a256_epbmStatusTimeout "Electronic stability control: a256 epbm status timeout";
CM_ SG_ 981 ESP_a257_epbmStatusChecksum "Electronic stability control: a257 epbm status checksum";
CM_ SG_ 981 ESP_a258_epbmStatusDLC "Electronic stability control: a258 epbm status DLC";
CM_ SG_ 981 ESP_a259_epbmStatusCounter "Electronic stability control: a259 epbm status counter";
CM_ SG_ 981 ESP_a260_epblStatusTimeout "Electronic stability control: a260 epbl status timeout";
CM_ SG_ 981 ESP_a261_epblStatusChecksum "Electronic stability control: a261 epbl status checksum";
CM_ SG_ 981 ESP_a262_epblStatusDLC "Electronic stability control: a262 epbl status DLC";
CM_ SG_ 981 ESP_a263_epblStatusCounter "Electronic stability control: a263 epbl status counter";
CM_ SG_ 981 ESP_a264_pumpSpeedLimitInvalid "Electronic stability control: a264 pump speed limit invalid";
CM_ SG_ 981 ESP_a265_DIRELtorqueTimeout "Electronic stability control: a265 DIRE ltorque timeout";
CM_ SG_ 981 ESP_a266_DIRELtorqueDLC "Electronic stability control: a266 DIRE ltorque DLC";
CM_ SG_ 981 ESP_a267_DIRELtorqueChecksum "Electronic stability control: a267 DIRE ltorque checksum";
CM_ SG_ 981 ESP_a268_DIRELtorqueCounter "Electronic stability control: a268 DIRE ltorque counter";
CM_ SG_ 981 ESP_a269_DIRELTorqueCommandInval "Electronic stability control: a269 DIREL torque command invalid";
CM_ SG_ 981 ESP_a270_DIRELRPMInvalid "Electronic stability control: a270 DIRELRPM invalid";
CM_ SG_ 981 ESP_a271_DIRELTorqueActualInvali "Electronic stability control: a271 DIREL torque actual invalid";
CM_ SG_ 981 ESP_a272_DIRERtorqueTimeout "Electronic stability control: a272 DIRE rtorque timeout";
CM_ SG_ 981 ESP_a273_DIRERtorqueDLC "Electronic stability control: a273 DIRE rtorque DLC";
CM_ SG_ 981 ESP_a274_DIRERtorqueChecksum "Electronic stability control: a274 DIRE rtorque checksum";
CM_ SG_ 981 ESP_a275_DIRERtorqueCounter "Electronic stability control: a275 DIRE rtorque counter";
CM_ SG_ 981 ESP_a276_DIRERTorqueCommandInval "Electronic stability control: a276 DIRER torque command invalid";
CM_ SG_ 981 ESP_a277_DIRERRPMInvalid "Electronic stability control: a277 DIRERRPM invalid";
CM_ SG_ 981 ESP_a278_DIRERTorqueActualInvali "Electronic stability control: a278 DIRER torque actual invalid";
CM_ SG_ 981 ESP_a279_lifetimeManagementOverr "Electronic stability control: a279 lifetime management overrun";
CM_ SG_ 981 ESP_a280_trackModeABSEnabled "Electronic stability control: a280 track mode ABS enabled";
CM_ SG_ 981 ESP_a281_trackModeABSdisabled "Electronic stability control: a281 track mode AB sdisabled";
CM_ SG_ 981 ESP_a282_trackModeABSRequestInva "Electronic stability control: a282 track mode ABS request invalid";
CM_ SG_ 981 ESP_a283_secondaryCollisionMitig "Electronic stability control: a283 secondary collision mitigation active";
CM_ SG_ 981 ESP_a284_scmRequestInvalidChecks "Electronic stability control: a284 scm request invalid checksum";
CM_ SG_ 981 ESP_a285_scmRequestDLC "Electronic stability control: a285 scm request DLC";
CM_ SG_ 981 ESP_a286_hydroplaneDetected "Electronic stability control: a286 hydroplane detected";
CM_ SG_ 981 ESP_a287_failedBrakeCircuitDetec "Electronic stability control: a287 failed brake circuit detected";
CM_ SG_ 981 ESP_a288_leftBusOff "Electronic stability control: a288 left bus off";
CM_ SG_ 981 ESP_a289_leftBusPassive "Electronic stability control: a289 left bus passive";
CM_ SG_ 981 ESP_a290_brakeBusOff "Electronic stability control: a290 brake bus off";
CM_ SG_ 981 ESP_a291_brakeBusPassive "Electronic stability control: a291 brake bus passive";
CM_ SG_ 981 ESP_a292_PEPSstatusTimeout "Electronic stability control: a292 PEP sstatus timeout";
CM_ SG_ 981 ESP_a293_PEPSstatusDLC "Electronic stability control: a293 PEP sstatus DLC";
CM_ SG_ 981 ESP_a294_PEPSstatusChecksum "Electronic stability control: a294 PEP sstatus checksum";
CM_ SG_ 981 ESP_a295_PEPSstatusCounter "Electronic stability control: a295 PEP sstatus counter";
CM_ SG_ 981 ESP_a296_roadWheelAngleHealthDeg "Electronic stability control: a296 road wheel angle health degraded";
CM_ SG_ 981 ESP_a297_roadWheelAngleHealthFau "Electronic stability control: a297 road wheel angle health faulted";
CM_ SG_ 981 ESP_a298_RSArearSteerStatusTimeo "Electronic stability control: a298 RS arear steer status timeout";
CM_ SG_ 981 ESP_a299_RSArearSteerStatusDLC "Electronic stability control: a299 RS arear steer status DLC";
CM_ SG_ 981 ESP_a300_RSArearSteerStatusCheck "Electronic stability control: a300 RS arear steer status checksum";
CM_ SG_ 981 ESP_a301_PEPSstatusCounter "Electronic stability control: a301 PEP sstatus counter";
CM_ SG_ 981 ESP_a302_rearRoadWheelAngleHealt "Electronic stability control: a302 rear road wheel angle health degraded";
CM_ SG_ 981 ESP_a303_rearRoadWheelAngleHealt "Electronic stability control: a303 rear road wheel angle health faulted";
CM_ SG_ 981 ESP_a304_rearVCLVPowerStateTimeo "Electronic stability control: a304 rear VCLV power state timeout";
CM_ SG_ 981 ESP_a305_rearVCLVPowerStateDLC "Electronic stability control: a305 rear VCLV power state DLC";
CM_ SG_ 981 ESP_a306_rearVCLVPowerStateCheck "Electronic stability control: a306 rear VCLV power state checksum";
CM_ SG_ 981 ESP_a307_rearVCLVPowerStateCount "Electronic stability control: a307 rear VCLV power state counter";
CM_ SG_ 981 ESP_a308_evacFillNotComplete "Electronic stability control: a308 evac fill not complete";
CM_ SG_ 981 ESP_a309_factoryModeActive "Electronic stability control: a309 factory mode active";
CM_ SG_ 981 ESP_a310_brakeLatencyReductionAc "Electronic stability control: a310 brake latency reduction active";
CM_ SG_ 981 ESP_a311_aesActive "Electronic stability control: a311 aes active";
CM_ SG_ 981 ESP_a312_undefinedAlertDetected "Electronic stability control: a312 undefined alert detected";
CM_ SG_ 981 ESP_a313_cdpRequestStateInvalid "Electronic stability control: a313 cdp request state invalid";
CM_ SG_ 981 ESP_a314_aesFault "Electronic stability control: a314 aes fault";
CM_ SG_ 981 ESP_a315_EMCBackup11Timeout "Electronic stability control: a315 EMC backup11 timeout";
CM_ SG_ 981 ESP_a316_EMCBackup11DLC "Electronic stability control: a316 EMC backup11 DLC";
CM_ SG_ 981 ESP_a317_EMCBackup11Checksum "Electronic stability control: a317 EMC backup11 checksum";
CM_ SG_ 981 ESP_a318_EMCBackup11Counter "Electronic stability control: a318 EMC backup11 counter";
CM_ SG_ 981 ESP_a319_AES_BackupActuatorActiv "Electronic stability control: a319 AES backup actuator active";
CM_ SG_ 981 ESP_a320_DPB_actuator1Counter "Electronic stability control: a320 DPB actuator1 counter";
CM_ SG_ 981 ESP_a321_DPB_actuator1Checksum "Electronic stability control: a321 DPB actuator1 checksum";
CM_ SG_ 981 ESP_a322_DPB_actuator1DLC "Electronic stability control: a322 DPB actuator1 DLC";
CM_ SG_ 981 ESP_a323_DPB_actuator1Timeout "Electronic stability control: a323 DPB actuator1 timeout";
CM_ SG_ 981 ESP_a324_DPB_actuator2Counter "Electronic stability control: a324 DPB actuator2 counter";
CM_ SG_ 981 ESP_a325_DPB_actuator2Checksum "Electronic stability control: a325 DPB actuator2 checksum";
CM_ SG_ 981 ESP_a326_DPB_actuator2DLC "Electronic stability control: a326 DPB actuator2 DLC";
CM_ SG_ 981 ESP_a327_DPB_actuator2Timeout "Electronic stability control: a327 DPB actuator2 timeout";
CM_ SG_ 981 ESP_a328_DPB_actuator3Counter "Electronic stability control: a328 DPB actuator3 counter";
CM_ SG_ 981 ESP_a329_DPB_actuator3Checksum "Electronic stability control: a329 DPB actuator3 checksum";
CM_ SG_ 981 ESP_a330_DPB_actuator3DLC "Electronic stability control: a330 DPB actuator3 DLC";
CM_ SG_ 981 ESP_a331_DPB_actuator3Timeout "Electronic stability control: a331 DPB actuator3 timeout";
CM_ SG_ 981 ESP_a332_PressureSensorValHigh "Electronic stability control: a332 pressure sensor val high";
CM_ SG_ 981 ESP_a333_ActCircuitNoPressure "Electronic stability control: a333 act circuit no pressure";
CM_ SG_ 981 ESP_a334_BrakePedalAppliedInvali "Electronic stability control: a334 brake pedal applied invalid";
CM_ SG_ 981 ESP_a335_LdmFxTarBrakeActInvalid "Electronic stability control: a335 ldm fx tar brake act invalid";
CM_ SG_ 981 ESP_a336_FxTargetDriverInvalid "Electronic stability control: a336 fx target driver invalid";
CM_ SG_ 981 ESP_a337_pReductionPotentialInva "Electronic stability control: a337 p reduction potential invalid";
CM_ SG_ 981 ESP_a338_pRunoutInvalid "Electronic stability control: a338 p runout invalid";
CM_ SG_ 981 ESP_a339_sInputRodInvalid "Electronic stability control: a339 s input rod invalid";
CM_ SG_ 981 ESP_a340_RollerBenchMisuse "Electronic stability control: a340 roller bench misuse";
CM_ SG_ 981 ESP_a341_EnhancedPressureBuildAc "Electronic stability control: a341 enhanced pressure build active";
CM_ SG_ 981 ESP_a342_EnhancedPressureBuildNo "Electronic stability control: a342 enhanced pressure build not available";
CM_ SG_ 981 ESP_a343_EnhancedPressureBuildLt "Electronic stability control: a343 enhanced pressure build ltm reached";
CM_ SG_ 981 ESP_a344_DIbrakeCommandCounter "Electronic stability control: a344 d ibrake command counter";
CM_ SG_ 981 ESP_a345_DIbrakeCommandChecksum "Electronic stability control: a345 d ibrake command checksum";
CM_ SG_ 981 ESP_a346_DIbrakeCommandDLC "Electronic stability control: a346 d ibrake command DLC";
CM_ SG_ 981 ESP_a347_DIbrakeCommandTimeout "Electronic stability control: a347 d ibrake command timeout";
CM_ SG_ 981 ESP_a348_brakeCmdStateInvalid "Electronic stability control: a348 brake cmd state invalid";
CM_ SG_ 981 ESP_a349_ForceLampToRed "Electronic stability control: a349 force lamp to red";
CM_ SG_ 981 ESP_a350_ActuatorOff "Electronic stability control: a350 actuator off";
CM_ SG_ 981 ESP_a351_ActuatorYellowLampReque "Electronic stability control: a351 actuator yellow lamp requested";
CM_ SG_ 981 ESP_a352_ActuatorLDMFailure "Electronic stability control: a352 actuator LDM failure";
CM_ SG_ 981 ESP_a353_PressureSensorImplausHi "Electronic stability control: a353 pressure sensor implaus high";
CM_ SG_ 981 ESP_a354_HBCRequestInvalid "Electronic stability control: a354 HBC request invalid";
CM_ SG_ 981 ESP_a355_RecuStatusActInvalid "Electronic stability control: a355 recu status act invalid";
CM_ SG_ 981 ESP_a356_DIFAxleTorqueInvalid "Electronic stability control: a356 DIF axle torque invalid";
CM_ SG_ 981 ESP_a357_DIRAxleTorqueInvalid "Electronic stability control: a357 DIR axle torque invalid";
CM_ SG_ 981 ESP_a358_externalActuatorFallbac "Electronic stability control: a358 external actuator fallback";
CM_ SG_ 981 ESP_a359_externalActuatorNoExtRe "Electronic stability control: a359 external actuator no ext req";
CM_ SG_ 981 ESP_a360_BBbrakeActuationTimeout "Electronic stability control: a360 b bbrake actuation timeout";
CM_ SG_ 981 ESP_a361_BBbrakeActuationDLC "Electronic stability control: a361 b bbrake actuation DLC";
CM_ SG_ 981 ESP_a362_BBbrakeActuationChecksu "Electronic stability control: a362 b bbrake actuation checksum";
CM_ SG_ 981 ESP_a363_BBbrakeActuationCounter "Electronic stability control: a363 b bbrake actuation counter";
CM_ SG_ 981 ESP_a364_DIgearInvalid "Electronic stability control: a364 d igear invalid";
CM_ SG_ 981 ESP_a365_TCSInputQualityTooLow "Electronic stability control: a365 TCS input quality too low";
CM_ SG_ 981 ESP_a366_ActuatorBlendingModeReq "Electronic stability control: a366 actuator blending mode req not available";
CM_ SG_ 981 ESP_a367_CBDS_fillBufferThreshol "Electronic stability control: a367 CBDS fill buffer threshold";
CM_ SG_ 981 ESP_a368_CBDS_fmeInternalEvent "Electronic stability control: a368 CBDS fme internal event";
CM_ SG_ 981 ESP_a369_LargeLeakageDetectedByD "Electronic stability control: a369 large leakage detected by DPB";
CM_ SG_ 981 ESP_a370_DPB_actuator4Timeout "Electronic stability control: a370 DPB actuator4 timeout";
CM_ SG_ 981 ESP_a371_DPB_actuator4DLC "Electronic stability control: a371 DPB actuator4 DLC";
CM_ SG_ 981 ESP_a372_DPB_actuator4Checksum "Electronic stability control: a372 DPB actuator4 checksum";
CM_ SG_ 981 ESP_a373_DPB_actuator4Counter "Electronic stability control: a373 DPB actuator4 counter";
CM_ SG_ 981 ESP_a374_StatInvalid_DI_FullSNA "Electronic stability control: a374 stat invalid DI full SNA";
CM_ SG_ 981 ESP_a375_PM_locStateCounter "Electronic stability control: a375 PM loc state counter";
CM_ SG_ 981 ESP_a376_PM_locStateChecksum "Electronic stability control: a376 PM loc state checksum";
CM_ SG_ 981 ESP_a377_PM_locStateDLC "Electronic stability control: a377 PM loc state DLC";
CM_ SG_ 981 ESP_a378_PM_locStateTimeout "Electronic stability control: a378 PM loc state timeout";
CM_ SG_ 981 ESP_a379_DASredundantBrakingCont "Electronic stability control: a379 DA sredundant braking control party checksum";
CM_ SG_ 981 ESP_a380_DASredundantBrakingCont "Electronic stability control: a380 DA sredundant braking control party counter";
CM_ SG_ 981 ESP_a381_DASredundantBrakingCont "Electronic stability control: a381 DA sredundant braking control party DLC";
CM_ SG_ 981 ESP_a382_DASredundantBrakingCont "Electronic stability control: a382 DA sredundant braking control party timeout";
CM_ SG_ 981 ESP_a383_DASredundantBrakingCont "Electronic stability control: a383 DA sredundant braking control chassis checksum";
CM_ SG_ 981 ESP_a384_DASredundantBrakingCont "Electronic stability control: a384 DA sredundant braking control chassis counter";
CM_ SG_ 981 ESP_a385_DASredundantBrakingCont "Electronic stability control: a385 DA sredundant braking control chassis DLC";
CM_ SG_ 981 ESP_a386_DASredundantBrakingCont "Electronic stability control: a386 DA sredundant braking control chassis timeout";
CM_ SG_ 981 ESP_a387_DIlocStatus2Checksum "Electronic stability control: a387 d iloc status2 checksum";
CM_ SG_ 981 ESP_a388_DIlocStatus2Counter "Electronic stability control: a388 d iloc status2 counter";
CM_ SG_ 981 ESP_a389_DIlocStatus2DLC "Electronic stability control: a389 d iloc status2 DLC";
CM_ SG_ 981 ESP_a390_DIlocStatus2Timeout "Electronic stability control: a390 d iloc status2 timeout";
CM_ SG_ 981 ESP_a391_standaloneEBRActive "Electronic stability control: a391 standalone EBR active";
CM_ SG_ 981 ESP_a392_driverlessArmingUnavail "Electronic stability control: a392 driverless arming unavailable";
CM_ SG_ 981 ESP_a393_EMCBackup21Checksum "Electronic stability control: a393 EMC backup21 checksum";
CM_ SG_ 981 ESP_a394_EMCBackup21Counter "Electronic stability control: a394 EMC backup21 counter";
CM_ SG_ 981 ESP_a395_EMCBackup21DLC "Electronic stability control: a395 EMC backup21 DLC";
CM_ SG_ 981 ESP_a396_EMCBackup21Timeout "Electronic stability control: a396 EMC backup21 timeout";
CM_ SG_ 981 ESP_a397_epbrStatusTimeout "Electronic stability control: a397 epbr status timeout";
CM_ SG_ 981 ESP_a398_epbrStatusChecksum "Electronic stability control: a398 epbr status checksum";
CM_ SG_ 981 ESP_a399_epbrStatusDLC "Electronic stability control: a399 epbr status DLC";
CM_ SG_ 981 ESP_a400_epbrStatusCounter "Electronic stability control: a400 epbr status counter";
CM_ SG_ 981 ESP_a401_bsmCircuitFailure "Electronic stability control: a401 bsm circuit failure";
CM_ SG_ 981 ESP_a402_bsmPtsPlausToPsTooHigh "Electronic stability control: a402 bsm pts plaus to ps too high";
CM_ SG_ 981 ESP_a403_batMotorVoltage "Electronic stability control: a403 bat motor voltage";
CM_ SG_ 981 ESP_a404_batPressureCircuit1 "Electronic stability control: a404 bat pressure circuit1";
CM_ SG_ 981 ESP_a405_batPressureCircuit2 "Electronic stability control: a405 bat pressure circuit2";
CM_ SG_ 981 ESP_a406_DIespActuatorTestTimeou "Electronic stability control: a406 d iesp actuator test timeout";
CM_ SG_ 981 ESP_a407_DIespActuatorTestChecks "Electronic stability control: a407 d iesp actuator test checksum";
CM_ SG_ 981 ESP_a408_DIespActuatorTestDLC "Electronic stability control: a408 d iesp actuator test DLC";
CM_ SG_ 981 ESP_a409_DIespActuatorTestCounte "Electronic stability control: a409 d iesp actuator test counter";
CM_ BO_ 808 "Electronic stability control message: info";
CM_ SG_ 808 ESP_infoIndex "Electronic stability control: info index";
CM_ SG_ 808 ESP_infoBuildType "Electronic stability control: info build type";
CM_ SG_ 808 ESP_vehFlashMode "Electronic stability control: veh flash mode";
CM_ SG_ 808 ESP_infoComponentID "Electronic stability control: info component ID";
CM_ SG_ 808 ESP_infoPcbaID "Electronic stability control: info pcba ID";
CM_ SG_ 808 ESP_infoAssemblyID "Electronic stability control: info assembly ID";
CM_ SG_ 808 ESP_infoUsageID "Electronic stability control: info usage ID";
CM_ SG_ 808 ESP_infoSubUsageID "Electronic stability control: info sub usage ID";
CM_ SG_ 808 ESP_infoApplicationCRC "Indicating the Application CRC value of firmware running in system.";
CM_ SG_ 808 ESP_infoVehicleVariant "Electronic stability control: info vehicle variant";
CM_ SG_ 808 ESP_infoSubcomponent1 "Electronic stability control: info subcomponent1";
CM_ SG_ 808 ESP_infoBootUdsProtoVersion "Electronic stability control: info boot uds proto version";
CM_ SG_ 808 ESP_infoBootloaderCRC "Electronic stability control: info bootloader CRC";
CM_ SG_ 808 ESP_infoVariantCRC "Indicating the Calibration CRC value of firmware running in system.";
CM_ BO_ 1236 "Electronic stability control message: party3";
CM_ SG_ 1236 ESP_party3Crc "Electronic stability control: party3 crc";
CM_ SG_ 1236 ESP_party3Counter "Electronic stability control: party3 counter";
CM_ SG_ 1236 ESP_absActive "Electronic stability control: abs active";
CM_ SG_ 1236 ESP_vehicleStandstill "Indicates that the vehicle is completely stationary.";
CM_ SG_ 1236 ESP_vehicleStandstillQF "Qualifier of ESP_vehicleStandstill.";
CM_ SG_ 1236 ESP_pEstMaximum "Maximum of estimated wheel braking pressure.";
CM_ SG_ 1236 ESP_privateVehicleSpd "Vehicle speed as calculated by the ESP from the wheel speed sensors.";
CM_ SG_ 1236 ESP_decoupledBrakePressOffsetCom "Master cylinder pressure sensor offset";
CM_ SG_ 1236 ESP_privateVehicleSpdQF "ESP private vehicle speed qualifier";
CM_ SG_ 1236 ESP_brakeMasterCylPress "Master cylinder pressure measured in the ESP.";
CM_ SG_ 1236 ESP_brakeMasterCylPressQF "Reports the brake master cylinder pressure signal (ESP_brakeMasterCylPress) qualification status.";
CM_ BO_ 325 "Electronic stability control message: status";
CM_ SG_ 325 ESP_statusChecksum "Electronic stability control: status checksum";
CM_ SG_ 325 ESP_statusCounter "Electronic stability control: status counter";
CM_ SG_ 325 ESP_espModeActive "Electronic stability control: esp mode active";
CM_ SG_ 325 ESP_stabilityControlSts2 "Electronic stability control: stability control sts2";
CM_ SG_ 325 ESP_ebdFaultLamp "Electronic stability control: ebd fault lamp";
CM_ SG_ 325 ESP_absFaultLamp "ESP request to display ABS Fault Lamp.";
CM_ SG_ 325 ESP_espFaultLamp "ESP request to display ESP Fault lamp in instrument cluster.";
CM_ SG_ 325 ESP_hydraulicBoostEnabled "Electronic stability control: hydraulic boost enabled";
CM_ SG_ 325 ESP_espLampFlash "Electronic stability control: esp lamp flash";
CM_ SG_ 325 ESP_brakeLamp "Electronic stability control: brake lamp";
CM_ SG_ 325 ESP_absBrakeEvent2 "Indicates if ABS is active and on which axle.";
CM_ SG_ 325 ESP_longitudinalAccelQF "Longitudinal accel sensor quialifier from ESP";
CM_ SG_ 325 ESP_lateralAccelQF "Lateral accel sensor quialifier from ESP";
CM_ SG_ 325 ESP_yawRateQF "Electronic stability control: yaw rate QF";
CM_ SG_ 325 ESP_steeringAngleQF "Electronic stability control: steering angle QF";
CM_ SG_ 325 ESP_brakeDiscWipingActive "Indicates when brake disc wiping is active.";
CM_ SG_ 325 ESP_driverBrakeApply "Indicates when the driver applies the brake pedal.";
CM_ SG_ 325 ESP_brakeApply "Electronic stability control: brake apply";
CM_ SG_ 325 ESP_aesPrimaryActuatorStatus "Electronic stability control: aes primary actuator status";
CM_ SG_ 325 ESP_cdpStatus "Indicates the state of the ESP to perform pressure builds through ESP for dynamic apply";
CM_ SG_ 325 ESP_ptcTargetState "Electronic stability control: ptc target state";
CM_ SG_ 325 ESP_btcTargetState "Electronic stability control: btc target state";
CM_ SG_ 325 ESP_decoupledBrakePressEst "Reports the master cylinder pressure estimated by the Electronic Stability Program (ESP) which includes four wheel ESP active pressure builds";
CM_ SG_ 325 ESP_ebrStandstillSkid "Electronic stability control: ebr standstill skid";
CM_ SG_ 325 ESP_ebrStatus "Electronic stability control: ebr status";
CM_ SG_ 325 ESP_brakeTorqueTarget "Electronic stability control: brake torque target";
CM_ BO_ 1662 "EVSE ECU message: iso tp to veh";
CM_ SG_ 1662 EVSE_isoTpToVehData "EVSE ECU: iso tp to veh data";
CM_ BO_ 1322 "FC ECU message: alert log";
CM_ SG_ 1322 FC_alertID "FC ECU: alert ID";
CM_ SG_ 1322 FC_alertType "FC ECU: alert type";
CM_ SG_ 1322 FC_a130_CA_flybackSwOvType "FC ECU: a130 CA flyback sw ov type";
CM_ SG_ 1322 FC_a146_CA_flybackOnTime "FC ECU: a146 CA flyback on time";
CM_ SG_ 1322 FC_a146_CA_flybackV "FC ECU: a146 CA flyback v";
CM_ SG_ 1322 FC_a146_CA_flybackTargetV "FC ECU: a146 CA flyback target v";
CM_ SG_ 1322 FC_a159_CA_wdtTaskList1 "FC ECU: a159 CA wdt task list1";
CM_ SG_ 1322 FC_a159_CA_wdtTaskList2 "FC ECU: a159 CA wdt task list2";
CM_ BO_ 895 "FC ECU message: alert matrix3";
CM_ SG_ 895 FC_a129_CA_flyback_HW_OC "FC ECU: a129 CA flyback HW OC";
CM_ SG_ 895 FC_a130_CA_flyback_SW_OV "FC ECU: a130 CA flyback SW OV";
CM_ SG_ 895 FC_a131_CA_flyback_HW_OV "FC ECU: a131 CA flyback HW OV";
CM_ SG_ 895 FC_a132_CA_bmsMia "FC ECU: a132 CA bms mia";
CM_ SG_ 895 FC_a133_CA_evseMia "FC ECU: a133 CA evse mia";
CM_ SG_ 895 FC_a134_CA_vehTxBufOvf "FC ECU: a134 CA veh tx buf ovf";
CM_ SG_ 895 FC_a135_CA_vehRxBufOvf "FC ECU: a135 CA veh rx buf ovf";
CM_ SG_ 895 FC_a136_CA_evseTxBufOvf "FC ECU: a136 CA evse tx buf ovf";
CM_ SG_ 895 FC_a137_CA_evseRxBufOvf "FC ECU: a137 CA evse rx buf ovf";
CM_ SG_ 895 FC_a138_CA_hwProxTrip "FC ECU: a138 CA hw prox trip";
CM_ SG_ 895 FC_a139_CA_ss2NotLow "FC ECU: a139 CA ss2 not low";
CM_ SG_ 895 FC_a140_CA_bmsIncompatible "FC ECU: a140 CA bms incompatible";
CM_ SG_ 895 FC_a141_CA_vehConn_OT "FC ECU: a141 CA veh conn OT";
CM_ SG_ 895 FC_a142_CA_evseConn_OT "FC ECU: a142 CA evse conn OT";
CM_ SG_ 895 FC_a143_CA_pcb_OT "FC ECU: a143 CA pcb OT";
CM_ SG_ 895 FC_a144_CA_flybackUnstable "FC ECU: a144 CA flyback unstable";
CM_ SG_ 895 FC_a145_CA_flybackDataStale "FC ECU: a145 CA flyback data stale";
CM_ SG_ 895 FC_a146_CA_flybackBusLoadHi "FC ECU: a146 CA flyback bus load hi";
CM_ SG_ 895 FC_a147_CA_vehConn_UT "FC ECU: a147 CA veh conn UT";
CM_ SG_ 895 FC_a148_CA_evseConn_UT "FC ECU: a148 CA evse conn UT";
CM_ SG_ 895 FC_a149_CA_pcb_UT "FC ECU: a149 CA pcb UT";
CM_ SG_ 895 FC_a150_CA_vehToEvseDeltaHi "FC ECU: a150 CA veh to evse delta hi";
CM_ SG_ 895 FC_a151_CA_vehToEvseDeltaLo "FC ECU: a151 CA veh to evse delta lo";
CM_ SG_ 895 FC_a152_CA_vehToPcbDeltaHi "FC ECU: a152 CA veh to pcb delta hi";
CM_ SG_ 895 FC_a153_CA_evseToPcbDeltaHi "FC ECU: a153 CA evse to pcb delta hi";
CM_ SG_ 895 FC_a154_CA_vehToPcbDeltaLo "FC ECU: a154 CA veh to pcb delta lo";
CM_ SG_ 895 FC_a155_CA_evseToPcbDeltaLo "FC ECU: a155 CA evse to pcb delta lo";
CM_ SG_ 895 FC_a156_CA_flybackRunTimeout "FC ECU: a156 CA flyback run timeout";
CM_ SG_ 895 FC_a157_CA_unused "FC ECU: a157 CA unused";
CM_ SG_ 895 FC_a158_CA_evseOverCurrent "FC ECU: a158 CA evse over current";
CM_ SG_ 895 FC_a159_CA_wdtExpired "FC ECU: a159 CA wdt expired";
CM_ SG_ 895 FC_a160_CA_ss2Deasserted "FC ECU: a160 CA ss2 deasserted";
CM_ SG_ 895 FC_a161_CA_vehTempHiFoldBk "FC ECU: a161 CA veh temp hi fold bk";
CM_ SG_ 895 FC_a162_CA_evseTempHiFoldBk "FC ECU: a162 CA evse temp hi fold bk";
CM_ SG_ 895 FC_a163_CA_pcbTempHiFoldBk "FC ECU: a163 CA pcb temp hi fold bk";
CM_ SG_ 895 FC_a164_CA_proxDisconnected "FC ECU: a164 CA prox disconnected";
CM_ SG_ 895 FC_a165_CA_evseConnUnlocked "FC ECU: a165 CA evse conn unlocked";
CM_ SG_ 895 FC_a166_CA_vehConnUnlocked "FC ECU: a166 CA veh conn unlocked";
CM_ SG_ 895 FC_a167_CA_isoVoltageLow "FC ECU: a167 CA iso voltage low";
CM_ SG_ 895 FC_a168_CA_proxTimeout "FC ECU: a168 CA prox timeout";
CM_ SG_ 895 FC_a169_CA_pilotAcceptTimeout "FC ECU: a169 CA pilot accept timeout";
CM_ SG_ 895 FC_a170_CA_vehDataTimeout "FC ECU: a170 CA veh data timeout";
CM_ SG_ 895 FC_a171_CA_vehConLockTimeout "FC ECU: a171 CA veh con lock timeout";
CM_ SG_ 895 FC_a172_CA_ss2LowTimeout "FC ECU: a172 CA ss2 low timeout";
CM_ SG_ 895 FC_a173_CA_evseDataTimeout "FC ECU: a173 CA evse data timeout";
CM_ SG_ 895 FC_a174_CA_vehReadyTimeout "FC ECU: a174 CA veh ready timeout";
CM_ SG_ 895 FC_a175_CA_evseIsoTestTimeout "FC ECU: a175 CA evse iso test timeout";
CM_ SG_ 895 FC_a176_CA_chargingBusTimeout "FC ECU: a176 CA charging bus timeout";
CM_ SG_ 895 FC_a177_CA_bmsCtrCloseTimeout "FC ECU: a177 CA bms ctr close timeout";
CM_ SG_ 895 FC_a178_CA_evseStartTimeout "FC ECU: a178 CA evse start timeout";
CM_ SG_ 895 FC_a179_CA_startupProblem "FC ECU: a179 CA startup problem";
CM_ SG_ 895 FC_a180_CA_chargingProblem "FC ECU: a180 CA charging problem";
CM_ SG_ 895 FC_a181_CA_vRegBrownout "FC ECU: a181 CA v reg brownout";
CM_ SG_ 895 FC_a182_CA_evseChrMalfunc "FC ECU: a182 CA evse chr malfunc";
CM_ SG_ 895 FC_a183_CA_evseBatIncompat "FC ECU: a183 CA evse bat incompat";
CM_ SG_ 895 FC_a184_CA_evseBatMalfunc "FC ECU: a184 CA evse bat malfunc";
CM_ SG_ 895 FC_a185_CA_vehReadyDeasserted "FC ECU: a185 CA veh ready deasserted";
CM_ SG_ 895 FC_a186_CA_fcContOpenTimeout "FC ECU: a186 CA fc cont open timeout";
CM_ SG_ 895 FC_a187_CA_evseConLockTimeout "FC ECU: a187 CA evse con lock timeout";
CM_ BO_ 927 "FC ECU message: alert matrix4";
CM_ SG_ 927 FC_a193_FCAlertPlaceholder "FC ECU: a193 FC alert placeholder";
CM_ BO_ 958 "FC ECU message: alert matrix5";
CM_ SG_ 958 FC_a257_GB_bmsMia "FC ECU: a257 GB bms mia";
CM_ SG_ 958 FC_a258_GB_evseMia "FC ECU: a258 GB evse mia";
CM_ SG_ 958 FC_a259_GB_vehTxBufOvf "FC ECU: a259 GB veh tx buf ovf";
CM_ SG_ 958 FC_a260_GB_vehRxBufOvf "FC ECU: a260 GB veh rx buf ovf";
CM_ SG_ 958 FC_a261_GB_evseTxBufOvf "FC ECU: a261 GB evse tx buf ovf";
CM_ SG_ 958 FC_a262_GB_evseRxBufOvf "FC ECU: a262 GB evse rx buf ovf";
CM_ SG_ 958 FC_a263_GB_hwProxTrip "FC ECU: a263 GB hw prox trip";
CM_ SG_ 958 FC_a264_GB_timeoutCHM "FC ECU: a264 GB timeout CHM";
CM_ SG_ 958 FC_a265_GB_bmsIncompatible "FC ECU: a265 GB bms incompatible";
CM_ SG_ 958 FC_a266_GB_negPin_OT "FC ECU: a266 GB neg pin OT";
CM_ SG_ 958 FC_a267_GB_posPin_OT "FC ECU: a267 GB pos pin OT";
CM_ SG_ 958 FC_a268_GB_pcb_OT "FC ECU: a268 GB pcb OT";
CM_ SG_ 958 FC_a269_GB_timeoutCRM "FC ECU: a269 GB timeout CRM";
CM_ SG_ 958 FC_a270_GB_timeoutCML "FC ECU: a270 GB timeout CML";
CM_ SG_ 958 FC_a271_GB_timeoutCRO "FC ECU: a271 GB timeout CRO";
CM_ SG_ 958 FC_a272_GB_negToPosDeltaHi "FC ECU: a272 GB neg to pos delta hi";
CM_ SG_ 958 FC_a273_GB_negToPosDeltaLo "FC ECU: a273 GB neg to pos delta lo";
CM_ SG_ 958 FC_a274_GB_negToPcbDeltaHi "FC ECU: a274 GB neg to pcb delta hi";
CM_ SG_ 958 FC_a275_GB_posToPcbDeltaHi "FC ECU: a275 GB pos to pcb delta hi";
CM_ SG_ 958 FC_a276_GB_negToPcbDeltaLo "FC ECU: a276 GB neg to pcb delta lo";
CM_ SG_ 958 FC_a277_GB_posToPcbDeltaLo "FC ECU: a277 GB pos to pcb delta lo";
CM_ SG_ 958 FC_a278_GB_timeoutCCS "FC ECU: a278 GB timeout CCS";
CM_ SG_ 958 FC_a279_GB_evseOverCurrent "FC ECU: a279 GB evse over current";
CM_ SG_ 958 FC_a280_GB_retryLimitExceeded "FC ECU: a280 GB retry limit exceeded";
CM_ SG_ 958 FC_a281_GB_evseOutOfService "FC ECU: a281 GB evse out of service";
CM_ SG_ 958 FC_a282_GB_negTempHiFoldBk "FC ECU: a282 GB neg temp hi fold bk";
CM_ SG_ 958 FC_a283_GB_posTempHiFoldBk "FC ECU: a283 GB pos temp hi fold bk";
CM_ SG_ 958 FC_a284_GB_pcbTempHiFoldBk "FC ECU: a284 GB pcb temp hi fold bk";
CM_ SG_ 958 FC_a285_GB_proxDisconnected "FC ECU: a285 GB prox disconnected";
CM_ SG_ 958 FC_a286_GB_evseConnUnlocked "FC ECU: a286 GB evse conn unlocked";
CM_ SG_ 958 FC_a287_GB_vehConnUnlocked "FC ECU: a287 GB veh conn unlocked";
CM_ SG_ 958 FC_a288_GB_evseAbnormalStopReq "FC ECU: a288 GB evse abnormal stop req";
CM_ SG_ 958 FC_a289_GB_proxTimeout "FC ECU: a289 GB prox timeout";
CM_ SG_ 958 FC_a290_GB_pilotAcceptTimeout "FC ECU: a290 GB pilot accept timeout";
CM_ SG_ 958 FC_a291_GB_vehDataTimeout "FC ECU: a291 GB veh data timeout";
CM_ SG_ 958 FC_a292_GB_vehConLockTimeout "FC ECU: a292 GB veh con lock timeout";
CM_ SG_ 958 FC_a293_GB_proxRationality "FC ECU: a293 GB prox rationality";
CM_ SG_ 958 FC_a294_GB_unused "FC ECU: a294 GB unused";
CM_ SG_ 958 FC_a295_GB_pilotRationality "FC ECU: a295 GB pilot rationality";
CM_ SG_ 958 FC_a296_GB_invalidPilotTransitio "FC ECU: a296 GB invalid pilot transitio";
CM_ SG_ 958 FC_a297_GB_unused "FC ECU: a297 GB unused";
CM_ SG_ 958 FC_a298_GB_bmsCtrCloseTimeout "FC ECU: a298 GB bms ctr close timeout";
CM_ SG_ 958 FC_a299_GB_evseReadyTimeout "FC ECU: a299 GB evse ready timeout";
CM_ SG_ 958 FC_a300_GB_unused "FC ECU: a300 GB unused";
CM_ SG_ 958 FC_a301_GB_unused "FC ECU: a301 GB unused";
CM_ SG_ 958 FC_a302_GB_unused "FC ECU: a302 GB unused";
CM_ SG_ 958 FC_a303_GB_negRecogTimeout "FC ECU: a303 GB neg recog timeout";
CM_ SG_ 958 FC_a304_GB_unused "FC ECU: a304 GB unused";
CM_ SG_ 958 FC_a305_GB_posRecogTimeout "FC ECU: a305 GB pos recog timeout";
CM_ SG_ 958 FC_a306_GB_vehReadyDeasserted "FC ECU: a306 GB veh ready deasserted";
CM_ SG_ 958 FC_a307_GB_fcContOpenTimeout "FC ECU: a307 GB fc cont open timeout";
CM_ SG_ 958 FC_a308_GB_evseConLockTimeout "FC ECU: a308 GB evse con lock timeout";
CM_ SG_ 958 FC_a309_GB_unused "FC ECU: a309 GB unused";
CM_ SG_ 958 FC_a310_GB_unused "FC ECU: a310 GB unused";
CM_ SG_ 958 FC_a311_GB_battParamsTimeout "FC ECU: a311 GB batt params timeout";
CM_ SG_ 958 FC_a312_GB_evseLimitsTimeout "FC ECU: a312 GB evse limits timeout";
CM_ SG_ 958 FC_a313_GB_inputVoltageRailOv "FC ECU: a313 GB input voltage rail ov";
CM_ BO_ 990 "FC ECU message: alert matrix6";
CM_ SG_ 990 FC_a321_FCAlertPlaceholder "FC ECU: a321 FC alert placeholder";
CM_ BO_ 1117 "FC ECU message: evse billing";
CM_ SG_ 1117 FC_evseBillingDataSelect "FC ECU: evse billing data select";
CM_ SG_ 1117 FC_evseBillingEnergy "FC ECU: evse billing energy";
CM_ SG_ 1117 FC_evseMeterPower "FC ECU: evse meter power";
CM_ SG_ 1117 FC_evseMeterCurrent "FC ECU: evse meter current";
CM_ SG_ 1117 FC_evseMeterVoltage "FC ECU: evse meter voltage";
CM_ SG_ 1117 FC_evseMeterFwGitHash "FC ECU: evse meter fw git hash";
CM_ BO_ 1334 "FC ECU message: evse billing2";
CM_ SG_ 1334 FC_evseBilling2DataSelect "FC ECU: evse billing2 data select";
CM_ SG_ 1334 FC_evsePpuEnabled "FC ECU: evse ppu enabled";
CM_ SG_ 1334 FC_evseBillingEnergyHighRes "FC ECU: evse billing energy high res";
CM_ BO_ 1303 "FC ECU message: identifier";
CM_ SG_ 1303 FC_id "Fast charger identifying number";
CM_ SG_ 1303 FC_sessionId "Fast charge session ID";
CM_ BO_ 1310 "FC ECU message: info";
CM_ SG_ 1310 FC_infoIndex "FC ECU: info index";
CM_ SG_ 1310 FC_infoBuildType "FC ECU: info build type";
CM_ SG_ 1310 FC_infoBuildConfigID "FC ECU: info build config ID";
CM_ SG_ 1310 FC_infoHardwareID "FC ECU: info hardware ID";
CM_ SG_ 1310 FC_infoComponentID "FC ECU: info component ID";
CM_ SG_ 1310 FC_infoPcbaID "FC ECU: info pcba ID";
CM_ SG_ 1310 FC_infoAssemblyID "FC ECU: info assembly ID";
CM_ SG_ 1310 FC_infoUsageID "FC ECU: info usage ID";
CM_ SG_ 1310 FC_infoSubUsageID "FC ECU: info sub usage ID";
CM_ SG_ 1310 FC_infoApplicationCRC "FC ECU: info application CRC";
CM_ SG_ 1310 FC_infoAppGitHashBytes "FC ECU: info app git hash bytes";
CM_ SG_ 1310 FC_infoBootGitHashBytes "FC ECU: info boot git hash bytes";
CM_ SG_ 1310 FC_infoPlatformType "FC ECU: info platform type";
CM_ SG_ 1310 FC_infoMajorVersion "Fast charger firmware major version number";
CM_ SG_ 1310 FC_infoBranchOrigin "Fast charger branch origin";
CM_ SG_ 1310 FC_infoMaturity "Fast charger firmware info";
CM_ SG_ 1310 FC_infoHardwareRevision "FC ECU: info hardware revision";
CM_ SG_ 1310 FC_partNumChar01 "FC ECU: part num char01";
CM_ SG_ 1310 FC_partNumChar02 "FC ECU: part num char02";
CM_ SG_ 1310 FC_partNumChar03 "FC ECU: part num char03";
CM_ SG_ 1310 FC_partNumChar04 "FC ECU: part num char04";
CM_ SG_ 1310 FC_partNumChar05 "FC ECU: part num char05";
CM_ SG_ 1310 FC_partNumChar06 "FC ECU: part num char06";
CM_ SG_ 1310 FC_partNumChar07 "FC ECU: part num char07";
CM_ SG_ 1310 FC_partNumChar08 "FC ECU: part num char08";
CM_ SG_ 1310 FC_partNumChar09 "FC ECU: part num char09";
CM_ SG_ 1310 FC_partNumChar10 "FC ECU: part num char10";
CM_ SG_ 1310 FC_partNumChar11 "FC ECU: part num char11";
CM_ SG_ 1310 FC_partNumChar12 "FC ECU: part num char12";
CM_ SG_ 1310 FC_partNumChar13 "FC ECU: part num char13";
CM_ SG_ 1310 FC_partNumChar14 "FC ECU: part num char14";
CM_ SG_ 1310 FC_partNumChar15 "FC ECU: part num char15";
CM_ SG_ 1310 FC_partNumChar16 "FC ECU: part num char16";
CM_ SG_ 1310 FC_partNumChar17 "FC ECU: part num char17";
CM_ SG_ 1310 FC_partNumChar18 "FC ECU: part num char18";
CM_ SG_ 1310 FC_partNumChar19 "FC ECU: part num char19";
CM_ SG_ 1310 FC_partNumChar20 "FC ECU: part num char20";
CM_ BO_ 580 "FC ECU message: limits";
CM_ SG_ 580 FC_powerLimit "Instantaneous power charger can deliver.";
CM_ SG_ 580 FC_currentLimit "Instantaneous current charger can deliver.";
CM_ SG_ 580 FC_maxVoltageLimit "Max voltage charger can deliver. 600/65536";
CM_ SG_ 580 FC_minVoltageLimit "Measures Electric Vehicle Supply Equipment (EVSE) minimum current limit.";
CM_ BO_ 702 "FC ECU message: limits high power";
CM_ SG_ 702 FC_powerLimit_value "Instantaneous power charger can deliver. Mantissa portion of extended range version of legacy signal, used with protocol versions 9+. FC_powerLimit = value * 10^exp";
CM_ SG_ 702 FC_currentLimit_value "FC ECU: current limit value";
CM_ SG_ 702 FC_minVoltageLimit_value "FC ECU: min voltage limit value";
CM_ SG_ 702 FC_powerLimit_exp "Instantaneous power charger can deliver. Exponent portion of extended ragne version of legacy signal, used with protocol versions 9+. FC_powerLimit = value * 10^exp.";
CM_ SG_ 702 FC_currentLimit_exp "FC ECU: current limit exp";
CM_ SG_ 702 FC_minVoltageLimit_exp "FC ECU: min voltage limit exp";
CM_ BO_ 1345 "FC ECU message: max limits";
CM_ SG_ 1345 FC_maxPowerLimit "Max power charger can deliver.";
CM_ SG_ 1345 FC_maxCurrentLimit "Max current charger can deliver.";
CM_ BO_ 1300 "FC ECU message: serial";
CM_ SG_ 1300 FC_serialDataSelect "FC ECU: serial data select";
CM_ SG_ 1300 FC_serialChar01 "FC ECU: serial char01";
CM_ SG_ 1300 FC_serialChar02 "FC ECU: serial char02";
CM_ SG_ 1300 FC_serialChar03 "FC ECU: serial char03";
CM_ SG_ 1300 FC_serialChar04 "FC ECU: serial char04";
CM_ SG_ 1300 FC_serialChar05 "FC ECU: serial char05";
CM_ SG_ 1300 FC_serialChar06 "FC ECU: serial char06";
CM_ SG_ 1300 FC_serialChar07 "FC ECU: serial char07";
CM_ SG_ 1300 FC_serialChar08 "FC ECU: serial char08";
CM_ SG_ 1300 FC_serialChar09 "FC ECU: serial char09";
CM_ SG_ 1300 FC_serialChar10 "FC ECU: serial char10";
CM_ SG_ 1300 FC_serialChar11 "FC ECU: serial char11";
CM_ SG_ 1300 FC_serialChar12 "FC ECU: serial char12";
CM_ SG_ 1300 FC_serialChar13 "FC ECU: serial char13";
CM_ SG_ 1300 FC_serialChar14 "FC ECU: serial char14";
CM_ SG_ 1300 FC_serialChar15 "FC ECU: serial char15";
CM_ SG_ 1300 FC_serialChar16 "FC ECU: serial char16";
CM_ SG_ 1300 FC_serialChar17 "FC ECU: serial char17";
CM_ BO_ 532 "FC ECU message: status";
CM_ SG_ 532 FC_protocolVersion "FC ECU: protocol version";
CM_ SG_ 532 FC_statusCode "Fast charger status code";
CM_ SG_ 532 FC_deprecated1 "FC ECU: deprecated1";
CM_ SG_ 532 FC_deprecated2 "FC ECU: deprecated2";
CM_ SG_ 532 FC_deprecated3 "FC ECU: deprecated3";
CM_ SG_ 532 FC_adapterLocked "Indicates if the DC adapter is secure or not";
CM_ SG_ 532 FC_minCurrentLimit "Fast charger min current limit";
CM_ SG_ 532 FC_type "Type of EVSE connected that supports digital communication";
CM_ SG_ 532 FC_dcCurrent "Fast charger DC output current";
CM_ SG_ 532 FC_postID "Fast charger charging post ID";
CM_ SG_ 532 FC_dcVoltage "Fast charger DC voltage";
CM_ SG_ 532 FC_leakageTestNotSupported "Indicates if the S/X leakage test can be run on this supercharger";
CM_ SG_ 532 FC_dischargeSupported "FC ECU: discharge supported";
CM_ BO_ 533 "FC ECU message: status2";
CM_ SG_ 533 FC_externalIsolationResistance "Fast charger external isolation resistance";
CM_ BO_ 535 "FC ECU message: status3";
CM_ SG_ 535 FC_status3DataSelect "FC ECU: status3 data select";
CM_ SG_ 535 FC_status3DummySig "FC ECU: status3 dummy sig";
CM_ SG_ 535 FC_class "FC ECU: class";
CM_ SG_ 535 FC_brand "Fast charger brand";
CM_ SG_ 535 FC_coolingType "Type of cooling used for the supercharger";
CM_ SG_ 535 FC_uiStopType "Type of stop type supported from the UI";
CM_ SG_ 535 FC_emergencyShutdownSupported "Indicates if the supercharger supports fast emergency shutdown requests from vehicle";
CM_ SG_ 535 FC_generation "Hardware generation of the Tesla EVSE.";
CM_ BO_ 888 "Gateway message: e call";
CM_ SG_ 888 GTW_GTW_SOS_ECALL_RQST "State of the GTW-SOS-ECALL-RQST pin";
CM_ SG_ 888 GTW_LTE_ECALL_LOCK "State of the LTE-ECALL-LOCK pin";
CM_ BO_ 282 "Gateway message: adc4";
CM_ SG_ 282 GTW_BKP_BATT_MON "Gateway: BKP BATT MON";
CM_ SG_ 282 GTW_BKP_BATT_NTC_P "BKP_BATT_NTC_P pni voltage";
CM_ SG_ 282 GTW_ECALL_GPS_ANT_BIAS "Gateway: ECALL GPS ANT BIAS";
CM_ SG_ 282 GTW_ECALL_MIC_DIAG "ECALL_MIC_DIAG voltage";
CM_ SG_ 282 GTW_SOS_ECALL_nRQST_BUF "SOS_ECALL_nRQST_BUF voltage";
CM_ BO_ 1384 "Gateway message: alert log";
CM_ SG_ 1384 GTW_alertID "Gateway: alert ID";
CM_ SG_ 1384 GTW_alertState "Gateway: alert state";
CM_ SG_ 1384 GTW_a014_crcVersion "Gateway: a014 crc version";
CM_ SG_ 1384 GTW_a015_crcVersion "Gateway: a015 crc version";
CM_ SG_ 1384 GTW_a016_crcVersion "Gateway: a016 crc version";
CM_ SG_ 1384 GTW_a017_crcVersion "Gateway: a017 crc version";
CM_ SG_ 1384 GTW_a018_crcVersion "Gateway: a018 crc version";
CM_ SG_ 1384 GTW_a019_crcVersion "Gateway: a019 crc version";
CM_ SG_ 1384 GTW_a020_crcVersion "Gateway: a020 crc version";
CM_ SG_ 1384 GTW_a021_crcVersion "Gateway: a021 crc version";
CM_ SG_ 1384 GTW_a022_crcVersion "Gateway: a022 crc version";
CM_ SG_ 1384 GTW_a023_crcVersion "Gateway: a023 crc version";
CM_ SG_ 1384 GTW_a024_crcVersion "Gateway: a024 crc version";
CM_ SG_ 1384 GTW_a025_crcVersion "Gateway: a025 crc version";
CM_ SG_ 1384 GTW_a026_crcVersion "Gateway: a026 crc version";
CM_ SG_ 1384 GTW_a027_crcVersion "Gateway: a027 crc version";
CM_ SG_ 1384 GTW_a028_crcVersion "Gateway: a028 crc version";
CM_ SG_ 1384 GTW_a029_crcVersion "Gateway: a029 crc version";
CM_ SG_ 1384 GTW_a030_crcVersion "Gateway: a030 crc version";
CM_ SG_ 1384 GTW_a031_crcVersion "Gateway: a031 crc version";
CM_ SG_ 1384 GTW_a032_crcVersion "Gateway: a032 crc version";
CM_ SG_ 1384 GTW_a033_crcVersion "Gateway: a033 crc version";
CM_ SG_ 1384 GTW_a034_crcVersion "Gateway: a034 crc version";
CM_ SG_ 1384 GTW_a035_crcVersion "Gateway: a035 crc version";
CM_ SG_ 1384 GTW_a036_crcVersion "Gateway: a036 crc version";
CM_ SG_ 1384 GTW_a037_crcVersion "Gateway: a037 crc version";
CM_ SG_ 1384 GTW_a038_crcVersion "Gateway: a038 crc version";
CM_ SG_ 1384 GTW_a039_crcVersion "Gateway: a039 crc version";
CM_ SG_ 1384 GTW_a040_crcVersion "Gateway: a040 crc version";
CM_ SG_ 1384 GTW_a041_crcVersion "Gateway: a041 crc version";
CM_ SG_ 1384 GTW_a042_crcVersion "Gateway: a042 crc version";
CM_ SG_ 1384 GTW_a043_crcVersion "Gateway: a043 crc version";
CM_ SG_ 1384 GTW_a045_crcVersion "Gateway: a045 crc version";
CM_ SG_ 1384 GTW_a046_crcVersion "Gateway: a046 crc version";
CM_ SG_ 1384 GTW_a047_crcVersion "Gateway: a047 crc version";
CM_ SG_ 1384 GTW_a048_crcVersion "Gateway: a048 crc version";
CM_ SG_ 1384 GTW_a049_headerError "Gateway: a049 header error";
CM_ SG_ 1384 GTW_a054_crcVersion "Gateway: a054 crc version";
CM_ SG_ 1384 GTW_a055_crcVersion "Gateway: a055 crc version";
CM_ SG_ 1384 GTW_a062_bmpWatchdogReason "Gateway: a062 bmp watchdog reason";
CM_ SG_ 1384 GTW_a063_VEH_faultConfinement "Gateway: a063 VEH fault confinement";
CM_ SG_ 1384 GTW_a064_CH_faultConfinement "Gateway: a064 CH fault confinement";
CM_ SG_ 1384 GTW_a065_PARTY_faultConfinement "Gateway: a065 PARTY fault confinement";
CM_ SG_ 1384 GTW_a066_type "Gateway: a066 type";
CM_ SG_ 1384 GTW_a066_exceptionCfgId "Gateway: a066 exception cfg id";
CM_ SG_ 1384 GTW_a066_uptime "Gateway: a066 uptime";
CM_ SG_ 1384 GTW_a066_core "Gateway: a066 core";
CM_ SG_ 1384 GTW_a068_codeKeyMissing "Gateway: a068 code key missing";
CM_ SG_ 1384 GTW_a068_cmdKeyMissing "Gateway: a068 cmd key missing";
CM_ SG_ 1384 GTW_a069_sdIntStatusErrs "Gateway: a069 sd int status errs";
CM_ SG_ 1384 GTW_a069_sdTimeout "Gateway: a069 sd timeout";
CM_ SG_ 1384 GTW_a069_sdCmdErr "Gateway: a069 sd cmd err";
CM_ SG_ 1384 GTW_a069_sdWriteErr "Gateway: a069 sd write err";
CM_ SG_ 1384 GTW_a069_sdReadErr "Gateway: a069 sd read err";
CM_ SG_ 1384 GTW_a069_autoCmd12Err "Gateway: a069 auto cmd12 err";
CM_ SG_ 1384 GTW_a072_updtFailureMask "Gateway: a072 updt failure mask";
CM_ SG_ 1384 GTW_a073_SOCResetRequestor "Gateway: a073 SOC reset requestor";
CM_ SG_ 1384 GTW_a077_bmpPmicErrorType "Gateway: a077 bmp pmic error type";
CM_ SG_ 1384 GTW_a097_crcVersion "Gateway: a097 crc version";
CM_ SG_ 1384 GTW_a098_crcVersion "Gateway: a098 crc version";
CM_ SG_ 1384 GTW_a099_crcVersion "Gateway: a099 crc version";
CM_ SG_ 1384 GTW_a100_crcVersion "Gateway: a100 crc version";
CM_ SG_ 1384 GTW_a101_switchStuck "Gateway: a101 switch stuck";
CM_ SG_ 1384 GTW_a101_ETH_SW_nINT "Gateway: a101 ETH SW n INT";
CM_ SG_ 1384 GTW_a106_crcVersion "Gateway: a106 crc version";
CM_ SG_ 1384 GTW_a107_crcVersion "Gateway: a107 crc version";
CM_ SG_ 1384 GTW_a108_crcVersion "Gateway: a108 crc version";
CM_ SG_ 1384 GTW_a117_MC_RGM_DES "Gateway: a117 MC RGM DES";
CM_ SG_ 1384 GTW_a118_MC_RGM_FES "Gateway: a118 MC RGM FES";
CM_ SG_ 1384 GTW_a122_BDY_faultConfinement "Gateway: a122 BDY fault confinement";
CM_ SG_ 1384 GTW_a129_crcVersion "Gateway: a129 crc version";
CM_ SG_ 1384 GTW_a138_sdLifetimeUsed "Gateway: a138 sd lifetime used";
CM_ SG_ 1384 GTW_a139_crcVersion "Gateway: a139 crc version";
CM_ SG_ 1384 GTW_a150_crcVersion "Gateway: a150 crc version";
CM_ SG_ 1384 GTW_a151_crcVersion "Gateway: a151 crc version";
CM_ SG_ 1384 GTW_a155_crcVersion "Gateway: a155 crc version";
CM_ SG_ 1384 GTW_a164_crcVersion "Gateway: a164 crc version";
CM_ SG_ 1384 GTW_a165_crcVersion "Gateway: a165 crc version";
CM_ SG_ 1384 GTW_a169_TPMS_pressureFL "Gateway: a169 TPMS pressure FL";
CM_ SG_ 1384 GTW_a170_TPMS_pressureFR "Gateway: a170 TPMS pressure FR";
CM_ SG_ 1384 GTW_a171_TPMS_pressureRL "Gateway: a171 TPMS pressure RL";
CM_ SG_ 1384 GTW_a172_TPMS_pressureRR "Gateway: a172 TPMS pressure RR";
CM_ SG_ 1384 GTW_a173_TPMS_pressureFL "Gateway: a173 TPMS pressure FL";
CM_ SG_ 1384 GTW_a174_TPMS_pressureFR "Gateway: a174 TPMS pressure FR";
CM_ SG_ 1384 GTW_a175_TPMS_pressureRL "Gateway: a175 TPMS pressure RL";
CM_ SG_ 1384 GTW_a176_TPMS_pressureRR "Gateway: a176 TPMS pressure RR";
CM_ SG_ 1384 GTW_a219_crcVersion "Gateway: a219 crc version";
CM_ SG_ 1384 GTW_a223_crcVersion "Gateway: a223 crc version";
CM_ SG_ 1384 GTW_a226_crcVersion "Gateway: a226 crc version";
CM_ SG_ 1384 GTW_a227_crcVersion "Gateway: a227 crc version";
CM_ SG_ 1384 GTW_a228_crcVersion "Gateway: a228 crc version";
CM_ SG_ 1384 GTW_a244_crcVersion "Gateway: a244 crc version";
CM_ SG_ 1384 GTW_a245_page0ControlValue "Gateway: a245 page0 control value";
CM_ SG_ 1384 GTW_a245_page1ControlValue "Gateway: a245 page1 control value";
CM_ SG_ 1384 GTW_a261_failureReason "Gateway: a261 failure reason";
CM_ SG_ 1384 GTW_a261_failureData1 "Gateway: a261 failure data1";
CM_ SG_ 1384 GTW_a261_failureData2 "Gateway: a261 failure data2";
CM_ SG_ 1384 GTW_a273_crcVersion "Gateway: a273 crc version";
CM_ SG_ 1384 GTW_a274_crcVersion "Gateway: a274 crc version";
CM_ SG_ 1384 GTW_a277_mitigationFailureReason "Gateway: a277 mitigation failure reason";
CM_ SG_ 1384 GTW_a279_repeatCount "Gateway: a279 repeat count";
CM_ SG_ 1384 GTW_a279_failureReason "Gateway: a279 failure reason";
CM_ SG_ 1384 GTW_a279_failureData1 "Gateway: a279 failure data1";
CM_ SG_ 1384 GTW_a279_failureData2 "Gateway: a279 failure data2";
CM_ SG_ 1384 GTW_a309_crcVersion "Gateway: a309 crc version";
CM_ SG_ 1384 GTW_a317_status "Gateway: a317 status";
CM_ SG_ 1384 GTW_a317_errorCode "Gateway: a317 error code";
CM_ SG_ 1384 GTW_a329_crcVersion "Gateway: a329 crc version";
CM_ SG_ 1384 GTW_a330_crcVersion "Gateway: a330 crc version";
CM_ SG_ 1384 GTW_a331_crcVersion "Gateway: a331 crc version";
CM_ SG_ 1384 GTW_a342_crcVersion "Gateway: a342 crc version";
CM_ SG_ 1384 GTW_a348_crcVersion "Gateway: a348 crc version";
CM_ SG_ 1384 GTW_a349_crcVersion "Gateway: a349 crc version";
CM_ SG_ 1384 GTW_a354_crcVersion "Gateway: a354 crc version";
CM_ SG_ 1384 GTW_a355_crcVersion "Gateway: a355 crc version";
CM_ SG_ 1384 GTW_a358_crcVersion "Gateway: a358 crc version";
CM_ SG_ 1384 GTW_a359_crcVersion "Gateway: a359 crc version";
CM_ SG_ 1384 GTW_a360_crcVersion "Gateway: a360 crc version";
CM_ SG_ 1384 GTW_a361_crcVersion "Gateway: a361 crc version";
CM_ SG_ 1384 GTW_a362_crcVersion "Gateway: a362 crc version";
CM_ SG_ 1384 GTW_a363_crcVersion "Gateway: a363 crc version";
CM_ SG_ 1384 GTW_a364_crcVersion "Gateway: a364 crc version";
CM_ SG_ 1384 GTW_a380_crcVersion "Gateway: a380 crc version";
CM_ SG_ 1384 GTW_a381_crcVersion "Gateway: a381 crc version";
CM_ SG_ 1384 GTW_a382_crcVersion "Gateway: a382 crc version";
CM_ SG_ 1384 GTW_a383_crcVersion "Gateway: a383 crc version";
CM_ SG_ 1384 GTW_a384_crcVersion "Gateway: a384 crc version";
CM_ SG_ 1384 GTW_a385_crcVersion "Gateway: a385 crc version";
CM_ SG_ 1384 GTW_a386_crcVersion "Gateway: a386 crc version";
CM_ SG_ 1384 GTW_a394_crcVersion "Gateway: a394 crc version";
CM_ SG_ 1384 GTW_a401_crcVersion "Gateway: a401 crc version";
CM_ SG_ 1384 GTW_a402_crcVersion "Gateway: a402 crc version";
CM_ SG_ 1384 GTW_a409_RES_CAUSE "Gateway: a409 RES CAUSE";
CM_ SG_ 1384 GTW_a410_RES_CAUSE2 "Gateway: a410 RES CAUSE2";
CM_ SG_ 1384 GTW_a418_crcVersion "Gateway: a418 crc version";
CM_ SG_ 1384 GTW_a427_crcVersion "Gateway: a427 crc version";
CM_ SG_ 1384 GTW_a428_crcVersion "Gateway: a428 crc version";
CM_ SG_ 1384 GTW_a429_crcVersion "Gateway: a429 crc version";
CM_ SG_ 1384 GTW_a439_crcVersion "Gateway: a439 crc version";
CM_ BO_ 62 "Gateway message: alert matrix";
CM_ SG_ 62 GTW_matrixIndex "Gateway: matrix index";
CM_ SG_ 62 GTW_w001_canEthTxQueue "Gateway: w001 can eth tx queue";
CM_ SG_ 62 GTW_w002_taskError "Gateway: w002 task error";
CM_ SG_ 62 GTW_w003_logWriteRecord "Gateway: w003 log write record";
CM_ SG_ 62 GTW_w004_mallocHook "Gateway: w004 malloc hook";
CM_ SG_ 62 GTW_w005_stackOverflowHook "Gateway: w005 stack overflow hook";
CM_ SG_ 62 GTW_w006_ifTxOutputFull "Gateway: w006 if tx output full";
CM_ SG_ 62 GTW_w007_ifRxBufError "Gateway: w007 if rx buf error";
CM_ SG_ 62 GTW_w008_ifPbufAllocError "Gateway: w008 if pbuf alloc error";
CM_ SG_ 62 GTW_w009_lateTask "Gateway: w009 late task";
CM_ SG_ 62 GTW_w010_wdTaskCount "Gateway: w010 wd task count";
CM_ SG_ 62 GTW_w011_cancoreWatchdog "Gateway: w011 cancore watchdog";
CM_ SG_ 62 GTW_w012_maincoreWatchdog "Gateway: w012 maincore watchdog";
CM_ SG_ 62 GTW_w014_APSversionMismatch "Gateway: w014 AP sversion mismatch";
CM_ SG_ 62 GTW_w015_DIFversionMismatch "Gateway: w015 DI fversion mismatch";
CM_ SG_ 62 GTW_w016_BLEEPCENTERversionMisma "Gateway: w016 BLEEPCENTE rversion mismatch";
CM_ SG_ 62 GTW_w017_BMSversionMismatch "Gateway: w017 BM sversion mismatch";
CM_ SG_ 62 GTW_w018_CMPversionMismatch "Gateway: w018 CM pversion mismatch";
CM_ SG_ 62 GTW_w019_CPversionMismatch "Gateway: w019 c pversion mismatch";
CM_ SG_ 62 GTW_w020_DIRversionMismatch "Gateway: w020 DI rversion mismatch";
CM_ SG_ 62 GTW_w021_EPAS3PversionMismatch "Gateway: w021 EPAS3 pversion mismatch";
CM_ SG_ 62 GTW_w022_EPBLversionMismatch "Gateway: w022 EPB lversion mismatch";
CM_ SG_ 62 GTW_w023_EPBRversionMismatch "Gateway: w023 EPB rversion mismatch";
CM_ SG_ 62 GTW_w024_ESPversionMismatch "Gateway: w024 ES pversion mismatch";
CM_ SG_ 62 GTW_w025_ESPCALversionMismatch "Gateway: w025 ESPCA lversion mismatch";
CM_ SG_ 62 GTW_w026_GTWversionMismatch "Gateway: w026 GT wversion mismatch";
CM_ SG_ 62 GTW_w027_HVPversionMismatch "Gateway: w027 HV pversion mismatch";
CM_ SG_ 62 GTW_w028_IBSTversionMismatch "Gateway: w028 IBS tversion mismatch";
CM_ SG_ 62 GTW_w029_IBSTCALversionMismatch "Gateway: w029 IBSTCA lversion mismatch";
CM_ SG_ 62 GTW_w030_OCS1PversionMismatch "Gateway: w030 OCS1 pversion mismatch";
CM_ SG_ 62 GTW_w031_PARKversionMismatch "Gateway: w031 PAR kversion mismatch";
CM_ SG_ 62 GTW_w032_PCSversionMismatch "Gateway: w032 PC sversion mismatch";
CM_ SG_ 62 GTW_w033_PCSCPU2versionMismatch "Gateway: w033 pcscpu2version mismatch";
CM_ SG_ 62 GTW_w034_PMRversionMismatch "Gateway: w034 PM rversion mismatch";
CM_ SG_ 62 GTW_w035_PMFversionMismatch "Gateway: w035 PM fversion mismatch";
CM_ SG_ 62 GTW_w036_PTCversionMismatch "Gateway: w036 PT cversion mismatch";
CM_ SG_ 62 GTW_w037_RADCversionMismatch "Gateway: w037 RAD cversion mismatch";
CM_ SG_ 62 GTW_w038_RCMversionMismatch "Gateway: w038 RC mversion mismatch";
CM_ SG_ 62 GTW_w039_RCMCALversionMismatch "Gateway: w039 RCMCA lversion mismatch";
CM_ SG_ 62 GTW_w040_SCCMversionMismatch "Gateway: w040 SCC mversion mismatch";
CM_ SG_ 62 GTW_w041_VCSECversionMismatch "Gateway: w041 VCSE cversion mismatch";
CM_ SG_ 62 GTW_w042_TASversionMismatch "Gateway: w042 TA sversion mismatch";
CM_ SG_ 62 GTW_w043_THSversionMismatch "Gateway: w043 TH sversion mismatch";
CM_ SG_ 62 GTW_w045_VCFRONTversionMismatch "Gateway: w045 VCFRON tversion mismatch";
CM_ SG_ 62 GTW_w046_VCLEFTversionMismatch "Gateway: w046 VCLEF tversion mismatch";
CM_ SG_ 62 GTW_w047_VCRIGHTversionMismatch "Gateway: w047 VCRIGH tversion mismatch";
CM_ SG_ 62 GTW_w048_EPAS3SversionMismatch "Gateway: w048 EPAS3 sversion mismatch";
CM_ SG_ 62 GTW_w049_corruptedManifest "Gateway: w049 corrupted manifest";
CM_ SG_ 62 GTW_w050_sdCardInitFailure "Gateway: w050 sd card init failure";
CM_ SG_ 62 GTW_w051_sdCardFileSystemFailure "Gateway: w051 sd card file system failure";
CM_ SG_ 62 GTW_w052_ifTxSpans "Gateway: w052 if tx spans";
CM_ SG_ 62 GTW_w053_busSleepFailure "Gateway: w053 bus sleep failure";
CM_ SG_ 62 GTW_w054_OPCRversionMismatch "Gateway: w054 OPC rversion mismatch";
CM_ SG_ 62 GTW_w055_OPCFversionMismatch "Gateway: w055 OPC fversion mismatch";
CM_ SG_ 62 GTW_w057_i2cFailure "Gateway: w057 i2c failure";
CM_ SG_ 62 GTW_w058_rtcAlarmFailure "Gateway: w058 rtc alarm failure";
CM_ SG_ 62 GTW_w059_inFactoryMode "Gateway: w059 in factory mode";
CM_ SG_ 62 GTW_w060_unFused "Gateway: w060 un fused";
CM_ SG_ 62 GTW_w061_bmpSleepFailure "Gateway: w061 bmp sleep failure";
CM_ SG_ 62 GTW_w062_bmpWatchdog "Gateway: w062 bmp watchdog";
CM_ SG_ 62 GTW_w063_VEH_canFault "Gateway: w063 VEH can fault";
CM_ SG_ 62 GTW_w064_CH_canFault "Gateway: w064 CH can fault";
CM_ SG_ 62 GTW_w065_PARTY_canFault "Gateway: w065 PARTY can fault";
CM_ SG_ 62 GTW_w066_exception "Gateway: w066 exception";
CM_ SG_ 62 GTW_w067_tcpDebug "Gateway: w067 tcp debug";
CM_ SG_ 62 GTW_w068_prodKeyMissing "Gateway: w068 prod key missing";
CM_ SG_ 62 GTW_w069_diskioErr "Gateway: w069 diskio err";
CM_ SG_ 62 GTW_w070_hrlDump "Gateway: w070 hrl dump";
CM_ SG_ 62 GTW_w071_hrlTrigger "Gateway: w071 hrl trigger";
CM_ SG_ 62 GTW_w072_updateFailure "Gateway: w072 update failure";
CM_ SG_ 62 GTW_w073_steeringWheelReset "Gateway: w073 steering wheel reset";
CM_ SG_ 62 GTW_w074_epas3pMIA "Gateway: w074 epas3p MIA";
CM_ SG_ 62 GTW_w075_epas3sMIA "Gateway: w075 epas3s MIA";
CM_ SG_ 62 GTW_w076_ethInterfaceReset "Gateway: w076 eth interface reset";
CM_ SG_ 62 GTW_w077_bmpPmicError "Gateway: w077 bmp pmic error";
CM_ SG_ 62 GTW_w078_VEHbusOverloaded "Gateway: w078 VE hbus overloaded";
CM_ SG_ 62 GTW_w079_PARTYbusOverloaded "Gateway: w079 PART ybus overloaded";
CM_ SG_ 62 GTW_w080_CHbusOverloaded "Gateway: w080 c hbus overloaded";
CM_ SG_ 62 GTW_w081_udsMessageRejected "Gateway: w081 uds message rejected";
CM_ SG_ 62 GTW_w082_sdCardBSCorrupted "Gateway: w082 sd card BS corrupted";
CM_ SG_ 62 GTW_w083_udsMsgDroppedByTcpStack "Gateway: w083 uds msg dropped by tcp stack";
CM_ SG_ 62 GTW_w084_canFrameDropped "Gateway: w084 can frame dropped";
CM_ SG_ 62 GTW_w085_fuseStateUnknown "Gateway: w085 fuse state unknown";
CM_ SG_ 62 GTW_w086_ocu "Gateway: w086 ocu";
CM_ SG_ 62 GTW_w087_ocuInProgress "Gateway: w087 ocu in progress";
CM_ SG_ 62 GTW_w088_sdCardInvReqParallel "Gateway: w088 sd card inv req parallel";
CM_ SG_ 62 GTW_w089_sdCardWatchdog "Gateway: w089 sd card watchdog";
CM_ SG_ 62 GTW_w090_ocuFailed "Gateway: w090 ocu failed";
CM_ SG_ 62 GTW_w091_lowStack "Gateway: w091 low stack";
CM_ SG_ 62 GTW_w092_sdCardInvReqZero "Gateway: w092 sd card inv req zero";
CM_ SG_ 62 GTW_w093_sdCardInvReqOverflowBas "Gateway: w093 sd card inv req overflow base";
CM_ SG_ 62 GTW_w094_sdCardInvReqOverflowCou "Gateway: w094 sd card inv req overflow count";
CM_ SG_ 62 GTW_w095_sdCardFull "Gateway: w095 sd card full";
CM_ SG_ 62 GTW_w096_sdCardFatCorrupted "Gateway: w096 sd card fat corrupted";
CM_ SG_ 62 GTW_w097_HCMLversionMismatch "Gateway: w097 HCM lversion mismatch";
CM_ SG_ 62 GTW_w098_HCMRversionMismatch "Gateway: w098 HCM rversion mismatch";
CM_ SG_ 62 GTW_w099_SWCversionMismatch "Gateway: w099 SW cversion mismatch";
CM_ SG_ 62 GTW_w100_CBCversionMismatch "Gateway: w100 CB cversion mismatch";
CM_ SG_ 62 GTW_w101_switchWatchdog "Gateway: w101 switch watchdog";
CM_ SG_ 62 GTW_w103_sdCardFormatted "Gateway: w103 sd card formatted";
CM_ SG_ 62 GTW_w104_sdCardDriverArgCorrupte "Gateway: w104 sd card driver arg corrupted";
CM_ SG_ 62 GTW_w105_eBuckConfigured "Gateway: w105 e buck configured";
CM_ SG_ 62 GTW_w106_BLEEPLEFTversionMismatc "Gateway: w106 BLEEPLEF tversion mismatch";
CM_ SG_ 62 GTW_w107_BLEEPRIGHTversionMismat "Gateway: w107 BLEEPRIGH tversion mismatch";
CM_ SG_ 62 GTW_w108_BLEEPREARversionMismatc "Gateway: w108 BLEEPREA rversion mismatch";
CM_ SG_ 62 GTW_w109_failedToStartUpdater "Gateway: w109 failed to start updater";
CM_ SG_ 62 GTW_w110_readMdioFailed "Gateway: w110 read mdio failed";
CM_ SG_ 62 GTW_w111_writeMdioFailed "Gateway: w111 write mdio failed";
CM_ SG_ 62 GTW_w112_z4bDisabled "Gateway: w112 z4b disabled";
CM_ SG_ 62 GTW_w113_unrecognizedCanMessage "Gateway: w113 unrecognized can message";
CM_ SG_ 62 GTW_w114_updtRetried "Gateway: w114 updt retried";
CM_ SG_ 62 GTW_w115_hrlEventFileAvail "Gateway: w115 hrl event file avail";
CM_ SG_ 62 GTW_w116_switchInitFailed "Gateway: w116 switch init failed";
CM_ SG_ 62 GTW_w117_unexpectedDestructiveRe "Gateway: w117 unexpected destructive reset status";
CM_ SG_ 62 GTW_w118_unexpectedFunctionalRes "Gateway: w118 unexpected functional reset status";
CM_ SG_ 62 GTW_w120_switchUnlocked "Gateway: w120 switch unlocked";
CM_ SG_ 62 GTW_w122_BDY_canFault "Gateway: w122 BDY can fault";
CM_ SG_ 62 GTW_w123_BDYbusOverloaded "Gateway: w123 BD ybus overloaded";
CM_ SG_ 62 GTW_w125_switchReplayUnlocked "Gateway: w125 switch replay unlocked";
CM_ SG_ 62 GTW_w127_noFilePointersAvailable "Gateway: w127 no file pointers available";
CM_ SG_ 62 GTW_w129_ICRversionMismatch "Gateway: w129 IC rversion mismatch";
CM_ SG_ 62 GTW_w133_adspFaultDetected "Gateway: w133 adsp fault detected";
CM_ SG_ 62 GTW_w134_disableFeatureFailed "Gateway: w134 disable feature failed";
CM_ SG_ 62 GTW_w135_canLogQueueFull "Gateway: w135 can log queue full";
CM_ SG_ 62 GTW_w136_hrlGameModeFileAvail "Gateway: w136 hrl game mode file avail";
CM_ SG_ 62 GTW_w137_lowHeap "Gateway: w137 low heap";
CM_ SG_ 62 GTW_w138_sdCardEndOfLife "Gateway: w138 sd card end of life";
CM_ SG_ 62 GTW_w139_CMPDversionMismatch "Gateway: w139 CMP dversion mismatch";
CM_ SG_ 62 GTW_w140_cancoreHeartbeat "Gateway: w140 cancore heartbeat";
CM_ SG_ 62 GTW_w141_teleCANETHis "Gateway: w141 tele CANET his";
CM_ SG_ 62 GTW_w143_possibleCanWakeIssue "Gateway: w143 possible can wake issue";
CM_ SG_ 62 GTW_w144_hrlStateMachine "Gateway: w144 hrl state machine";
CM_ SG_ 62 GTW_w145_carConfigsNotWritten "Gateway: w145 car configs not written";
CM_ SG_ 62 GTW_w146_performancePackageMisma "Gateway: w146 performance package mismatch";
CM_ SG_ 62 GTW_w147_updateAbortFor12v "Gateway: w147 update abort for12v";
CM_ SG_ 62 GTW_w149_rtcTimeSetInPast "Gateway: w149 rtc time set in past";
CM_ SG_ 62 GTW_w150_HCM3LversionMismatch "Gateway: w150 HCM3 lversion mismatch";
CM_ SG_ 62 GTW_w151_HCM3RversionMismatch "Gateway: w151 HCM3 rversion mismatch";
CM_ SG_ 62 GTW_w153_externalRtcAlarmFailure "Gateway: w153 external rtc alarm failure";
CM_ SG_ 62 GTW_w155_PMversionMismatch "Gateway: w155 p mversion mismatch";
CM_ SG_ 62 GTW_w164_VCBATTversionMismatch "Gateway: w164 VCBAT tversion mismatch";
CM_ SG_ 62 GTW_w165_USMversionMismatch "Gateway: w165 US mversion mismatch";
CM_ SG_ 62 GTW_w166_nErrCanFaultVeh "Gateway: w166 n err can fault veh";
CM_ SG_ 62 GTW_w167_nErrCanFaultCh "Gateway: w167 n err can fault ch";
CM_ SG_ 62 GTW_w168_nErrCanFaultParty "Gateway: w168 n err can fault party";
CM_ SG_ 62 GTW_w169_TPMSsoftWarnFrontLeft "Gateway: w169 TPM ssoft warn front left";
CM_ SG_ 62 GTW_w170_TPMSsoftWarnFrontRight "Gateway: w170 TPM ssoft warn front right";
CM_ SG_ 62 GTW_w171_TPMSsoftWarnRearLeft "Gateway: w171 TPM ssoft warn rear left";
CM_ SG_ 62 GTW_w172_TPMSsoftWarnRearRight "Gateway: w172 TPM ssoft warn rear right";
CM_ SG_ 62 GTW_w173_TPMShardWarnFrontLeft "Gateway: w173 TPM shard warn front left";
CM_ SG_ 62 GTW_w174_TPMShardWarnFrontRight "Gateway: w174 TPM shard warn front right";
CM_ SG_ 62 GTW_w175_TPMShardWarnRearLeft "Gateway: w175 TPM shard warn rear left";
CM_ SG_ 62 GTW_w176_TPMShardWarnRearRight "Gateway: w176 TPM shard warn rear right";
CM_ SG_ 62 GTW_w186_swrPrecaution "Gateway: w186 swr precaution";
CM_ SG_ 62 GTW_w218_switchOTPIncorrect "Gateway: w218 switch OTP incorrect";
CM_ SG_ 62 GTW_w219_CMPSversionMismatch "Gateway: w219 CMP sversion mismatch";
CM_ SG_ 62 GTW_w223_LVBMSversionMismatch "Gateway: w223 LVBM sversion mismatch";
CM_ SG_ 62 GTW_w224_sdCardUpgradeNeeded "Gateway: w224 sd card upgrade needed";
CM_ SG_ 62 GTW_w225_resetOnSleepWake "Gateway: w225 reset on sleep wake";
CM_ SG_ 62 GTW_w226_DISPversionMismatch "Gateway: w226 DIS pversion mismatch";
CM_ SG_ 62 GTW_w227_DISPTOUCHversionMismatc "Gateway: w227 DISPTOUC hversion mismatch";
CM_ SG_ 62 GTW_w228_DISPOSDversionMismatch "Gateway: w228 DISPOS dversion mismatch";
CM_ SG_ 62 GTW_w229_displaySoftsetConnectio "Gateway: w229 display softset connection";
CM_ SG_ 62 GTW_w230_touchInterruptStorm "Gateway: w230 touch interrupt storm";
CM_ SG_ 62 GTW_w244_SDCRversionMismatch "Gateway: w244 SDC rversion mismatch";
CM_ SG_ 62 GTW_w245_apsNotDisabled "Gateway: w245 aps not disabled";
CM_ SG_ 62 GTW_w246_touchcoreHeartbeat "Gateway: w246 touchcore heartbeat";
CM_ SG_ 62 GTW_w255_rtc32KHzWatchdog "Gateway: w255 rtc32 k hz watchdog";
CM_ SG_ 62 GTW_w260_unknownPN "Gateway: w260 unknown PN";
CM_ SG_ 62 GTW_w261_adspWatchdog "Gateway: w261 adsp watchdog";
CM_ SG_ 62 GTW_w262_canLogBlockDropped "Gateway: w262 can log block dropped";
CM_ SG_ 62 GTW_w263_hrlUdpFileAvail "Gateway: w263 hrl udp file avail";
CM_ SG_ 62 GTW_w264_hrlPseudoFileAvail "Gateway: w264 hrl pseudo file avail";
CM_ SG_ 62 GTW_w265_optionFlagsError "Gateway: w265 option flags error";
CM_ SG_ 62 GTW_w266_dpp1MIA "Gateway: w266 dpp1 MIA";
CM_ SG_ 62 GTW_w267_dpp2MIA "Gateway: w267 dpp2 MIA";
CM_ SG_ 62 GTW_w268_stoMIA "Gateway: w268 sto MIA";
CM_ SG_ 62 GTW_w273_BLEEPREARLEFTversionMis "Gateway: w273 BLEEPREARLEF tversion mismatch";
CM_ SG_ 62 GTW_w274_BLEEPREARRIGHTversionMi "Gateway: w274 BLEEPREARRIGH tversion mismatch";
CM_ SG_ 62 GTW_w275_VDDCORE_DrMOS_Fault "Gateway: w275 VDDCORE dr MOS fault";
CM_ SG_ 62 GTW_w276_VDDSOC_DrMOS_Fault "Gateway: w276 VDDSOC dr MOS fault";
CM_ SG_ 62 GTW_w277_NonRevCDrMOSMitigationF "Gateway: w277 non rev c dr MOS mitigation failed";
CM_ SG_ 62 GTW_w278_ethSwitchCongested "Gateway: w278 eth switch congested";
CM_ SG_ 62 GTW_w279_adspRepeatedWatchdog "Gateway: w279 adsp repeated watchdog";
CM_ SG_ 62 GTW_w280_hrlFrameDropped "Gateway: w280 hrl frame dropped";
CM_ SG_ 62 GTW_w281_likelyMissedPoke "Gateway: w281 likely missed poke";
CM_ SG_ 62 GTW_w282_tcuPhyConfigurationFail "Gateway: w282 tcu phy configuration failed";
CM_ SG_ 62 GTW_w309_VCUSBversionMismatch "Gateway: w309 VCUS bversion mismatch";
CM_ SG_ 62 GTW_w311_canLogQueueFullBeforeFs "Gateway: w311 can log queue full before fs init";
CM_ SG_ 62 GTW_w312_hrlFileIncomplete "Gateway: w312 hrl file incomplete";
CM_ SG_ 62 GTW_w313_OSDActive "Gateway: w313 OSD active";
CM_ SG_ 62 GTW_w314_canLogBlockWriteErr "Gateway: w314 can log block write err";
CM_ SG_ 62 GTW_w316_sdCardChkdskRepair "Gateway: w316 sd card chkdsk repair";
CM_ SG_ 62 GTW_w317_sdCardChkdskRepairFaile "Gateway: w317 sd card chkdsk repair failed";
CM_ SG_ 62 GTW_w322_gestureUnrecognizedFrom "Gateway: w322 gesture unrecognized from moving";
CM_ SG_ 62 GTW_w323_gestureStartOutOfStrip "Gateway: w323 gesture start out of strip";
CM_ SG_ 62 GTW_w328_smartShiftDisabled "Gateway: w328 smart shift disabled";
CM_ SG_ 62 GTW_w329_FOHMversionMismatch "Gateway: w329 FOH mversion mismatch";
CM_ SG_ 62 GTW_w330_SWSLversionMismatch "Gateway: w330 SWS lversion mismatch";
CM_ SG_ 62 GTW_w331_SWSRversionMismatch "Gateway: w331 SWS rversion mismatch";
CM_ SG_ 62 GTW_w332_unknownDisplayPN "Gateway: w332 unknown display PN";
CM_ SG_ 62 GTW_w334_hrlFolderSpaceLow "Gateway: w334 hrl folder space low";
CM_ SG_ 62 GTW_w336_possibleCanTxIssue "Gateway: w336 possible can tx issue";
CM_ SG_ 62 GTW_w342_VCBLDCPPversionMismatch "Gateway: w342 VCBLDCP pversion mismatch";
CM_ SG_ 62 GTW_w348_VCBLDCFversionMismatch "Gateway: w348 VCBLDC fversion mismatch";
CM_ SG_ 62 GTW_w349_VCBLDCPBversionMismatch "Gateway: w349 VCBLDCP bversion mismatch";
CM_ SG_ 62 GTW_w350_mOSDCrcCheck "Gateway: w350 m OSD crc check";
CM_ SG_ 62 GTW_w351_sOSDCrcCheck "Gateway: w351 s OSD crc check";
CM_ SG_ 62 GTW_w352_mASILStatusCheck "Gateway: w352 m ASIL status check";
CM_ SG_ 62 GTW_w353_sASILStatusCheck "Gateway: w353 s ASIL status check";
CM_ SG_ 62 GTW_w354_EPASTPversionMismatch "Gateway: w354 EPAST pversion mismatch";
CM_ SG_ 62 GTW_w355_EPASTSversionMismatch "Gateway: w355 EPAST sversion mismatch";
CM_ SG_ 62 GTW_w356_touchGPIOStatusCheck "Gateway: w356 touch GPIO status check";
CM_ SG_ 62 GTW_w358_RGBIPFLversionMismatch "Gateway: w358 RGBIPF lversion mismatch";
CM_ SG_ 62 GTW_w359_RGBIPFRversionMismatch "Gateway: w359 RGBIPF rversion mismatch";
CM_ SG_ 62 GTW_w360_RGBDOORFLversionMismatc "Gateway: w360 RGBDOORF lversion mismatch";
CM_ SG_ 62 GTW_w361_RGBDOORRLversionMismatc "Gateway: w361 RGBDOORR lversion mismatch";
CM_ SG_ 62 GTW_w362_RGBDOORFRversionMismatc "Gateway: w362 RGBDOORF rversion mismatch";
CM_ SG_ 62 GTW_w363_RGBDOORRRversionMismatc "Gateway: w363 RGBDOORR rversion mismatch";
CM_ SG_ 62 GTW_w364_BLEEPCRADLEversionMisma "Gateway: w364 BLEEPCRADL eversion mismatch";
CM_ SG_ 62 GTW_w366_uiGearRequestMismatch "Gateway: w366 ui gear request mismatch";
CM_ SG_ 62 GTW_w376_blFailedToExecBootImg "Gateway: w376 bl failed to exec boot img";
CM_ SG_ 62 GTW_w380_DPBversionMismatch "Gateway: w380 DP bversion mismatch";
CM_ SG_ 62 GTW_w381_DPBCALversionMismatch "Gateway: w381 DPBCA lversion mismatch";
CM_ SG_ 62 GTW_w382_IDBversionMismatch "Gateway: w382 ID bversion mismatch";
CM_ SG_ 62 GTW_w383_IDB1versionMismatch "Gateway: w383 idb1version mismatch";
CM_ SG_ 62 GTW_w384_IDBCALversionMismatch "Gateway: w384 IDBCA lversion mismatch";
CM_ SG_ 62 GTW_w385_RCUversionMismatch "Gateway: w385 RC uversion mismatch";
CM_ SG_ 62 GTW_w386_RCUCALversionMismatch "Gateway: w386 RCUCA lversion mismatch";
CM_ SG_ 62 GTW_w387_externalRtcReadFailure "Gateway: w387 external rtc read failure";
CM_ SG_ 62 GTW_w388_adspWatchdogSkipped "Gateway: w388 adsp watchdog skipped";
CM_ SG_ 62 GTW_w389_rcmEventDetected "Gateway: w389 rcm event detected";
CM_ SG_ 62 GTW_w390_displayFwQueryFailed "Gateway: w390 display fw query failed";
CM_ SG_ 62 GTW_w391_adspMacAddrCheckFailed "Gateway: w391 adsp mac addr check failed";
CM_ SG_ 62 GTW_w393_osdSramCrcMismatch "Gateway: w393 osd sram crc mismatch";
CM_ SG_ 62 GTW_w394_WIPERversionMismatch "Gateway: w394 WIPE rversion mismatch";
CM_ SG_ 62 GTW_w395_lwipIcmpError "Gateway: w395 lwip icmp error";
CM_ SG_ 62 GTW_w396_alreadyInReverse "Gateway: w396 already in reverse";
CM_ SG_ 62 GTW_w397_alreadyInDrive "Gateway: w397 already in drive";
CM_ SG_ 62 GTW_w398_awakeForExtendedTime "Gateway: w398 awake for extended time";
CM_ SG_ 62 GTW_w399_ethIfRxTcpipQueueDrop "Gateway: w399 eth if rx tcpip queue drop";
CM_ SG_ 62 GTW_w400_ethlSwitchOTPIncorrect "Gateway: w400 ethl switch OTP incorrect";
CM_ SG_ 62 GTW_w401_VCSEAT2LversionMismatch "Gateway: w401 VCSEAT2 lversion mismatch";
CM_ SG_ 62 GTW_w402_VCSEAT2RversionMismatch "Gateway: w402 VCSEAT2 rversion mismatch";
CM_ SG_ 62 GTW_w409_unexpectedResetCause "Gateway: w409 unexpected reset cause";
CM_ SG_ 62 GTW_w410_unexpectedResetCause2 "Gateway: w410 unexpected reset cause2";
CM_ SG_ 62 GTW_w411_tASILStatusCheck "Gateway: w411 t ASIL status check";
CM_ SG_ 62 GTW_w414_socHeldInReset "Gateway: w414 soc held in reset";
CM_ SG_ 62 GTW_w418_TRCMversionMismatch "Gateway: w418 TRC mversion mismatch";
CM_ SG_ 62 GTW_w420_unexpectedCanMessageLen "Gateway: w420 unexpected can message length";
CM_ SG_ 62 GTW_w421_ModemEthLinkDown "Gateway: w421 modem eth link down";
CM_ SG_ 62 GTW_w422_ethSwitchSevereCongesti "Gateway: w422 eth switch severe congestion watchdog";
CM_ SG_ 62 GTW_w427_DISPBRIDGEversionMismat "Gateway: w427 DISPBRIDG eversion mismatch";
CM_ SG_ 62 GTW_w428_LUMBAR32LversionMismatc "Gateway: w428 LUMBAR32 lversion mismatch";
CM_ SG_ 62 GTW_w429_LUMBAR32RversionMismatc "Gateway: w429 LUMBAR32 rversion mismatch";
CM_ SG_ 62 GTW_w436_possibleCanRxIssue "Gateway: w436 possible can rx issue";
CM_ SG_ 62 GTW_w437_softFlowControlNotRunni "Gateway: w437 soft flow control not running";
CM_ SG_ 62 GTW_w438_wakeSourceUnknown "Gateway: w438 wake source unknown";
CM_ SG_ 62 GTW_w439_VCCCversionMismatch "Gateway: w439 VCC cversion mismatch";
CM_ SG_ 62 GTW_w450_unexpectedAutopilotCont "Gateway: w450 unexpected autopilot control can message";
CM_ SG_ 62 GTW_w451_diagCanBufferExhausted "Gateway: w451 diag can buffer exhausted";
CM_ SG_ 62 GTW_w452_diagCanStaleSocket "Gateway: w452 diag can stale socket";
CM_ SG_ 62 GTW_w453_diagCanFdSetDesync "Gateway: w453 diag can fd set desync";
CM_ SG_ 62 GTW_w454_diagCanFrameOverread "Gateway: w454 diag can frame overread";
CM_ SG_ 62 GTW_w455_hrlDumpPageOwnershipErr "Gateway: w455 hrl dump page ownership error";
CM_ SG_ 62 GTW_w456_hrlStateMachinePageOwne "Gateway: w456 hrl state machine page ownership error";
CM_ SG_ 62 GTW_w463_displayEdidReadFailed "Gateway: w463 display edid read failed";
CM_ SG_ 62 GTW_w469_backlightFsmUnhealthy "Gateway: w469 backlight fsm unhealthy";
CM_ BO_ 838 "Gateway message: autopilot override";
CM_ SG_ 838 GTW_autopilotOverrideState "Signals whether an autopilot trial or subscription is active";
CM_ SG_ 838 GTW_autopilotConfig "Current level of permanent Autopilot firmware";
CM_ SG_ 838 GTW_autopilotOverrideConfig "Current level of trial or subscription Autopilot firmware";
CM_ SG_ 838 GTW_autopilotConfigSource "Source of Autopilot configuration broadcast by Gateway";
CM_ SG_ 838 GTW_autopilotOverrideExpireTime "Expiration time for the currently active autopilot trial or subscription";
CM_ BO_ 904 "Gateway message: can status";
CM_ SG_ 904 GTW_VEH_canBusActivity "Active if any frame detected on the bus";
CM_ SG_ 904 GTW_PARTY_canBusActivity "Active if any frame detected on the bus";
CM_ SG_ 904 GTW_CH_canBusActivity "Active if any frame detected on the bus";
CM_ SG_ 904 GTW_VEH_txWarning "Gateway: VEH tx warning";
CM_ SG_ 904 GTW_PARTY_txWarning "Gateway: PARTY tx warning";
CM_ SG_ 904 GTW_CH_txWarning "Gateway: CH tx warning";
CM_ SG_ 904 GTW_VEH_rxWarning "Gateway: VEH rx warning";
CM_ SG_ 904 GTW_PARTY_rxWarning "Gateway: PARTY rx warning";
CM_ SG_ 904 GTW_CH_rxWarning "Gateway: CH rx warning";
CM_ SG_ 904 GTW_VEH_faultConfinement "Fault confinement as per CAN spec";
CM_ SG_ 904 GTW_PARTY_faultConfinement "Fault confinement as per CAN spec";
CM_ SG_ 904 GTW_CH_faultConfinement "Fault confinement as per CAN spec";
CM_ SG_ 904 GTW_BDY_canBusActivity "Active if any frame detected on the bus";
CM_ SG_ 904 GTW_BDY_txWarning "Gateway: BDY tx warning";
CM_ SG_ 904 GTW_BDY_rxWarning "Gateway: BDY rx warning";
CM_ SG_ 904 GTW_BDY_faultConfinement "Fault confinement as per CAN spec";
BA_DEF_ BO_ "GenMsgCycleTime" INT 0 3600000;
BA_DEF_ BO_ "GenMsgSendType" ENUM "Cyclic","NotUsed","NotUsed","NotUsed","NotUsed","NotUsed","NotUsed","IfActive","NoMsgSendType","NotUsed";
BA_DEF_ BO_ "VFrameFormat" ENUM "StandardCAN","ExtendedCAN","reserved","J1939PG","reserved","reserved","reserved","reserved","reserved","reserved","reserved","reserved","reserved","reserved","StandardCAN_FD","ExtendedCAN_FD";
BA_DEF_ BO_ "CANFD_BRS" ENUM "0","1";
BA_DEF_ SG_ "SystemSignalLongSymbol" STRING;
BA_DEF_ SG_ "Confidence" ENUM "layout-only","plausible","validated";
BA_DEF_DEF_ "GenMsgCycleTime" 0;
BA_DEF_DEF_ "GenMsgSendType" "NoMsgSendType";
BA_DEF_DEF_ "VFrameFormat" "StandardCAN";
BA_DEF_DEF_ "CANFD_BRS" "1";
BA_DEF_DEF_ "SystemSignalLongSymbol" "";
BA_DEF_DEF_ "Confidence" "layout-only";
BA_ "SystemSignalLongSymbol" SG_ 981 ESP_a193_DIchassisControlChecksu "ESP_a193_DIchassisControlChecksum";
BA_ "SystemSignalLongSymbol" SG_ 981 ESP_a269_DIRELTorqueCommandInval "ESP_a269_DIRELTorqueCommandInvalid";
BA_ "SystemSignalLongSymbol" SG_ 981 ESP_a271_DIRELTorqueActualInvali "ESP_a271_DIRELTorqueActualInvalid";
BA_ "SystemSignalLongSymbol" SG_ 981 ESP_a276_DIRERTorqueCommandInval "ESP_a276_DIRERTorqueCommandInvalid";
BA_ "SystemSignalLongSymbol" SG_ 981 ESP_a278_DIRERTorqueActualInvali "ESP_a278_DIRERTorqueActualInvalid";
BA_ "SystemSignalLongSymbol" SG_ 981 ESP_a279_lifetimeManagementOverr "ESP_a279_lifetimeManagementOverrun";
BA_ "SystemSignalLongSymbol" SG_ 981 ESP_a282_trackModeABSRequestInva "ESP_a282_trackModeABSRequestInvalid";
BA_ "SystemSignalLongSymbol" SG_ 981 ESP_a283_secondaryCollisionMitig "ESP_a283_secondaryCollisionMitigationActive";
BA_ "SystemSignalLongSymbol" SG_ 981 ESP_a284_scmRequestInvalidChecks "ESP_a284_scmRequestInvalidChecksum";
BA_ "SystemSignalLongSymbol" SG_ 981 ESP_a287_failedBrakeCircuitDetec "ESP_a287_failedBrakeCircuitDetected";
BA_ "SystemSignalLongSymbol" SG_ 981 ESP_a296_roadWheelAngleHealthDeg "ESP_a296_roadWheelAngleHealthDegraded";
BA_ "SystemSignalLongSymbol" SG_ 981 ESP_a297_roadWheelAngleHealthFau "ESP_a297_roadWheelAngleHealthFaulted";
BA_ "SystemSignalLongSymbol" SG_ 981 ESP_a298_RSArearSteerStatusTimeo "ESP_a298_RSArearSteerStatusTimeout";
BA_ "SystemSignalLongSymbol" SG_ 981 ESP_a300_RSArearSteerStatusCheck "ESP_a300_RSArearSteerStatusChecksum";
BA_ "SystemSignalLongSymbol" SG_ 981 ESP_a302_rearRoadWheelAngleHealt "ESP_a302_rearRoadWheelAngleHealthDegraded";
BA_ "SystemSignalLongSymbol" SG_ 981 ESP_a303_rearRoadWheelAngleHealt "ESP_a303_rearRoadWheelAngleHealthFaulted";
BA_ "SystemSignalLongSymbol" SG_ 981 ESP_a304_rearVCLVPowerStateTimeo "ESP_a304_rearVCLVPowerStateTimeout";
BA_ "SystemSignalLongSymbol" SG_ 981 ESP_a306_rearVCLVPowerStateCheck "ESP_a306_rearVCLVPowerStateChecksum";
BA_ "SystemSignalLongSymbol" SG_ 981 ESP_a307_rearVCLVPowerStateCount "ESP_a307_rearVCLVPowerStateCounter";
BA_ "SystemSignalLongSymbol" SG_ 981 ESP_a310_brakeLatencyReductionAc "ESP_a310_brakeLatencyReductionActive";
BA_ "SystemSignalLongSymbol" SG_ 981 ESP_a319_AES_BackupActuatorActiv "ESP_a319_AES_BackupActuatorActive";
BA_ "SystemSignalLongSymbol" SG_ 981 ESP_a334_BrakePedalAppliedInvali "ESP_a334_BrakePedalAppliedInvalid";
BA_ "SystemSignalLongSymbol" SG_ 981 ESP_a337_pReductionPotentialInva "ESP_a337_pReductionPotentialInvalid";
BA_ "SystemSignalLongSymbol" SG_ 981 ESP_a341_EnhancedPressureBuildAc "ESP_a341_EnhancedPressureBuildActive";
BA_ "SystemSignalLongSymbol" SG_ 981 ESP_a342_EnhancedPressureBuildNo "ESP_a342_EnhancedPressureBuildNotAvailable";
BA_ "SystemSignalLongSymbol" SG_ 981 ESP_a343_EnhancedPressureBuildLt "ESP_a343_EnhancedPressureBuildLtmReached";
BA_ "SystemSignalLongSymbol" SG_ 981 ESP_a351_ActuatorYellowLampReque "ESP_a351_ActuatorYellowLampRequested";
BA_ "SystemSignalLongSymbol" SG_ 981 ESP_a353_PressureSensorImplausHi "ESP_a353_PressureSensorImplausHigh";
BA_ "SystemSignalLongSymbol" SG_ 981 ESP_a358_externalActuatorFallbac "ESP_a358_externalActuatorFallback";
BA_ "SystemSignalLongSymbol" SG_ 981 ESP_a359_externalActuatorNoExtRe "ESP_a359_externalActuatorNoExtReq";
BA_ "SystemSignalLongSymbol" SG_ 981 ESP_a362_BBbrakeActuationChecksu "ESP_a362_BBbrakeActuationChecksum";
BA_ "SystemSignalLongSymbol" SG_ 981 ESP_a366_ActuatorBlendingModeReq "ESP_a366_ActuatorBlendingModeReqNotAvailable";
BA_ "SystemSignalLongSymbol" SG_ 981 ESP_a367_CBDS_fillBufferThreshol "ESP_a367_CBDS_fillBufferThreshold";
BA_ "SystemSignalLongSymbol" SG_ 981 ESP_a369_LargeLeakageDetectedByD "ESP_a369_LargeLeakageDetectedByDPB";
BA_ "SystemSignalLongSymbol" SG_ 981 ESP_a379_DASredundantBrakingCont "ESP_a379_DASredundantBrakingControlPartyChecksum";
BA_ "SystemSignalLongSymbol" SG_ 981 ESP_a380_DASredundantBrakingCont "ESP_a380_DASredundantBrakingControlPartyCounter";
BA_ "SystemSignalLongSymbol" SG_ 981 ESP_a381_DASredundantBrakingCont "ESP_a381_DASredundantBrakingControlPartyDLC";
BA_ "SystemSignalLongSymbol" SG_ 981 ESP_a382_DASredundantBrakingCont "ESP_a382_DASredundantBrakingControlPartyTimeout";
BA_ "SystemSignalLongSymbol" SG_ 981 ESP_a383_DASredundantBrakingCont "ESP_a383_DASredundantBrakingControlChassisChecksum";
BA_ "SystemSignalLongSymbol" SG_ 981 ESP_a384_DASredundantBrakingCont "ESP_a384_DASredundantBrakingControlChassisCounter";
BA_ "SystemSignalLongSymbol" SG_ 981 ESP_a385_DASredundantBrakingCont "ESP_a385_DASredundantBrakingControlChassisDLC";
BA_ "SystemSignalLongSymbol" SG_ 981 ESP_a386_DASredundantBrakingCont "ESP_a386_DASredundantBrakingControlChassisTimeout";
BA_ "SystemSignalLongSymbol" SG_ 981 ESP_a392_driverlessArmingUnavail "ESP_a392_driverlessArmingUnavailable";
BA_ "SystemSignalLongSymbol" SG_ 981 ESP_a406_DIespActuatorTestTimeou "ESP_a406_DIespActuatorTestTimeout";
BA_ "SystemSignalLongSymbol" SG_ 981 ESP_a407_DIespActuatorTestChecks "ESP_a407_DIespActuatorTestChecksum";
BA_ "SystemSignalLongSymbol" SG_ 981 ESP_a409_DIespActuatorTestCounte "ESP_a409_DIespActuatorTestCounter";
BA_ "Confidence" SG_ 808 ESP_infoBuildType 1;
BA_ "Confidence" SG_ 808 ESP_vehFlashMode 1;
BA_ "Confidence" SG_ 808 ESP_infoSubUsageID 1;
BA_ "Confidence" SG_ 808 ESP_infoApplicationCRC 1;
BA_ "Confidence" SG_ 808 ESP_infoVehicleVariant 1;
BA_ "Confidence" SG_ 808 ESP_infoVariantCRC 1;
BA_ "Confidence" SG_ 1236 ESP_absActive 1;
BA_ "Confidence" SG_ 1236 ESP_vehicleStandstill 1;
BA_ "Confidence" SG_ 1236 ESP_vehicleStandstillQF 1;
BA_ "Confidence" SG_ 1236 ESP_pEstMaximum 1;
BA_ "Confidence" SG_ 1236 ESP_privateVehicleSpd 1;
BA_ "Confidence" SG_ 1236 ESP_decoupledBrakePressOffsetCom 1;
BA_ "SystemSignalLongSymbol" SG_ 1236 ESP_decoupledBrakePressOffsetCom "ESP_decoupledBrakePressOffsetComp";
BA_ "Confidence" SG_ 1236 ESP_privateVehicleSpdQF 1;
BA_ "Confidence" SG_ 1236 ESP_brakeMasterCylPress 1;
BA_ "Confidence" SG_ 1236 ESP_brakeMasterCylPressQF 1;
BA_ "Confidence" SG_ 325 ESP_espModeActive 1;
BA_ "Confidence" SG_ 325 ESP_stabilityControlSts2 1;
BA_ "Confidence" SG_ 325 ESP_ebdFaultLamp 1;
BA_ "Confidence" SG_ 325 ESP_absFaultLamp 1;
BA_ "Confidence" SG_ 325 ESP_espFaultLamp 1;
BA_ "Confidence" SG_ 325 ESP_espLampFlash 1;
BA_ "Confidence" SG_ 325 ESP_brakeLamp 1;
BA_ "Confidence" SG_ 325 ESP_absBrakeEvent2 1;
BA_ "Confidence" SG_ 325 ESP_longitudinalAccelQF 1;
BA_ "Confidence" SG_ 325 ESP_lateralAccelQF 1;
BA_ "Confidence" SG_ 325 ESP_yawRateQF 1;
BA_ "Confidence" SG_ 325 ESP_steeringAngleQF 1;
BA_ "Confidence" SG_ 325 ESP_brakeDiscWipingActive 1;
BA_ "Confidence" SG_ 325 ESP_driverBrakeApply 1;
BA_ "Confidence" SG_ 325 ESP_brakeApply 1;
BA_ "Confidence" SG_ 325 ESP_aesPrimaryActuatorStatus 1;
BA_ "Confidence" SG_ 325 ESP_cdpStatus 1;
BA_ "Confidence" SG_ 325 ESP_ptcTargetState 1;
BA_ "Confidence" SG_ 325 ESP_btcTargetState 1;
BA_ "Confidence" SG_ 325 ESP_decoupledBrakePressEst 1;
BA_ "Confidence" SG_ 325 ESP_ebrStandstillSkid 1;
BA_ "Confidence" SG_ 325 ESP_ebrStatus 1;
BA_ "Confidence" SG_ 325 ESP_brakeTorqueTarget 1;
BA_ "Confidence" SG_ 1117 FC_evseBillingEnergy 1;
BA_ "Confidence" SG_ 1117 FC_evseMeterPower 1;
BA_ "Confidence" SG_ 1117 FC_evseMeterCurrent 1;
BA_ "Confidence" SG_ 1117 FC_evseMeterVoltage 1;
BA_ "Confidence" SG_ 1334 FC_evseBillingEnergyHighRes 1;
BA_ "Confidence" SG_ 1303 FC_id 1;
BA_ "Confidence" SG_ 1303 FC_sessionId 1;
BA_ "Confidence" SG_ 1310 FC_infoBuildType 1;
BA_ "Confidence" SG_ 1310 FC_infoMajorVersion 1;
BA_ "Confidence" SG_ 1310 FC_infoBranchOrigin 1;
BA_ "Confidence" SG_ 1310 FC_infoMaturity 1;
BA_ "Confidence" SG_ 580 FC_powerLimit 1;
BA_ "Confidence" SG_ 580 FC_currentLimit 1;
BA_ "Confidence" SG_ 580 FC_maxVoltageLimit 1;
BA_ "Confidence" SG_ 580 FC_minVoltageLimit 1;
BA_ "Confidence" SG_ 702 FC_powerLimit_value 1;
BA_ "Confidence" SG_ 702 FC_currentLimit_value 1;
BA_ "Confidence" SG_ 702 FC_minVoltageLimit_value 1;
BA_ "Confidence" SG_ 702 FC_powerLimit_exp 1;
BA_ "Confidence" SG_ 1345 FC_maxPowerLimit 1;
BA_ "Confidence" SG_ 1345 FC_maxCurrentLimit 1;
BA_ "Confidence" SG_ 532 FC_statusCode 1;
BA_ "Confidence" SG_ 532 FC_adapterLocked 1;
BA_ "Confidence" SG_ 532 FC_minCurrentLimit 1;
BA_ "Confidence" SG_ 532 FC_type 1;
BA_ "Confidence" SG_ 532 FC_dcCurrent 1;
BA_ "Confidence" SG_ 532 FC_postID 1;
BA_ "Confidence" SG_ 532 FC_dcVoltage 1;
BA_ "Confidence" SG_ 532 FC_leakageTestNotSupported 1;
BA_ "Confidence" SG_ 533 FC_externalIsolationResistance 1;
BA_ "Confidence" SG_ 535 FC_class 1;
BA_ "Confidence" SG_ 535 FC_brand 1;
BA_ "Confidence" SG_ 535 FC_coolingType 1;
BA_ "Confidence" SG_ 535 FC_uiStopType 1;
BA_ "Confidence" SG_ 535 FC_emergencyShutdownSupported 1;
BA_ "Confidence" SG_ 535 FC_generation 1;
BA_ "Confidence" SG_ 888 GTW_GTW_SOS_ECALL_RQST 1;
BA_ "Confidence" SG_ 888 GTW_LTE_ECALL_LOCK 1;
BA_ "Confidence" SG_ 282 GTW_BKP_BATT_MON 1;
BA_ "Confidence" SG_ 282 GTW_BKP_BATT_NTC_P 1;
BA_ "Confidence" SG_ 282 GTW_ECALL_GPS_ANT_BIAS 1;
BA_ "Confidence" SG_ 282 GTW_ECALL_MIC_DIAG 1;
BA_ "Confidence" SG_ 282 GTW_SOS_ECALL_nRQST_BUF 1;
BA_ "SystemSignalLongSymbol" SG_ 62 GTW_w016_BLEEPCENTERversionMisma "GTW_w016_BLEEPCENTERversionMismatch";
BA_ "SystemSignalLongSymbol" SG_ 62 GTW_w093_sdCardInvReqOverflowBas "GTW_w093_sdCardInvReqOverflowBase";
BA_ "SystemSignalLongSymbol" SG_ 62 GTW_w094_sdCardInvReqOverflowCou "GTW_w094_sdCardInvReqOverflowCount";
BA_ "SystemSignalLongSymbol" SG_ 62 GTW_w104_sdCardDriverArgCorrupte "GTW_w104_sdCardDriverArgCorrupted";
BA_ "SystemSignalLongSymbol" SG_ 62 GTW_w106_BLEEPLEFTversionMismatc "GTW_w106_BLEEPLEFTversionMismatch";
BA_ "SystemSignalLongSymbol" SG_ 62 GTW_w107_BLEEPRIGHTversionMismat "GTW_w107_BLEEPRIGHTversionMismatch";
BA_ "SystemSignalLongSymbol" SG_ 62 GTW_w108_BLEEPREARversionMismatc "GTW_w108_BLEEPREARversionMismatch";
BA_ "SystemSignalLongSymbol" SG_ 62 GTW_w117_unexpectedDestructiveRe "GTW_w117_unexpectedDestructiveResetStatus";
BA_ "SystemSignalLongSymbol" SG_ 62 GTW_w118_unexpectedFunctionalRes "GTW_w118_unexpectedFunctionalResetStatus";
BA_ "SystemSignalLongSymbol" SG_ 62 GTW_w146_performancePackageMisma "GTW_w146_performancePackageMismatch";
BA_ "SystemSignalLongSymbol" SG_ 62 GTW_w227_DISPTOUCHversionMismatc "GTW_w227_DISPTOUCHversionMismatch";
BA_ "SystemSignalLongSymbol" SG_ 62 GTW_w229_displaySoftsetConnectio "GTW_w229_displaySoftsetConnection";
BA_ "SystemSignalLongSymbol" SG_ 62 GTW_w273_BLEEPREARLEFTversionMis "GTW_w273_BLEEPREARLEFTversionMismatch";
BA_ "SystemSignalLongSymbol" SG_ 62 GTW_w274_BLEEPREARRIGHTversionMi "GTW_w274_BLEEPREARRIGHTversionMismatch";
BA_ "SystemSignalLongSymbol" SG_ 62 GTW_w277_NonRevCDrMOSMitigationF "GTW_w277_NonRevCDrMOSMitigationFailed";
BA_ "SystemSignalLongSymbol" SG_ 62 GTW_w282_tcuPhyConfigurationFail "GTW_w282_tcuPhyConfigurationFailed";
BA_ "SystemSignalLongSymbol" SG_ 62 GTW_w311_canLogQueueFullBeforeFs "GTW_w311_canLogQueueFullBeforeFsInit";
BA_ "SystemSignalLongSymbol" SG_ 62 GTW_w317_sdCardChkdskRepairFaile "GTW_w317_sdCardChkdskRepairFailed";
BA_ "SystemSignalLongSymbol" SG_ 62 GTW_w322_gestureUnrecognizedFrom "GTW_w322_gestureUnrecognizedFromMoving";
BA_ "SystemSignalLongSymbol" SG_ 62 GTW_w360_RGBDOORFLversionMismatc "GTW_w360_RGBDOORFLversionMismatch";
BA_ "SystemSignalLongSymbol" SG_ 62 GTW_w361_RGBDOORRLversionMismatc "GTW_w361_RGBDOORRLversionMismatch";
BA_ "SystemSignalLongSymbol" SG_ 62 GTW_w362_RGBDOORFRversionMismatc "GTW_w362_RGBDOORFRversionMismatch";
BA_ "SystemSignalLongSymbol" SG_ 62 GTW_w363_RGBDOORRRversionMismatc "GTW_w363_RGBDOORRRversionMismatch";
BA_ "SystemSignalLongSymbol" SG_ 62 GTW_w364_BLEEPCRADLEversionMisma "GTW_w364_BLEEPCRADLEversionMismatch";
BA_ "SystemSignalLongSymbol" SG_ 62 GTW_w420_unexpectedCanMessageLen "GTW_w420_unexpectedCanMessageLength";
BA_ "SystemSignalLongSymbol" SG_ 62 GTW_w422_ethSwitchSevereCongesti "GTW_w422_ethSwitchSevereCongestionWatchdog";
BA_ "SystemSignalLongSymbol" SG_ 62 GTW_w427_DISPBRIDGEversionMismat "GTW_w427_DISPBRIDGEversionMismatch";
BA_ "SystemSignalLongSymbol" SG_ 62 GTW_w428_LUMBAR32LversionMismatc "GTW_w428_LUMBAR32LversionMismatch";
BA_ "SystemSignalLongSymbol" SG_ 62 GTW_w429_LUMBAR32RversionMismatc "GTW_w429_LUMBAR32RversionMismatch";
BA_ "SystemSignalLongSymbol" SG_ 62 GTW_w437_softFlowControlNotRunni "GTW_w437_softFlowControlNotRunning";
BA_ "SystemSignalLongSymbol" SG_ 62 GTW_w450_unexpectedAutopilotCont "GTW_w450_unexpectedAutopilotControlCanMessage";
BA_ "SystemSignalLongSymbol" SG_ 62 GTW_w455_hrlDumpPageOwnershipErr "GTW_w455_hrlDumpPageOwnershipError";
BA_ "SystemSignalLongSymbol" SG_ 62 GTW_w456_hrlStateMachinePageOwne "GTW_w456_hrlStateMachinePageOwnershipError";
BA_ "Confidence" SG_ 838 GTW_autopilotOverrideState 1;
BA_ "Confidence" SG_ 838 GTW_autopilotConfig 1;
BA_ "Confidence" SG_ 838 GTW_autopilotOverrideConfig 1;
BA_ "Confidence" SG_ 838 GTW_autopilotConfigSource 1;
BA_ "Confidence" SG_ 838 GTW_autopilotOverrideExpireTime 1;
BA_ "Confidence" SG_ 904 GTW_VEH_canBusActivity 1;
BA_ "Confidence" SG_ 904 GTW_PARTY_canBusActivity 1;
BA_ "Confidence" SG_ 904 GTW_CH_canBusActivity 1;
BA_ "Confidence" SG_ 904 GTW_VEH_faultConfinement 1;
BA_ "Confidence" SG_ 904 GTW_PARTY_faultConfinement 1;
BA_ "Confidence" SG_ 904 GTW_CH_faultConfinement 1;
BA_ "Confidence" SG_ 904 GTW_BDY_canBusActivity 1;
BA_ "Confidence" SG_ 904 GTW_BDY_faultConfinement 1;
VAL_ 808 ESP_infoBuildType 4 "INFO_MFG_BUILD" 3 "INFO_TRACEABLE_CI_BUILD" 2 "INFO_LOCAL_BUILD" 1 "INFO_PLATFORM_BUILD" 0 "INFO_UNKNOWN_BUILD" ;
VAL_ 808 ESP_vehFlashMode 1 "Development_Mode" 0 "Production_Mode" ;
VAL_ 808 ESP_infoSubUsageID 16 "XCP_Dfive_ESP_CP_CB" 8 "nonXCP_Dfour_ESP_CP_CB" 4 "XCP_Gladiator_ESP" 2 "nonXCP_Rev_C_ESP_Cappella" 0 "nonXCP_Rev_B_ESP_Cappella" ;
VAL_ 808 ESP_infoVehicleVariant 9 "MODEL_3_VARIANT_09" 8 "MODEL_3_VARIANT_08" 7 "MODEL_3_VARIANT_07" 6 "MODEL_3_VARIANT_06" 5 "MODEL_3_VARIANT_05" 4 "MODEL_3_VARIANT_04" 3 "MODEL_3_VARIANT_03" 2 "MODEL_3_VARIANT_02" 1 "MODEL_3_VARIANT_01" ;
VAL_ 1236 ESP_absActive 1 "ABS_ACTIVE" 0 "ABS_NOT_ACTIVE" ;
VAL_ 1236 ESP_vehicleStandstill 1 "STANDSTILL" 0 "NOT_STANDSTILL" ;
VAL_ 1236 ESP_vehicleStandstillQF 2 "STANDSTILL_FAULTED" 1 "STANDSTILL_NORMAL" 0 "STANDSTILL_NOT_INIT" ;
VAL_ 1236 ESP_privateVehicleSpdQF 2 "Faulty" 1 "Normal" 0 "NotInit_orOff" ;
VAL_ 1236 ESP_brakeMasterCylPressQF 3 "PRESSURE_FAULTED2" 2 "PRESSURE_FAULTED" 1 "PRESSURE_NORMAL" 0 "PRESSURE_NOT_INITIALIZED" ;
VAL_ 325 ESP_espModeActive 3 "ESP_MODE_03" 2 "ESP_MODE_02" 1 "ESP_MODE_01" 0 "ESP_MODE_00_NORMAL" ;
VAL_ 325 ESP_stabilityControlSts2 3 "FAULTED" 2 "ENGAGED" 1 "ON" 0 "INIT" ;
VAL_ 325 ESP_ebdFaultLamp 1 "EBD_FAULT_LAMP_ON" 0 "EBD_FAULT_LAMP_OFF" ;
VAL_ 325 ESP_absFaultLamp 1 "ABS_FAULT_LAMP_ON" 0 "ABS_FAULT_LAMP_OFF" ;
VAL_ 325 ESP_espFaultLamp 1 "ESP_FAULT_LAMP_ON" 0 "ESP_FAULT_LAMP_OFF" ;
VAL_ 325 ESP_espLampFlash 1 "ESP_LAMP_FLASH" 0 "ESP_LAMP_OFF" ;
VAL_ 325 ESP_brakeLamp 1 "LAMP_ON" 0 "LAMP_OFF" ;
VAL_ 325 ESP_absBrakeEvent2 3 "ABS_EVENT_ACTIVE_REAR" 2 "ABS_EVENT_ACTIVE_FRONT" 1 "ABS_EVENT_ACTIVE_FRONT_REAR" 0 "ABS_EVENT_NOT_ACTIVE" ;
VAL_ 325 ESP_longitudinalAccelQF 1 "IN_SPEC" 0 "UNDEFINABLE_ACCURACY" ;
VAL_ 325 ESP_lateralAccelQF 1 "IN_SPEC" 0 "UNDEFINABLE_ACCURACY" ;
VAL_ 325 ESP_yawRateQF 1 "IN_SPEC" 0 "UNDEFINABLE_ACCURACY" ;
VAL_ 325 ESP_steeringAngleQF 1 "IN_SPEC" 0 "UNDEFINABLE_ACCURACY" ;
VAL_ 325 ESP_brakeDiscWipingActive 1 "BDW_ACTIVE" 0 "BDW_INACTIVE" ;
VAL_ 325 ESP_driverBrakeApply 3 "Faulty_SNA" 2 "Driver_applying_brakes" 1 "Not_Applied" 0 "NotInit_orOff" ;
VAL_ 325 ESP_brakeApply 1 "BLS_ACTIVE" 0 "BLS_INACTIVE" ;
VAL_ 325 ESP_aesPrimaryActuatorStatus 3 "AES_FAILURE" 2 "AES_ACTIVE" 1 "AES_AVAILABLE" 0 "AES_NOT_SUPPORTED_OR_NOT_INIT" ;
VAL_ 325 ESP_cdpStatus 3 "CDP_COMMAND_INVALID" 2 "ACTUATING_EPB_CDP" 1 "CDP_IS_AVAILABLE" 0 "CDP_IS_NOT_AVAILABLE" ;
VAL_ 325 ESP_ptcTargetState 2 "ON" 1 "BACKUP" 0 "FAULT" ;
VAL_ 325 ESP_btcTargetState 2 "ON" 1 "BACKUP" 0 "OFF" ;
VAL_ 325 ESP_ebrStandstillSkid 1 "STANDSTILL_SKID_DETECTED" 0 "NO_STANDSTILL_SKID" ;
VAL_ 325 ESP_ebrStatus 3 "EBR_COMMAND_INVALID" 2 "ACTUATING_DI_EBR" 1 "EBR_IS_AVAILABLE" 0 "EBR_IS_NOT_AVAILABLE" ;
VAL_ 1310 FC_infoBuildType 4 "INFO_MFG_BUILD_FC" 3 "INFO_TRACEABLE_CI_BUILD_FC" 2 "INFO_LOCAL_BUILD_FC" 1 "INFO_PLATFORM_BUILD_FC" 0 "INFO_UNKNOWN_BUILD_FC" ;
VAL_ 532 FC_statusCode 15 "FC_STATUS_NODATA" 14 "FC_STATUS_MALFUNCTION" 13 "FC_STATUS_NOTCOMPATIBLE" 7 "FC_STATUS_POST_OUT_OF_SERVICE" 6 "FC_STATUS_EXT_ISOACTIVE" 5 "FC_STATUS_INT_ISOACTIVE" 4 "FC_STATUS_DEPRECATED_4" 3 "FC_STATUS_DEPRECATED_3" 2 "FC_STATUS_UPDATE_IN_PROGRESS" 1 "FC_STATUS_READY" 0 "FC_STATUS_NOTREADY_SNA" ;
VAL_ 532 FC_type 7 "FC_TYPE_SNA" 6 "FC_TYPE_OTHER" 5 "FC_TYPE_MC_EVSE" 4 "FC_TYPE_COMBO" 3 "FC_TYPE_CC_EVSE" 2 "FC_TYPE_GB" 1 "FC_TYPE_CHADEMO" 0 "FC_TYPE_SUPERCHARGER" ;
VAL_ 532 FC_postID 3 "FC_POST_ID_SNA" 2 "FC_POST_ID_2" 1 "FC_POST_SLAVE" 0 "FC_POST_MASTER" ;
VAL_ 535 FC_class 2 "FC_CLASS_URBANCHARGER" 1 "FC_CLASS_SUPERCHARGER" 0 "FC_CLASS_SNA" ;
VAL_ 535 FC_coolingType 3 "FC_COOLING_TYPE_IMMERSION" 2 "FC_COOLING_TYPE_CONVECTION" 1 "FC_COOLING_TYPE_LIQUID" 0 "FC_COOLING_TYPE_SNA" ;
VAL_ 535 FC_uiStopType 2 "FC_UI_STOP_TYPE_MOMENTARY" 1 "FC_UI_STOP_TYPE_TOGGLE" 0 "FC_UI_STOP_TYPE_SNA" ;
VAL_ 838 GTW_autopilotOverrideState 8 "UNKNOWN" 7 "VEHICLE_MANAGED" 6 "OPTION_OVERRIDE" 5 "OPTION_CODE" 4 "TIMEBOUND_TRIAL" 3 "TIMEBOUND_SUBSCRIPTION" 2 "TRIAL" 1 "SUBSCRIPTION" 0 "BASE" ;
VAL_ 838 GTW_autopilotConfig 4 "BASIC" 3 "SELF_DRIVING" 2 "ENHANCED" 1 "HIGHWAY" 0 "NONE" ;
VAL_ 838 GTW_autopilotOverrideConfig 4 "BASIC" 3 "SELF_DRIVING" 2 "ENHANCED" 1 "HIGHWAY" 0 "NONE" ;
VAL_ 838 GTW_autopilotConfigSource 2 "AUTOPILOT_NOT_UPDATED" 1 "AUTOPILOT" 0 "GATEWAY" ;
VAL_ 904 GTW_VEH_faultConfinement 2 "BUS_OFF" 1 "ERROR_PASSIVE" 0 "ERROR_ACTIVE" ;
VAL_ 904 GTW_PARTY_faultConfinement 2 "BUS_OFF" 1 "ERROR_PASSIVE" 0 "ERROR_ACTIVE" ;
VAL_ 904 GTW_CH_faultConfinement 2 "BUS_OFF" 1 "ERROR_PASSIVE" 0 "ERROR_ACTIVE" ;
VAL_ 904 GTW_BDY_faultConfinement 2 "BUS_OFF" 1 "ERROR_PASSIVE" 0 "ERROR_ACTIVE" ;
